VERSION "HNPBNNNYNNNNNNNNNNNNNNNNNNNNNNNNYNYYYYYYYY>4>%%%/4>'%**4YYY///"

NS_ :

BS_:

BU_: TPM TCM SCCM RF_HUB PTS ORC IC HaLF ETM ESM ESC EPS ECM Diagnost DTCM DASM CBC AFLS ADCM

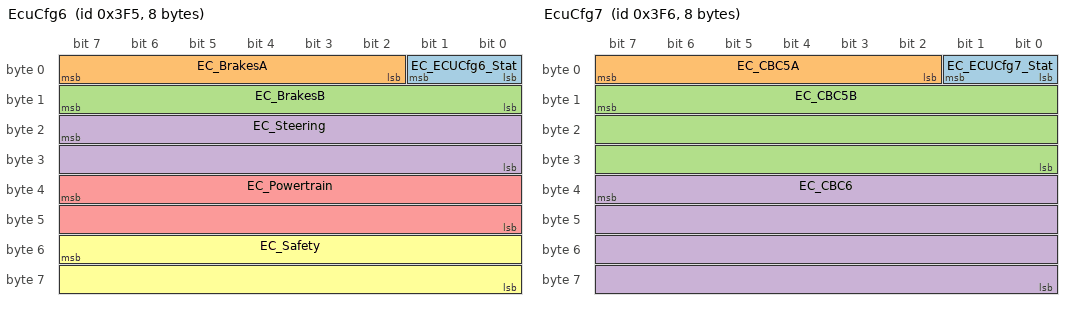
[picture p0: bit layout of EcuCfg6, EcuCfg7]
BO_ 1013 EcuCfg6: 8 CBC
 SG_ EC_ECUCfg6_Stat : 0|2@1+ (1,0) [0|0] ""  ORC,TCM,ECM,ESC,EPS,RF_HUB
 SG_ EC_BrakesA : 2|6@1+ (1,0) [0|0] ""  ESC,RF_HUB
 SG_ EC_BrakesB : 8|8@1+ (1,0) [0|0] ""  ESC,RF_HUB
 SG_ EC_Steering : 23|16@0+ (1,0) [0|0] ""  EPS,RF_HUB
 SG_ EC_Powertrain : 39|16@0+ (1,0) [0|0] ""  TCM,ECM,RF_HUB
 SG_ EC_Safety : 55|16@0+ (1,0) [0|0] ""  ORC,RF_HUB

BO_ 1014 EcuCfg7: 8 CBC
 SG_ EC_ECUCfg7_Stat : 0|2@1+ (1,0) [0|0] ""  RF_HUB
 SG_ EC_CBC5A : 2|6@1+ (1,0) [0|0] ""  RF_HUB
 SG_ EC_CBC5B : 15|24@0+ (1,0) [0|0] ""  RF_HUB
 SG_ EC_CBC6 : 39|32@0+ (1,0) [0|0] ""  RF_HUB

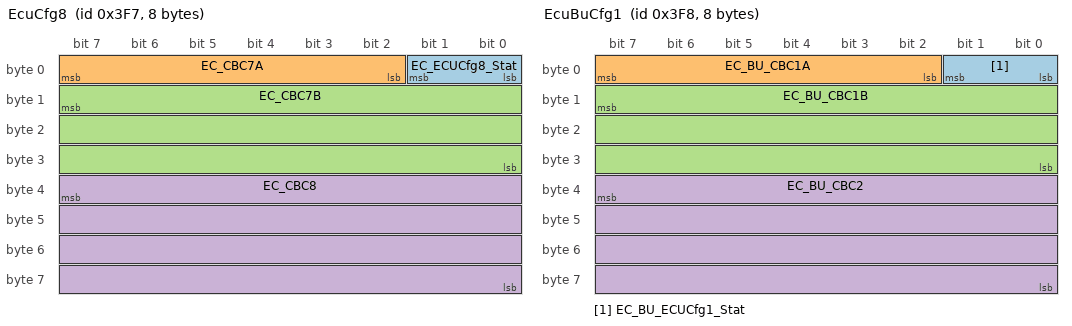
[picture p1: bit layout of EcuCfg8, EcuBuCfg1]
BO_ 1015 EcuCfg8: 8 CBC
 SG_ EC_ECUCfg8_Stat : 0|2@1+ (1,0) [0|0] ""  RF_HUB
 SG_ EC_CBC7A : 2|6@1+ (1,0) [0|0] ""  RF_HUB
 SG_ EC_CBC7B : 15|24@0+ (1,0) [0|0] ""  RF_HUB
 SG_ EC_CBC8 : 39|32@0+ (1,0) [0|0] ""  RF_HUB

BO_ 1016 EcuBuCfg1: 8 RF_HUB
 SG_ EC_BU_ECUCfg1_Stat : 0|2@1+ (1,0) [0|0] ""  CBC
 SG_ EC_BU_CBC1A : 2|6@1+ (1,0) [0|0] ""  CBC
 SG_ EC_BU_CBC1B : 15|24@0+ (1,0) [0|0] ""  CBC
 SG_ EC_BU_CBC2 : 39|32@0+ (1,0) [0|0] ""  CBC

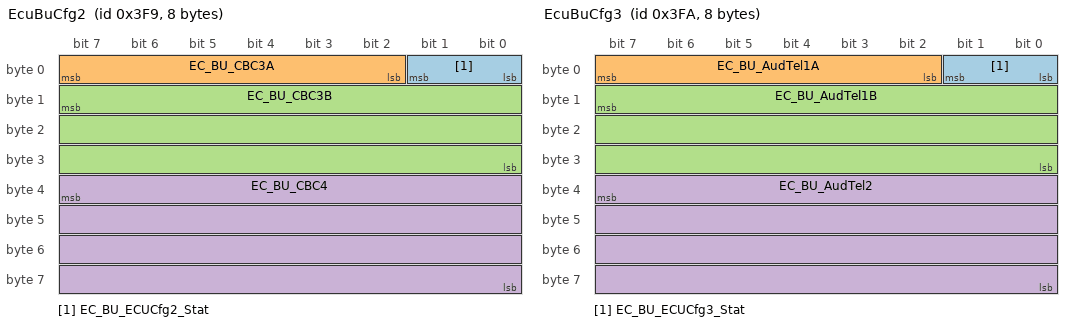
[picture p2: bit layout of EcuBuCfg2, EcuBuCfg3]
BO_ 1017 EcuBuCfg2: 8 RF_HUB
 SG_ EC_BU_ECUCfg2_Stat : 0|2@1+ (1,0) [0|0] ""  CBC
 SG_ EC_BU_CBC3A : 2|6@1+ (1,0) [0|0] ""  CBC
 SG_ EC_BU_CBC3B : 15|24@0+ (1,0) [0|0] ""  CBC
 SG_ EC_BU_CBC4 : 39|32@0+ (1,0) [0|0] ""  CBC

BO_ 1018 EcuBuCfg3: 8 RF_HUB
 SG_ EC_BU_ECUCfg3_Stat : 0|2@1+ (1,0) [0|0] ""  CBC
 SG_ EC_BU_AudTel1A : 2|6@1+ (1,0) [0|0] ""  CBC
 SG_ EC_BU_AudTel1B : 15|24@0+ (1,0) [0|0] ""  CBC
 SG_ EC_BU_AudTel2 : 39|32@0+ (1,0) [0|0] ""  CBC

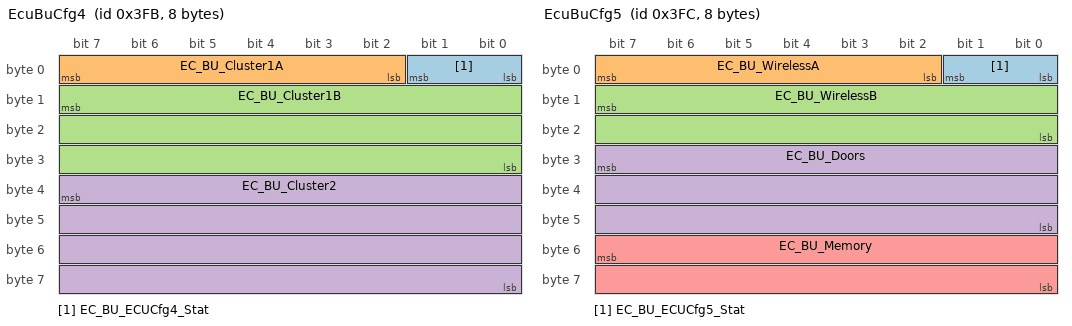
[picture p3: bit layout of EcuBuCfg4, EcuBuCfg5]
BO_ 1019 EcuBuCfg4: 8 RF_HUB
 SG_ EC_BU_ECUCfg4_Stat : 0|2@1+ (1,0) [0|0] ""  CBC
 SG_ EC_BU_Cluster1A : 2|6@1+ (1,0) [0|0] ""  CBC
 SG_ EC_BU_Cluster1B : 15|24@0+ (1,0) [0|0] ""  CBC
 SG_ EC_BU_Cluster2 : 39|32@0+ (1,0) [0|0] ""  CBC

BO_ 1020 EcuBuCfg5: 8 RF_HUB
 SG_ EC_BU_ECUCfg5_Stat : 0|2@1+ (1,0) [0|0] ""  CBC
 SG_ EC_BU_WirelessA : 2|6@1+ (1,0) [0|0] ""  CBC
 SG_ EC_BU_WirelessB : 15|16@0+ (1,0) [0|0] ""  CBC
 SG_ EC_BU_Doors : 31|24@0+ (1,0) [0|0] ""  CBC
 SG_ EC_BU_Memory : 55|16@0+ (1,0) [0|0] ""  CBC

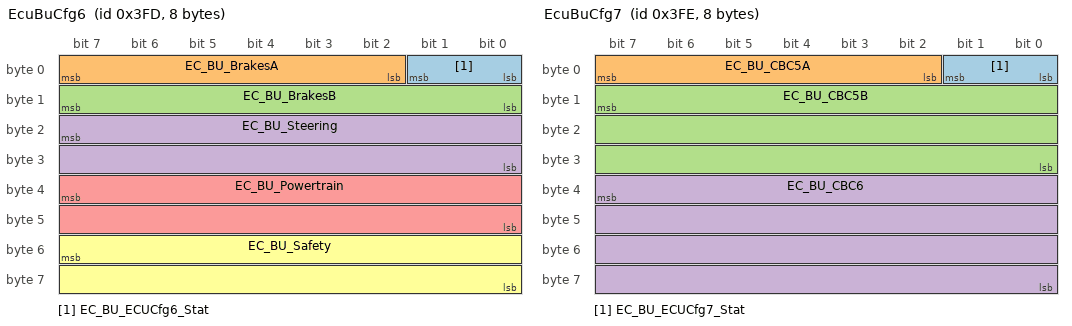
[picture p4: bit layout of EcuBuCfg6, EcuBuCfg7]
BO_ 1021 EcuBuCfg6: 8 RF_HUB
 SG_ EC_BU_ECUCfg6_Stat : 0|2@1+ (1,0) [0|0] ""  CBC
 SG_ EC_BU_BrakesA : 2|6@1+ (1,0) [0|0] ""  CBC
 SG_ EC_BU_BrakesB : 8|8@1+ (1,0) [0|0] ""  CBC
 SG_ EC_BU_Steering : 23|16@0+ (1,0) [0|0] ""  CBC
 SG_ EC_BU_Powertrain : 39|16@0+ (1,0) [0|0] ""  CBC
 SG_ EC_BU_Safety : 55|16@0+ (1,0) [0|0] ""  CBC

BO_ 1022 EcuBuCfg7: 8 RF_HUB
 SG_ EC_BU_ECUCfg7_Stat : 0|2@1+ (1,0) [0|0] ""  CBC
 SG_ EC_BU_CBC5A : 2|6@1+ (1,0) [0|0] ""  CBC
 SG_ EC_BU_CBC5B : 15|24@0+ (1,0) [0|0] ""  CBC
 SG_ EC_BU_CBC6 : 39|32@0+ (1,0) [0|0] ""  CBC

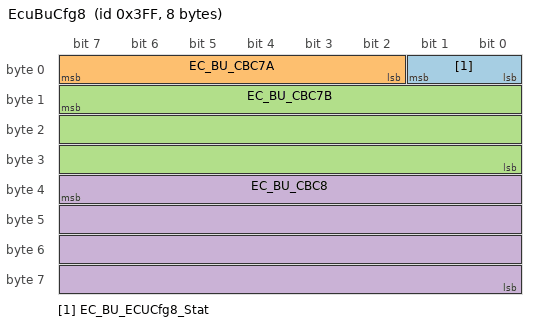
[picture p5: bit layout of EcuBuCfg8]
BO_ 1023 EcuBuCfg8: 8 RF_HUB
 SG_ EC_BU_ECUCfg8_Stat : 0|2@1+ (1,0) [0|0] ""  CBC
 SG_ EC_BU_CBC7A : 2|6@1+ (1,0) [0|0] ""  CBC
 SG_ EC_BU_CBC7B : 15|24@0+ (1,0) [0|0] ""  CBC
 SG_ EC_BU_CBC8 : 39|32@0+ (1,0) [0|0] ""  CBC

BO_ 1024 NM_RF_HUB: 8 RF_HUB
 SG_ NM_Mode : 0|8@1+ (1,0) [0|0] ""  ESM,ESC,SCCM,EPS,TPM,PTS,IC,CBC,RF_HUB
 SG_ NM_Successor : 8|8@1+ (1,0) [0|63] ""  ESM,ESC,SCCM,EPS,TPM,PTS,IC,CBC,RF_HUB
 SG_ NM_Ud_Launch : 16|6@1+ (1,0) [0|0] ""  ESM,ESC,SCCM,EPS,TPM,PTS,IC,CBC,RF_HUB
 SG_ NM_Sleep_Ack : 22|1@1+ (1,0) [0|0] ""  ESM,ESC,SCCM,EPS,TPM,PTS,IC,CBC,RF_HUB
 SG_ NM_Sleep_Ind : 23|1@1+ (1,0) [0|0] ""  ESM,ESC,SCCM,EPS,TPM,PTS,IC,CBC,RF_HUB
 SG_ NM_Ud_Srv M : 24|8@1+ (1,0) [0|0] ""  ESM,ESC,SCCM,EPS,TPM,PTS,IC,CBC,RF_HUB
 SG_ Awake_NwSt m15 : 32|1@1+ (1,0) [0|0] ""  ESM,ESC,SCCM,EPS,TPM,PTS,IC,CBC,RF_HUB
 SG_ WakeupRsn_RF_HUB m2 : 32|8@1+ (1,0) [0|0] ""  ESM,ESC,SCCM,EPS,TPM,PTS,IC,CBC,RF_HUB
 SG_ Awake_Diag_Actv m15 : 33|1@1+ (1,0) [0|0] ""  ESM,ESC,SCCM,EPS,TPM,PTS,IC,CBC,RF_HUB
 SG_ WakeupCnt m2 : 40|8@1+ (1,0) [0|254] ""  ESM,ESC,SCCM,EPS,TPM,PTS,IC,CBC,RF_HUB
 SG_ Nw_Id : 56|8@1+ (1,0) [0|0] ""  ESM,ESC,SCCM,EPS,TPM,PTS,IC,CBC,RF_HUB

BO_ 1025 NM_CBC: 8 CBC
 SG_ NM_Mode : 0|8@1+ (1,0) [0|0] ""  ESM,ESC,SCCM,EPS,TPM,PTS,IC,CBC,RF_HUB
 SG_ NM_Successor : 8|8@1+ (1,0) [0|63] ""  ESM,ESC,SCCM,EPS,TPM,PTS,IC,CBC,RF_HUB
 SG_ NM_Ud_Launch : 16|6@1+ (1,0) [0|0] ""  ESM,ESC,SCCM,EPS,TPM,PTS,IC,CBC,RF_HUB
 SG_ NM_Sleep_Ack : 22|1@1+ (1,0) [0|0] ""  ESM,ESC,SCCM,EPS,TPM,PTS,IC,CBC,RF_HUB
 SG_ NM_Sleep_Ind : 23|1@1+ (1,0) [0|0] ""  ESM,ESC,SCCM,EPS,TPM,PTS,IC,CBC,RF_HUB
 SG_ NM_Ud_Srv M : 24|8@1+ (1,0) [0|0] ""  ESM,ESC,SCCM,EPS,TPM,PTS,IC,CBC,RF_HUB
 SG_ Awake_NwSt m15 : 32|1@1+ (1,0) [0|0] ""  ESM,ESC,SCCM,EPS,TPM,PTS,IC,CBC,RF_HUB
 SG_ WakeupRsn_CBC m2 : 32|8@1+ (1,0) [0|0] ""  ESM,ESC,SCCM,EPS,TPM,PTS,IC,CBC,RF_HUB
 SG_ Awake_Diag_Actv m15 : 33|1@1+ (1,0) [0|0] ""  ESM,ESC,SCCM,EPS,TPM,PTS,IC,CBC,RF_HUB
 SG_ WakeupCnt m2 : 40|8@1+ (1,0) [0|254] ""  ESM,ESC,SCCM,EPS,TPM,PTS,IC,CBC,RF_HUB
 SG_ Nw_Id : 56|8@1+ (1,0) [0|0] ""  ESM,ESC,SCCM,EPS,TPM,PTS,IC,CBC,RF_HUB

BO_ 1026 NM_IC: 8 IC
 SG_ NM_Mode : 0|8@1+ (1,0) [0|0] ""  ESM,ESC,SCCM,EPS,TPM,PTS,IC,CBC,RF_HUB
 SG_ NM_Successor : 8|8@1+ (1,0) [0|63] ""  ESM,ESC,SCCM,EPS,TPM,PTS,IC,CBC,RF_HUB
 SG_ NM_Ud_Launch : 16|6@1+ (1,0) [0|0] ""  ESM,ESC,SCCM,EPS,TPM,PTS,IC,CBC,RF_HUB
 SG_ NM_Sleep_Ack : 22|1@1+ (1,0) [0|0] ""  ESM,ESC,SCCM,EPS,TPM,PTS,IC,CBC,RF_HUB
 SG_ NM_Sleep_Ind : 23|1@1+ (1,0) [0|0] ""  ESM,ESC,SCCM,EPS,TPM,PTS,IC,CBC,RF_HUB
 SG_ NM_Ud_Srv M : 24|8@1+ (1,0) [0|0] ""  ESM,ESC,SCCM,EPS,TPM,PTS,IC,CBC,RF_HUB
 SG_ Awake_NwSt m15 : 32|1@1+ (1,0) [0|0] ""  ESM,ESC,SCCM,EPS,TPM,PTS,IC,CBC,RF_HUB
 SG_ WakeupRsn_IC m2 : 32|8@1+ (1,0) [0|0] ""  ESM,ESC,SCCM,EPS,TPM,PTS,IC,CBC,RF_HUB
 SG_ Awake_Diag_Actv m15 : 33|1@1+ (1,0) [0|0] ""  ESM,ESC,SCCM,EPS,TPM,PTS,IC,CBC,RF_HUB
 SG_ WakeupCnt m2 : 40|8@1+ (1,0) [0|254] ""  ESM,ESC,SCCM,EPS,TPM,PTS,IC,CBC,RF_HUB
 SG_ Nw_Id : 56|8@1+ (1,0) [0|0] ""  ESM,ESC,SCCM,EPS,TPM,PTS,IC,CBC,RF_HUB

BO_ 1027 NM_TPM: 8 TPM
 SG_ NM_Mode : 0|8@1+ (1,0) [0|0] ""  ESM,ESC,SCCM,EPS,TPM,PTS,IC,CBC,RF_HUB
 SG_ NM_Successor : 8|8@1+ (1,0) [0|63] ""  ESM,ESC,SCCM,EPS,TPM,PTS,IC,CBC,RF_HUB
 SG_ NM_Ud_Launch : 16|6@1+ (1,0) [0|0] ""  ESM,ESC,SCCM,EPS,TPM,PTS,IC,CBC,RF_HUB
 SG_ NM_Sleep_Ack : 22|1@1+ (1,0) [0|0] ""  ESM,ESC,SCCM,EPS,TPM,PTS,IC,CBC,RF_HUB
 SG_ NM_Sleep_Ind : 23|1@1+ (1,0) [0|0] ""  ESM,ESC,SCCM,EPS,TPM,PTS,IC,CBC,RF_HUB
 SG_ NM_Ud_Srv M : 24|8@1+ (1,0) [0|0] ""  ESM,ESC,SCCM,EPS,TPM,PTS,IC,CBC,RF_HUB
 SG_ Awake_NwSt m15 : 32|1@1+ (1,0) [0|0] ""  ESM,ESC,SCCM,EPS,TPM,PTS,IC,CBC,RF_HUB
 SG_ WakeupRsn_TPM m2 : 32|8@1+ (1,0) [0|0] ""  ESM,ESC,SCCM,EPS,TPM,PTS,IC,CBC,RF_HUB
 SG_ Awake_Diag_Actv m15 : 33|1@1+ (1,0) [0|0] ""  ESM,ESC,SCCM,EPS,TPM,PTS,IC,CBC,RF_HUB
 SG_ WakeupCnt m2 : 40|8@1+ (1,0) [0|254] ""  ESM,ESC,SCCM,EPS,TPM,PTS,IC,CBC,RF_HUB
 SG_ Nw_Id : 56|8@1+ (1,0) [0|0] ""  ESM,ESC,SCCM,EPS,TPM,PTS,IC,CBC,RF_HUB

BO_ 1029 NM_RBT_D: 8 Vector__XXX
 SG_ NM_Mode : 0|8@1+ (1,0) [0|0] ""  ESM,ESC,SCCM,EPS,TPM,PTS,IC,CBC,RF_HUB
 SG_ NM_Successor : 8|8@1+ (1,0) [0|63] ""  ESM,ESC,SCCM,EPS,TPM,PTS,IC,CBC,RF_HUB
 SG_ NM_Ud_Launch : 16|6@1+ (1,0) [0|0] ""  ESM,ESC,SCCM,EPS,TPM,PTS,IC,CBC,RF_HUB
 SG_ NM_Sleep_Ack : 22|1@1+ (1,0) [0|0] ""  ESM,ESC,SCCM,EPS,TPM,PTS,IC,CBC,RF_HUB
 SG_ NM_Sleep_Ind : 23|1@1+ (1,0) [0|0] ""  ESM,ESC,SCCM,EPS,TPM,PTS,IC,CBC,RF_HUB
 SG_ NM_Ud_Srv M : 24|8@1+ (1,0) [0|0] ""  ESM,ESC,SCCM,EPS,TPM,PTS,IC,CBC,RF_HUB
 SG_ Awake_NwSt m15 : 32|1@1+ (1,0) [0|0] ""  ESM,ESC,SCCM,EPS,TPM,PTS,IC,CBC,RF_HUB
 SG_ WakeupRsn_RBT_DR m2 : 32|8@1+ (1,0) [0|0] ""  ESM,ESC,SCCM,EPS,TPM,PTS,IC,CBC,RF_HUB
 SG_ Awake_Diag_Actv m15 : 33|1@1+ (1,0) [0|0] ""  ESM,ESC,SCCM,EPS,TPM,PTS,IC,CBC,RF_HUB
 SG_ WakeupCnt m2 : 40|8@1+ (1,0) [0|254] ""  ESM,ESC,SCCM,EPS,TPM,PTS,IC,CBC,RF_HUB
 SG_ Nw_Id : 56|8@1+ (1,0) [0|0] ""  ESM,ESC,SCCM,EPS,TPM,PTS,IC,CBC,RF_HUB

BO_ 1030 NM_RBT_P: 8 Vector__XXX
 SG_ NM_Mode : 0|8@1+ (1,0) [0|0] ""  ESM,ESC,SCCM,EPS,TPM,PTS,IC,CBC,RF_HUB
 SG_ NM_Successor : 8|8@1+ (1,0) [0|63] ""  ESM,ESC,SCCM,EPS,TPM,PTS,IC,CBC,RF_HUB
 SG_ NM_Ud_Launch : 16|6@1+ (1,0) [0|0] ""  ESM,ESC,SCCM,EPS,TPM,PTS,IC,CBC,RF_HUB
 SG_ NM_Sleep_Ack : 22|1@1+ (1,0) [0|0] ""  ESM,ESC,SCCM,EPS,TPM,PTS,IC,CBC,RF_HUB
 SG_ NM_Sleep_Ind : 23|1@1+ (1,0) [0|0] ""  ESM,ESC,SCCM,EPS,TPM,PTS,IC,CBC,RF_HUB
 SG_ NM_Ud_Srv M : 24|8@1+ (1,0) [0|0] ""  ESM,ESC,SCCM,EPS,TPM,PTS,IC,CBC,RF_HUB
 SG_ Awake_NwSt m15 : 32|1@1+ (1,0) [0|0] ""  ESM,ESC,SCCM,EPS,TPM,PTS,IC,CBC,RF_HUB
 SG_ WakeupRsn_RBT_PASS m2 : 32|8@1+ (1,0) [0|0] ""  ESM,ESC,SCCM,EPS,TPM,PTS,IC,CBC,RF_HUB
 SG_ Awake_Diag_Actv m15 : 33|1@1+ (1,0) [0|0] ""  ESM,ESC,SCCM,EPS,TPM,PTS,IC,CBC,RF_HUB
 SG_ WakeupCnt m2 : 40|8@1+ (1,0) [0|254] ""  ESM,ESC,SCCM,EPS,TPM,PTS,IC,CBC,RF_HUB
 SG_ Nw_Id : 56|8@1+ (1,0) [0|0] ""  ESM,ESC,SCCM,EPS,TPM,PTS,IC,CBC,RF_HUB

BO_ 1031 NM_ESC: 8 ESC
 SG_ NM_Mode : 0|8@1+ (1,0) [0|0] ""  ESM,ESC,SCCM,EPS,TPM,PTS,IC,CBC,RF_HUB
 SG_ NM_Successor : 8|8@1+ (1,0) [0|63] ""  ESM,ESC,SCCM,EPS,TPM,PTS,IC,CBC,RF_HUB
 SG_ NM_Ud_Launch : 16|6@1+ (1,0) [0|0] ""  ESM,ESC,SCCM,EPS,TPM,PTS,IC,CBC,RF_HUB
 SG_ NM_Sleep_Ack : 22|1@1+ (1,0) [0|0] ""  ESM,ESC,SCCM,EPS,TPM,PTS,IC,CBC,RF_HUB
 SG_ NM_Sleep_Ind : 23|1@1+ (1,0) [0|0] ""  ESM,ESC,SCCM,EPS,TPM,PTS,IC,CBC,RF_HUB
 SG_ NM_Ud_Srv M : 24|8@1+ (1,0) [0|0] ""  ESM,ESC,SCCM,EPS,TPM,PTS,IC,CBC,RF_HUB
 SG_ Awake_NwSt m15 : 32|1@1+ (1,0) [0|0] ""  ESM,ESC,SCCM,EPS,TPM,PTS,IC,CBC,RF_HUB
 SG_ WakeupRsn_ESC m2 : 32|8@1+ (1,0) [0|0] ""  ESM,ESC,SCCM,EPS,TPM,PTS,IC,CBC,RF_HUB
 SG_ Awake_Diag_Actv m15 : 33|1@1+ (1,0) [0|0] ""  ESM,ESC,SCCM,EPS,TPM,PTS,IC,CBC,RF_HUB
 SG_ WakeupCnt m2 : 40|8@1+ (1,0) [0|254] ""  ESM,ESC,SCCM,EPS,TPM,PTS,IC,CBC,RF_HUB
 SG_ Nw_Id : 56|8@1+ (1,0) [0|0] ""  ESM,ESC,SCCM,EPS,TPM,PTS,IC,CBC,RF_HUB

BO_ 1033 NM_SBWM: 8 ESM
 SG_ NM_Mode : 0|8@1+ (1,0) [0|0] ""  ESM,ESC,SCCM,EPS,TPM,PTS,IC,CBC,RF_HUB
 SG_ NM_Successor : 8|8@1+ (1,0) [0|63] ""  ESM,ESC,SCCM,EPS,TPM,PTS,IC,CBC,RF_HUB
 SG_ NM_Ud_Launch : 16|6@1+ (1,0) [0|0] ""  ESM,ESC,SCCM,EPS,TPM,PTS,IC,CBC,RF_HUB
 SG_ NM_Sleep_Ack : 22|1@1+ (1,0) [0|0] ""  ESM,ESC,SCCM,EPS,TPM,PTS,IC,CBC,RF_HUB
 SG_ NM_Sleep_Ind : 23|1@1+ (1,0) [0|0] ""  ESM,ESC,SCCM,EPS,TPM,PTS,IC,CBC,RF_HUB
 SG_ NM_Ud_Srv M : 24|8@1+ (1,0) [0|0] ""  ESM,ESC,SCCM,EPS,TPM,PTS,IC,CBC,RF_HUB
 SG_ Awake_NwSt m15 : 32|1@1+ (1,0) [0|0] ""  ESM,ESC,SCCM,EPS,TPM,PTS,IC,CBC,RF_HUB
 SG_ WakeupRsn_SBWM m2 : 32|8@1+ (1,0) [0|0] ""  ESM,ESC,SCCM,EPS,TPM,PTS,IC,CBC,RF_HUB
 SG_ Awake_Diag_Actv m15 : 33|1@1+ (1,0) [0|0] ""  ESM,ESC,SCCM,EPS,TPM,PTS,IC,CBC,RF_HUB
 SG_ Awake_Ignition_On m15 : 34|1@1+ (1,0) [0|0] ""  ESM,ESC,SCCM,EPS,TPM,PTS,IC,CBC,RF_HUB
 SG_ Awake_EEPROM m15 : 35|1@1+ (1,0) [0|0] ""  ESM,ESC,SCCM,EPS,TPM,PTS,IC,CBC,RF_HUB
 SG_ Awake_URS m15 : 36|1@1+ (1,0) [0|0] ""  ESM,ESC,SCCM,EPS,TPM,PTS,IC,CBC,RF_HUB
 SG_ WakeupCnt m2 : 40|8@1+ (1,0) [0|254] ""  ESM,ESC,SCCM,EPS,TPM,PTS,IC,CBC,RF_HUB
 SG_ Nw_Id : 56|8@1+ (1,0) [0|0] ""  ESM,ESC,SCCM,EPS,TPM,PTS,IC,CBC,RF_HUB

BO_ 1044 NM_ITBM: 8 Vector__XXX
 SG_ NM_Mode : 0|8@1+ (1,0) [0|0] ""  ESM,ESC,SCCM,EPS,TPM,PTS,IC,CBC,RF_HUB
 SG_ NM_Successor : 8|8@1+ (1,0) [0|63] ""  ESM,ESC,SCCM,EPS,TPM,PTS,IC,CBC,RF_HUB
 SG_ NM_Ud_Launch : 16|6@1+ (1,0) [0|0] ""  ESM,ESC,SCCM,EPS,TPM,PTS,IC,CBC,RF_HUB
 SG_ NM_Sleep_Ack : 22|1@1+ (1,0) [0|0] ""  ESM,ESC,SCCM,EPS,TPM,PTS,IC,CBC,RF_HUB
 SG_ NM_Sleep_Ind : 23|1@1+ (1,0) [0|0] ""  ESM,ESC,SCCM,EPS,TPM,PTS,IC,CBC,RF_HUB
 SG_ NM_Ud_Srv M : 24|8@1+ (1,0) [0|0] ""  ESM,ESC,SCCM,EPS,TPM,PTS,IC,CBC,RF_HUB
 SG_ Awake_NwSt m15 : 32|1@1+ (1,0) [0|0] ""  ESM,ESC,SCCM,EPS,TPM,PTS,IC,CBC,RF_HUB
 SG_ WakeupRsn_ITBM m2 : 32|8@1+ (1,0) [0|0] ""  ESM,ESC,SCCM,EPS,TPM,PTS,IC,CBC,RF_HUB
 SG_ Awake_Diag_Actv m15 : 33|1@1+ (1,0) [0|0] ""  ESM,ESC,SCCM,EPS,TPM,PTS,IC,CBC,RF_HUB
 SG_ WakeupCnt m2 : 40|8@1+ (1,0) [0|254] ""  ESM,ESC,SCCM,EPS,TPM,PTS,IC,CBC,RF_HUB
 SG_ Nw_Id : 56|8@1+ (1,0) [0|0] ""  ESM,ESC,SCCM,EPS,TPM,PTS,IC,CBC,RF_HUB

BO_ 1049 NM_EPB: 8 Vector__XXX
 SG_ NM_Mode : 0|8@1+ (1,0) [0|0] ""  ESM,ESC,SCCM,EPS,TPM,PTS,IC,CBC,RF_HUB
 SG_ NM_Successor : 8|8@1+ (1,0) [0|63] ""  ESM,ESC,SCCM,EPS,TPM,PTS,IC,CBC,RF_HUB
 SG_ NM_Ud_Launch : 16|6@1+ (1,0) [0|0] ""  ESM,ESC,SCCM,EPS,TPM,PTS,IC,CBC,RF_HUB
 SG_ NM_Sleep_Ack : 22|1@1+ (1,0) [0|0] ""  ESM,ESC,SCCM,EPS,TPM,PTS,IC,CBC,RF_HUB
 SG_ NM_Sleep_Ind : 23|1@1+ (1,0) [0|0] ""  ESM,ESC,SCCM,EPS,TPM,PTS,IC,CBC,RF_HUB
 SG_ NM_Ud_Srv M : 24|8@1+ (1,0) [0|0] ""  ESM,ESC,SCCM,EPS,TPM,PTS,IC,CBC,RF_HUB
 SG_ Awake_NwSt m15 : 32|1@1+ (1,0) [0|0] ""  ESM,ESC,SCCM,EPS,TPM,PTS,IC,CBC,RF_HUB
 SG_ WakeupRsn_EPB m2 : 32|8@1+ (1,0) [0|0] ""  ESM,ESC,SCCM,EPS,TPM,PTS,IC,CBC,RF_HUB
 SG_ Awake_Diag_Actv m15 : 33|1@1+ (1,0) [0|0] ""  ESM,ESC,SCCM,EPS,TPM,PTS,IC,CBC,RF_HUB
 SG_ WakeupCnt m2 : 40|8@1+ (1,0) [0|254] ""  ESM,ESC,SCCM,EPS,TPM,PTS,IC,CBC,RF_HUB
 SG_ Nw_Id : 56|8@1+ (1,0) [0|0] ""  ESM,ESC,SCCM,EPS,TPM,PTS,IC,CBC,RF_HUB

BO_ 1050 NM_EPS: 8 EPS
 SG_ NM_Mode : 0|8@1+ (1,0) [0|0] ""  ESM,ESC,SCCM,EPS,TPM,PTS,IC,CBC,RF_HUB
 SG_ NM_Successor : 8|8@1+ (1,0) [0|63] ""  ESM,ESC,SCCM,EPS,TPM,PTS,IC,CBC,RF_HUB
 SG_ NM_Ud_Launch : 16|6@1+ (1,0) [0|0] ""  ESM,ESC,SCCM,EPS,TPM,PTS,IC,CBC,RF_HUB
 SG_ NM_Sleep_Ack : 22|1@1+ (1,0) [0|0] ""  ESM,ESC,SCCM,EPS,TPM,PTS,IC,CBC,RF_HUB
 SG_ NM_Sleep_Ind : 23|1@1+ (1,0) [0|0] ""  ESM,ESC,SCCM,EPS,TPM,PTS,IC,CBC,RF_HUB
 SG_ NM_Ud_Srv M : 24|8@1+ (1,0) [0|0] ""  ESM,ESC,SCCM,EPS,TPM,PTS,IC,CBC,RF_HUB
 SG_ Awake_NwSt m15 : 32|1@1+ (1,0) [0|0] ""  ESM,ESC,SCCM,EPS,TPM,PTS,IC,CBC,RF_HUB
 SG_ WakeupRsn_EPS m2 : 32|8@1+ (1,0) [0|0] ""  ESM,ESC,SCCM,EPS,TPM,PTS,IC,CBC,RF_HUB
 SG_ Awake_Diag_Actv m15 : 33|1@1+ (1,0) [0|0] ""  ESM,ESC,SCCM,EPS,TPM,PTS,IC,CBC,RF_HUB
 SG_ Awake_Rampout m15 : 34|1@1+ (1,0) [0|0] ""  ESM,ESC,SCCM,EPS,TPM,PTS,IC,CBC,RF_HUB
 SG_ Awake_VSS_high m15 : 35|1@1+ (1,0) [0|0] ""  ESM,ESC,SCCM,EPS,TPM,PTS,IC,CBC,RF_HUB
 SG_ Awake_EngRPM_high m15 : 36|1@1+ (1,0) [0|0] ""  ESM,ESC,SCCM,EPS,TPM,PTS,IC,CBC,RF_HUB
 SG_ Awake_IgnHigh m15 : 37|1@1+ (1,0) [0|0] ""  ESM,ESC,SCCM,EPS,TPM,PTS,IC,CBC,RF_HUB
 SG_ WakeupCnt m2 : 40|8@1+ (1,0) [0|254] ""  ESM,ESC,SCCM,EPS,TPM,PTS,IC,CBC,RF_HUB
 SG_ Nw_Id : 56|8@1+ (1,0) [0|0] ""  ESM,ESC,SCCM,EPS,TPM,PTS,IC,CBC,RF_HUB

BO_ 1058 NM_PTS: 8 PTS
 SG_ NM_Mode : 0|8@1+ (1,0) [0|0] ""  ESM,ESC,SCCM,EPS,TPM,PTS,IC,CBC,RF_HUB
 SG_ NM_Successor : 8|8@1+ (1,0) [0|63] ""  ESM,ESC,SCCM,EPS,TPM,PTS,IC,CBC,RF_HUB
 SG_ NM_Ud_Launch : 16|6@1+ (1,0) [0|0] ""  ESM,ESC,SCCM,EPS,TPM,PTS,IC,CBC,RF_HUB
 SG_ NM_Sleep_Ack : 22|1@1+ (1,0) [0|0] ""  ESM,ESC,SCCM,EPS,TPM,PTS,IC,CBC,RF_HUB
 SG_ NM_Sleep_Ind : 23|1@1+ (1,0) [0|0] ""  ESM,ESC,SCCM,EPS,TPM,PTS,IC,CBC,RF_HUB
 SG_ NM_Ud_Srv M : 24|8@1+ (1,0) [0|0] ""  ESM,ESC,SCCM,EPS,TPM,PTS,IC,CBC,RF_HUB
 SG_ Awake_NwSt m15 : 32|1@1+ (1,0) [0|0] ""  ESM,ESC,SCCM,EPS,TPM,PTS,IC,CBC,RF_HUB
 SG_ WakeupRsn_PTS m2 : 32|8@1+ (1,0) [0|0] ""  ESM,ESC,SCCM,EPS,TPM,PTS,IC,CBC,RF_HUB
 SG_ Awake_Diag_Actv m15 : 33|1@1+ (1,0) [0|0] ""  ESM,ESC,SCCM,EPS,TPM,PTS,IC,CBC,RF_HUB
 SG_ WakeupCnt m2 : 40|8@1+ (1,0) [0|254] ""  ESM,ESC,SCCM,EPS,TPM,PTS,IC,CBC,RF_HUB
 SG_ Nw_Id : 56|8@1+ (1,0) [0|0] ""  ESM,ESC,SCCM,EPS,TPM,PTS,IC,CBC,RF_HUB

BO_ 1059 NM_SCCM: 8 SCCM
 SG_ NM_Mode : 0|8@1+ (1,0) [0|0] ""  ESM,ESC,SCCM,EPS,TPM,PTS,IC,CBC,RF_HUB
 SG_ NM_Successor : 8|8@1+ (1,0) [0|63] ""  ESM,ESC,SCCM,EPS,TPM,PTS,IC,CBC,RF_HUB
 SG_ NM_Ud_Launch : 16|6@1+ (1,0) [0|0] ""  ESM,ESC,SCCM,EPS,TPM,PTS,IC,CBC,RF_HUB
 SG_ NM_Sleep_Ack : 22|1@1+ (1,0) [0|0] ""  ESM,ESC,SCCM,EPS,TPM,PTS,IC,CBC,RF_HUB
 SG_ NM_Sleep_Ind : 23|1@1+ (1,0) [0|0] ""  ESM,ESC,SCCM,EPS,TPM,PTS,IC,CBC,RF_HUB
 SG_ NM_Ud_Srv M : 24|8@1+ (1,0) [0|0] ""  ESM,ESC,SCCM,EPS,TPM,PTS,IC,CBC,RF_HUB
 SG_ Awake_NwSt m15 : 32|1@1+ (1,0) [0|0] ""  ESM,ESC,SCCM,EPS,TPM,PTS,IC,CBC,RF_HUB
 SG_ WakeupRsn_SCCM m2 : 32|8@1+ (1,0) [0|0] ""  ESM,ESC,SCCM,EPS,TPM,PTS,IC,CBC,RF_HUB
 SG_ Awake_Diag_Actv m15 : 33|1@1+ (1,0) [0|0] ""  ESM,ESC,SCCM,EPS,TPM,PTS,IC,CBC,RF_HUB
 SG_ Awake_StwSw_Actv m15 : 34|1@1+ (1,0) [0|0] ""  ESM,ESC,SCCM,EPS,TPM,PTS,IC,CBC,RF_HUB
 SG_ Awake_Ignition_On m15 : 35|1@1+ (1,0) [0|0] ""  ESM,ESC,SCCM,EPS,TPM,PTS,IC,CBC,RF_HUB
 SG_ Awake_EEPROM m15 : 36|1@1+ (1,0) [0|0] ""  ESM,ESC,SCCM,EPS,TPM,PTS,IC,CBC,RF_HUB
 SG_ Awake_tilt_tel_Psd m15 : 37|1@1+ (1,0) [0|0] ""  ESM,ESC,SCCM,EPS,TPM,PTS,IC,CBC,RF_HUB
 SG_ Awake_FTP_Psd m15 : 38|1@1+ (1,0) [0|0] ""  ESM,ESC,SCCM,EPS,TPM,PTS,IC,CBC,RF_HUB
 SG_ Awake_HrnSwt_Actv m15 : 39|1@1+ (1,0) [0|0] ""  ESM,ESC,SCCM,EPS,TPM,PTS,IC,CBC,RF_HUB
 SG_ WakeupCnt m2 : 40|8@1+ (1,0) [0|254] ""  ESM,ESC,SCCM,EPS,TPM,PTS,IC,CBC,RF_HUB
 SG_ Nw_Id : 56|8@1+ (1,0) [0|0] ""  ESM,ESC,SCCM,EPS,TPM,PTS,IC,CBC,RF_HUB

BO_ 1061 NM_ANC: 8 Vector__XXX
 SG_ NM_Mode : 0|8@1+ (1,0) [0|0] ""  ESM,ESC,SCCM,EPS,TPM,PTS,IC,CBC,RF_HUB
 SG_ NM_Successor : 8|8@1+ (1,0) [0|63] ""  ESM,ESC,SCCM,EPS,TPM,PTS,IC,CBC,RF_HUB
 SG_ NM_Ud_Launch : 16|6@1+ (1,0) [0|0] ""  ESM,ESC,SCCM,EPS,TPM,PTS,IC,CBC,RF_HUB
 SG_ NM_Sleep_Ack : 22|1@1+ (1,0) [0|0] ""  ESM,ESC,SCCM,EPS,TPM,PTS,IC,CBC,RF_HUB
 SG_ NM_Sleep_Ind : 23|1@1+ (1,0) [0|0] ""  ESM,ESC,SCCM,EPS,TPM,PTS,IC,CBC,RF_HUB
 SG_ NM_Ud_Srv M : 24|8@1+ (1,0) [0|0] ""  ESM,ESC,SCCM,EPS,TPM,PTS,IC,CBC,RF_HUB
 SG_ Awake_NwSt m15 : 32|1@1+ (1,0) [0|0] ""  ESM,ESC,SCCM,EPS,TPM,PTS,IC,CBC,RF_HUB
 SG_ WakeupRsn_ANC m2 : 32|8@1+ (1,0) [0|0] ""  ESM,ESC,SCCM,EPS,TPM,PTS,IC,CBC,RF_HUB
 SG_ Awake_Diag_Actv m15 : 33|1@1+ (1,0) [0|0] ""  ESM,ESC,SCCM,EPS,TPM,PTS,IC,CBC,RF_HUB
 SG_ WakeupCnt m2 : 40|8@1+ (1,0) [0|254] ""  ESM,ESC,SCCM,EPS,TPM,PTS,IC,CBC,RF_HUB
 SG_ Nw_Id : 56|8@1+ (1,0) [0|0] ""  ESM,ESC,SCCM,EPS,TPM,PTS,IC,CBC,RF_HUB

BO_ 1062 NM_ASCM: 8 Vector__XXX
 SG_ NM_Mode : 0|8@1+ (1,0) [0|0] ""  ESM,ESC,SCCM,EPS,TPM,PTS,IC,CBC,RF_HUB
 SG_ NM_Successor : 8|8@1+ (1,0) [0|63] ""  ESM,ESC,SCCM,EPS,TPM,PTS,IC,CBC,RF_HUB
 SG_ NM_Ud_Launch : 16|6@1+ (1,0) [0|0] ""  ESM,ESC,SCCM,EPS,TPM,PTS,IC,CBC,RF_HUB
 SG_ NM_Sleep_Ack : 22|1@1+ (1,0) [0|0] ""  ESM,ESC,SCCM,EPS,TPM,PTS,IC,CBC,RF_HUB
 SG_ NM_Sleep_Ind : 23|1@1+ (1,0) [0|0] ""  ESM,ESC,SCCM,EPS,TPM,PTS,IC,CBC,RF_HUB
 SG_ NM_Ud_Srv M : 24|8@1+ (1,0) [0|0] ""  ESM,ESC,SCCM,EPS,TPM,PTS,IC,CBC,RF_HUB
 SG_ Awake_NwSt m15 : 32|1@1+ (1,0) [0|0] ""  ESM,ESC,SCCM,EPS,TPM,PTS,IC,CBC,RF_HUB
 SG_ WakeupRsn_ASCM m2 : 32|8@1+ (1,0) [0|0] ""  ESM,ESC,SCCM,EPS,TPM,PTS,IC,CBC,RF_HUB
 SG_ Awake_Diag_Actv m15 : 33|1@1+ (1,0) [0|0] ""  ESM,ESC,SCCM,EPS,TPM,PTS,IC,CBC,RF_HUB
 SG_ WakeupCnt m2 : 40|8@1+ (1,0) [0|254] ""  ESM,ESC,SCCM,EPS,TPM,PTS,IC,CBC,RF_HUB
 SG_ Nw_Id : 56|8@1+ (1,0) [0|0] ""  ESM,ESC,SCCM,EPS,TPM,PTS,IC,CBC,RF_HUB

BO_ 1073 NM_VSIM_C: 8 Vector__XXX
 SG_ NM_Mode : 0|8@1+ (1,0) [0|0] ""  ESM,ESC,SCCM,EPS,TPM,PTS,IC,CBC,RF_HUB
 SG_ NM_Successor : 8|8@1+ (1,0) [0|63] ""  ESM,ESC,SCCM,EPS,TPM,PTS,IC,CBC,RF_HUB
 SG_ NM_Ud_Launch : 16|6@1+ (1,0) [0|0] ""  ESM,ESC,SCCM,EPS,TPM,PTS,IC,CBC,RF_HUB
 SG_ NM_Sleep_Ack : 22|1@1+ (1,0) [0|0] ""  ESM,ESC,SCCM,EPS,TPM,PTS,IC,CBC,RF_HUB
 SG_ NM_Sleep_Ind : 23|1@1+ (1,0) [0|0] ""  ESM,ESC,SCCM,EPS,TPM,PTS,IC,CBC,RF_HUB
 SG_ NM_Ud_Srv M : 24|8@1+ (1,0) [0|0] ""  ESM,ESC,SCCM,EPS,TPM,PTS,IC,CBC,RF_HUB
 SG_ Awake_NwSt m15 : 32|1@1+ (1,0) [0|0] ""  ESM,ESC,SCCM,EPS,TPM,PTS,IC,CBC,RF_HUB
 SG_ WakeupRsn_VSIM_C m2 : 32|8@1+ (1,0) [0|0] ""  ESM,ESC,SCCM,EPS,TPM,PTS,IC,CBC,RF_HUB
 SG_ Awake_Diag_Actv m15 : 33|1@1+ (1,0) [0|0] ""  ESM,ESC,SCCM,EPS,TPM,PTS,IC,CBC,RF_HUB
 SG_ WakeupCnt m2 : 40|8@1+ (1,0) [0|254] ""  ESM,ESC,SCCM,EPS,TPM,PTS,IC,CBC,RF_HUB
 SG_ Nw_Id : 56|8@1+ (1,0) [0|0] ""  ESM,ESC,SCCM,EPS,TPM,PTS,IC,CBC,RF_HUB

BO_ 1089 DG_RQ_GLOBAL_UDS: 8 Diagnost
 SG_ DG_RQ_GLOBAL_UDS : 7|64@0+ (1,0) [0|0] ""  ETM,HaLF,ORC,ADCM,ESM,TCM,ECM,DASM,ESC,SCCM,EPS,AFLS,TPM,PTS,IC,CBC,RF_HUB

BO_ 1098 VehCfg5: 8 CBC
 SG_ VC_VehCfg5_Stat : 0|2@1+ (1,0) [0|0] ""  ORC,ECM,DASM,ESC,SCCM,EPS,PTS,IC,RF_HUB
 SG_ VC_LUCI_PRSNT : 2|1@1+ (1,0) [0|0] ""  RF_HUB
 SG_ VC_RR_DuallyPrsnt : 3|1@1+ (1,0) [0|0] ""  IC,RF_HUB
 SG_ VC_NonReg_TPIS : 4|1@1+ (1,0) [0|0] ""  IC,RF_HUB
 SG_ VC_WTS_Prsnt : 5|1@1+ (1,0) [0|0] ""  RF_HUB
 SG_ VC_AmbTempLct : 6|2@1+ (1,0) [0|0] ""  RF_HUB
 SG_ VC_Strng_Rt_0 : 8|8@1+ (0.1,0) [0|25.4] ""  ESC,RF_HUB
 SG_ VC_Strng_Rt_pls1 : 16|8@1+ (0.1,0) [0|25.4] ""  ESC,RF_HUB
 SG_ VC_Strng_Rt_pls2 : 24|8@1+ (0.1,0) [0|25.4] ""  ESC,RF_HUB
 SG_ VC_Strng_Rt_pls3 : 32|8@1+ (0.1,0) [0|25.4] ""  ESC,RF_HUB
 SG_ VC_Strng_Rt_pls4 : 40|8@1+ (0.1,0) [0|25.4] ""  ESC,RF_HUB
 SG_ VC_Strng_Rt_pls5 : 48|8@1+ (0.1,0) [0|25.4] ""  ESC,RF_HUB
 SG_ VC_RearDoorLocks2DCM : 56|1@1+ (1,0) [0|0] ""  RF_HUB
 SG_ VC_SpdLmt_PRSNT : 57|1@1+ (1,0) [0|0] ""  ECM,DASM,SCCM,IC,RF_HUB
 SG_ VC_SBR_Prsnt : 58|1@1+ (1,0) [0|0] ""  ORC,RF_HUB
 SG_ VC_ChildDisp_Prsnt : 59|1@1+ (1,0) [0|0] ""  ORC,RF_HUB
 SG_ VC_OffRoadPg : 60|1@1+ (1,0) [0|0] ""  IC,RF_HUB
 SG_ VC_AmbLtgPrsnt : 61|1@1+ (1,0) [0|0] ""  IC,RF_HUB
 SG_ VC_PPPA_Prsnt : 62|1@1+ (1,0) [0|0] ""  EPS,PTS,IC,RF_HUB
 SG_ VC_ParkStopPrsnt : 63|1@1+ (1,0) [0|0] ""  ESC,PTS,RF_HUB

CM_ SG_ 1013 EC_ECUCfg6_Stat "ECU Configuration messages status 6";
CM_ SG_ 1013 EC_BrakesA "Brake system ecu configurationA";
CM_ SG_ 1013 EC_BrakesB "Brake system ecu configurationB";
CM_ SG_ 1013 EC_Steering "Steering ecu configuration";
CM_ SG_ 1013 EC_Powertrain "Powertrain ecu configuration";
CM_ SG_ 1013 EC_Safety "Safety ecu configuration";
CM_ SG_ 1014 EC_ECUCfg7_Stat "ECU Configuration messages status 7";
CM_ SG_ 1014 EC_CBC5A "CBC ecu configuration 5A";
CM_ SG_ 1014 EC_CBC5B "CBC ecu configuration 5B";
CM_ SG_ 1014 EC_CBC6 "CBC ecu configuration 6";
CM_ SG_ 1015 EC_ECUCfg8_Stat "ECU Configuration messages status 8";
CM_ SG_ 1015 EC_CBC7A "CBC ecu configuration 7A";
CM_ SG_ 1015 EC_CBC7B "CBC ecu configuration 7B";
CM_ SG_ 1015 EC_CBC8 "CBC ecu configuration 8";
CM_ SG_ 1016 EC_BU_ECUCfg1_Stat "Backup for ECU Configuration messages status 1";
CM_ SG_ 1016 EC_BU_CBC1A "Backup for CBC ecu configuration 1A";
CM_ SG_ 1016 EC_BU_CBC1B "Backup for CBC ecu configuration 1B";
CM_ SG_ 1016 EC_BU_CBC2 "Backup for CBC ecu configuration 2";
CM_ SG_ 1017 EC_BU_ECUCfg2_Stat "Backup for ECU Configuration messages status 2";
CM_ SG_ 1017 EC_BU_CBC3A "Backup for CBC ecu configuration 3A";
CM_ SG_ 1017 EC_BU_CBC3B "Backup for CBC ecu configuration 3B";
CM_ SG_ 1017 EC_BU_CBC4 "Backup for CBC ecu configuration 4";
CM_ SG_ 1018 EC_BU_ECUCfg3_Stat "Backup for ECU Configuration messages status 3";
CM_ SG_ 1018 EC_BU_AudTel1A "Backup for Audio and telematics ecu configuration 1A";
CM_ SG_ 1018 EC_BU_AudTel1B "Backup for Audio and telematics ecu configuration 1B";
CM_ SG_ 1018 EC_BU_AudTel2 "Backup for Audio and telematics ecu configuration 2";
CM_ SG_ 1019 EC_BU_ECUCfg4_Stat "Backup for ECU Configuration messages status 4";
CM_ SG_ 1019 EC_BU_Cluster1A "Backup for Instrument cluster ecu configuration 1A";
CM_ SG_ 1019 EC_BU_Cluster1B "Backup for Instrument cluster ecu configuration 1B";
CM_ SG_ 1019 EC_BU_Cluster2 "Backup for Instrument cluster ecu configuration 2";
CM_ SG_ 1020 EC_BU_ECUCfg5_Stat "Backup for ECU Configuration messages status 5";
CM_ SG_ 1020 EC_BU_WirelessA "Backup for Wireless ecu configurationA";
CM_ SG_ 1020 EC_BU_WirelessB "Backup for Wireless ecu configurationB";
CM_ SG_ 1020 EC_BU_Doors "Backup for Doors ecu configuration";
CM_ SG_ 1020 EC_BU_Memory "Backup for Memory ecu configuration";
CM_ SG_ 1021 EC_BU_ECUCfg6_Stat "Backup for ECU Configuration messages status 6";
CM_ SG_ 1021 EC_BU_BrakesA "Backup for Brake system ecu configurationA";
CM_ SG_ 1021 EC_BU_BrakesB "Backup for Brake system ecu configurationB";
CM_ SG_ 1021 EC_BU_Steering "Backup for steering ecu configuration";
CM_ SG_ 1021 EC_BU_Powertrain "Backup for Powertrain ecu configuration";
CM_ SG_ 1021 EC_BU_Safety "Backup for Safety ecu configuration";
CM_ SG_ 1022 EC_BU_ECUCfg7_Stat "Backup for ECU Configuration messages status 7";
CM_ SG_ 1022 EC_BU_CBC5A "Backup for CBC ecu configuration 5A";
CM_ SG_ 1022 EC_BU_CBC5B "Backup for CBC ecu configuration 5B";
CM_ SG_ 1022 EC_BU_CBC6 "Backup for CBC ecu configuration 6";
CM_ SG_ 1023 EC_BU_ECUCfg8_Stat "Backup for ECU Configuration messages status 8";
CM_ SG_ 1023 EC_BU_CBC7A "Backup for CBC ecu configuration 7A";
CM_ SG_ 1023 EC_BU_CBC7B "Backup for CBC ecu configuration 7B";
CM_ SG_ 1023 EC_BU_CBC8 "Backup for CBC ecu configuration 8";
CM_ SG_ 1024 NM_Mode "Network management mode";
CM_ SG_ 1024 NM_Successor "Network management logical successor";
CM_ SG_ 1024 NM_Ud_Launch "Network management userdata launch type";
CM_ SG_ 1024 NM_Sleep_Ack "Network management sleep acknowledge; True = [1]";
CM_ SG_ 1024 NM_Sleep_Ind "Network management sleep indication; True = [1]";
CM_ SG_ 1024 NM_Ud_Srv "Network management userdata service no.";
CM_ SG_ 1024 Awake_NwSt "Stay awake for network startup; True = [1]";
CM_ SG_ 1024 WakeupRsn_RF_HUB "Wakeup reason RF_HUB";
CM_ SG_ 1024 Awake_Diag_Actv "Stay awake for diagnostics active; True = [1]";
CM_ SG_ 1024 WakeupCnt "Counter for module wakeup states during network sleep";
CM_ SG_ 1024 Nw_Id "Network identification no.";
CM_ SG_ 1025 NM_Mode "Network management mode";
CM_ SG_ 1025 NM_Successor "Network management logical successor";
CM_ SG_ 1025 NM_Ud_Launch "Network management userdata launch type";
CM_ SG_ 1025 NM_Sleep_Ack "Network management sleep acknowledge; True = [1]";
CM_ SG_ 1025 NM_Sleep_Ind "Network management sleep indication; True = [1]";
CM_ SG_ 1025 NM_Ud_Srv "Network management userdata service no.";
CM_ SG_ 1025 Awake_NwSt "Stay awake for network startup; True = [1]";
CM_ SG_ 1025 WakeupRsn_CBC "Wakeup reason CBC";
CM_ SG_ 1025 Awake_Diag_Actv "Stay awake for diagnostics active; True = [1]";
CM_ SG_ 1025 WakeupCnt "Counter for module wakeup states during network sleep";
CM_ SG_ 1025 Nw_Id "Network identification no.";
CM_ SG_ 1026 NM_Mode "Network management mode";
CM_ SG_ 1026 NM_Successor "Network management logical successor";
CM_ SG_ 1026 NM_Ud_Launch "Network management userdata launch type";
CM_ SG_ 1026 NM_Sleep_Ack "Network management sleep acknowledge; True = [1]";
CM_ SG_ 1026 NM_Sleep_Ind "Network management sleep indication; True = [1]";
CM_ SG_ 1026 NM_Ud_Srv "Network management userdata service no.";
CM_ SG_ 1026 Awake_NwSt "Stay awake for network startup; True = [1]";
CM_ SG_ 1026 WakeupRsn_IC "Wakeup reason IC";
CM_ SG_ 1026 Awake_Diag_Actv "Stay awake for diagnostics active; True = [1]";
CM_ SG_ 1026 WakeupCnt "Counter for module wakeup states during network sleep";
CM_ SG_ 1026 Nw_Id "Network identification no.";
CM_ SG_ 1027 NM_Mode "Network management mode";
CM_ SG_ 1027 NM_Successor "Network management logical successor";
CM_ SG_ 1027 NM_Ud_Launch "Network management userdata launch type";
CM_ SG_ 1027 NM_Sleep_Ack "Network management sleep acknowledge; True = [1]";
CM_ SG_ 1027 NM_Sleep_Ind "Network management sleep indication; True = [1]";
CM_ SG_ 1027 NM_Ud_Srv "Network management userdata service no.";
CM_ SG_ 1027 Awake_NwSt "Stay awake for network startup; True = [1]";
CM_ SG_ 1027 WakeupRsn_TPM "Wakeup reason TPM";
CM_ SG_ 1027 Awake_Diag_Actv "Stay awake for diagnostics active; True = [1]";
CM_ SG_ 1027 WakeupCnt "Counter for module wakeup states during network sleep";
CM_ SG_ 1027 Nw_Id "Network identification no.";
CM_ SG_ 1029 NM_Mode "Network management mode";
CM_ SG_ 1029 NM_Successor "Network management logical successor";
CM_ SG_ 1029 NM_Ud_Launch "Network management userdata launch type";
CM_ SG_ 1029 NM_Sleep_Ack "Network management sleep acknowledge; True = [1]";
CM_ SG_ 1029 NM_Sleep_Ind "Network management sleep indication; True = [1]";
CM_ SG_ 1029 NM_Ud_Srv "Network management userdata service no.";
CM_ SG_ 1029 Awake_NwSt "Stay awake for network startup; True = [1]";
CM_ SG_ 1029 WakeupRsn_RBT_DR "Wakeup reason RBT_DR";
CM_ SG_ 1029 Awake_Diag_Actv "Stay awake for diagnostics active; True = [1]";
CM_ SG_ 1029 WakeupCnt "Counter for module wakeup states during network sleep";
CM_ SG_ 1029 Nw_Id "Network identification no.";
CM_ SG_ 1030 NM_Mode "Network management mode";
CM_ SG_ 1030 NM_Successor "Network management logical successor";
CM_ SG_ 1030 NM_Ud_Launch "Network management userdata launch type";
CM_ SG_ 1030 NM_Sleep_Ack "Network management sleep acknowledge; True = [1]";
CM_ SG_ 1030 NM_Sleep_Ind "Network management sleep indication; True = [1]";
CM_ SG_ 1030 NM_Ud_Srv "Network management userdata service no.";
CM_ SG_ 1030 Awake_NwSt "Stay awake for network startup; True = [1]";
CM_ SG_ 1030 WakeupRsn_RBT_PASS "Wakeup reason RBT_PASS";
CM_ SG_ 1030 Awake_Diag_Actv "Stay awake for diagnostics active; True = [1]";
CM_ SG_ 1030 WakeupCnt "Counter for module wakeup states during network sleep";
CM_ SG_ 1030 Nw_Id "Network identification no.";
CM_ SG_ 1031 NM_Mode "Network management mode";
CM_ SG_ 1031 NM_Successor "Network management logical successor";
CM_ SG_ 1031 NM_Ud_Launch "Network management userdata launch type";
CM_ SG_ 1031 NM_Sleep_Ack "Network management sleep acknowledge; True = [1]";
CM_ SG_ 1031 NM_Sleep_Ind "Network management sleep indication; True = [1]";
CM_ SG_ 1031 NM_Ud_Srv "Network management userdata service no.";
CM_ SG_ 1031 Awake_NwSt "Stay awake for network startup; True = [1]";
CM_ SG_ 1031 WakeupRsn_ESC "Wakeup reason ESC";
CM_ SG_ 1031 Awake_Diag_Actv "Stay awake for diagnostics active; True = [1]";
CM_ SG_ 1031 WakeupCnt "Counter for module wakeup states during network sleep";
CM_ SG_ 1031 Nw_Id "Network identification no.";
CM_ SG_ 1033 NM_Mode "Network management mode";
CM_ SG_ 1033 NM_Successor "Network management logical successor";
CM_ SG_ 1033 NM_Ud_Launch "Network management userdata launch type";
CM_ SG_ 1033 NM_Sleep_Ack "Network management sleep acknowledge; True = [1]";
CM_ SG_ 1033 NM_Sleep_Ind "Network management sleep indication; True = [1]";
CM_ SG_ 1033 NM_Ud_Srv "Network management userdata service no.";
CM_ SG_ 1033 Awake_NwSt "Stay awake for network startup; True = [1]";
CM_ SG_ 1033 WakeupRsn_SBWM "Wakeup reason SBWM";
CM_ SG_ 1033 Awake_Diag_Actv "Stay awake for diagnostics active; True = [1]";
CM_ SG_ 1033 Awake_Ignition_On "Stay awake for ignition on; True = [1]";
CM_ SG_ 1033 Awake_EEPROM "Stay awake for EEPROM write access; True = [1]";
CM_ SG_ 1033 Awake_URS "Stay awake for 'Unlock Run Start' hardwired input; True = [1]";
CM_ SG_ 1033 WakeupCnt "Counter for module wakeup states during network sleep";
CM_ SG_ 1033 Nw_Id "Network identification no.";
CM_ SG_ 1044 NM_Mode "Network management mode";
CM_ SG_ 1044 NM_Successor "Network management logical successor";
CM_ SG_ 1044 NM_Ud_Launch "Network management userdata launch type";
CM_ SG_ 1044 NM_Sleep_Ack "Network management sleep acknowledge; True = [1]";
CM_ SG_ 1044 NM_Sleep_Ind "Network management sleep indication; True = [1]";
CM_ SG_ 1044 NM_Ud_Srv "Network management userdata service no.";
CM_ SG_ 1044 Awake_NwSt "Stay awake for network startup; True = [1]";
CM_ SG_ 1044 WakeupRsn_ITBM "Wakeup reason IC";
CM_ SG_ 1044 Awake_Diag_Actv "Stay awake for diagnostics active; True = [1]";
CM_ SG_ 1044 WakeupCnt "Counter for module wakeup states during network sleep";
CM_ SG_ 1044 Nw_Id "Network identification no.";
CM_ SG_ 1049 NM_Mode "Network management mode";
CM_ SG_ 1049 NM_Successor "Network management logical successor";
CM_ SG_ 1049 NM_Ud_Launch "Network management userdata launch type";
CM_ SG_ 1049 NM_Sleep_Ack "Network management sleep acknowledge; True = [1]";
CM_ SG_ 1049 NM_Sleep_Ind "Network management sleep indication; True = [1]";
CM_ SG_ 1049 NM_Ud_Srv "Network management userdata service no.";
CM_ SG_ 1049 Awake_NwSt "Stay awake for network startup; True = [1]";
CM_ SG_ 1049 WakeupRsn_EPB "Wakeup reason EPS";
CM_ SG_ 1049 Awake_Diag_Actv "Stay awake for diagnostics active; True = [1]";
CM_ SG_ 1049 WakeupCnt "Counter for module wakeup states during network sleep";
CM_ SG_ 1049 Nw_Id "Network identification no.";
CM_ SG_ 1050 NM_Mode "Network management mode";
CM_ SG_ 1050 NM_Successor "Network management logical successor";
CM_ SG_ 1050 NM_Ud_Launch "Network management userdata launch type";
CM_ SG_ 1050 NM_Sleep_Ack "Network management sleep acknowledge; True = [1]";
CM_ SG_ 1050 NM_Sleep_Ind "Network management sleep indication; True = [1]";
CM_ SG_ 1050 NM_Ud_Srv "Network management userdata service no.";
CM_ SG_ 1050 Awake_NwSt "Stay awake for network startup; True = [1]";
CM_ SG_ 1050 WakeupRsn_EPS "Wakeup reason EPS";
CM_ SG_ 1050 Awake_Diag_Actv "Stay awake for diagnostics active; True = [1]";
CM_ SG_ 1050 Awake_Rampout "Stay awake - ramping assist off; True = 1";
CM_ SG_ 1050 Awake_VSS_high "Stay awake - assist active due to vehicle speed high; True = 1";
CM_ SG_ 1050 Awake_EngRPM_high "Stay awake - assist active due to engine RPM high; True = 1";
CM_ SG_ 1050 Awake_IgnHigh "Stay awake - ignition high; True = 1";
CM_ SG_ 1050 WakeupCnt "Counter for module wakeup states during network sleep";
CM_ SG_ 1050 Nw_Id "Network identification no.";
CM_ SG_ 1058 NM_Mode "Network management mode";
CM_ SG_ 1058 NM_Successor "Network management logical successor";
CM_ SG_ 1058 NM_Ud_Launch "Network management userdata launch type";
CM_ SG_ 1058 NM_Sleep_Ack "Network management sleep acknowledge; True = [1]";
CM_ SG_ 1058 NM_Sleep_Ind "Network management sleep indication; True = [1]";
CM_ SG_ 1058 NM_Ud_Srv "Network management userdata service no.";
CM_ SG_ 1058 Awake_NwSt "Stay awake for network startup; True = [1]";
CM_ SG_ 1058 WakeupRsn_PTS "Wakeup reason PTS";
CM_ SG_ 1058 Awake_Diag_Actv "Stay awake for diagnostics active; True = [1]";
CM_ SG_ 1058 WakeupCnt "Counter for module wakeup states during network sleep";
CM_ SG_ 1058 Nw_Id "Network identification no.";
CM_ SG_ 1059 NM_Mode "Network management mode";
CM_ SG_ 1059 NM_Successor "Network management logical successor";
CM_ SG_ 1059 NM_Ud_Launch "Network management userdata launch type";
CM_ SG_ 1059 NM_Sleep_Ack "Network management sleep acknowledge; True = [1]";
CM_ SG_ 1059 NM_Sleep_Ind "Network management sleep indication; True = [1]";
CM_ SG_ 1059 NM_Ud_Srv "Network management userdata service no.";
CM_ SG_ 1059 Awake_NwSt "Stay awake for network startup; True = [1]";
CM_ SG_ 1059 WakeupRsn_SCCM "Wakeup reason SCCM";
CM_ SG_ 1059 Awake_Diag_Actv "Stay awake for diagnostics active; True = [1]";
CM_ SG_ 1059 Awake_StwSw_Actv "Stay awake for steering wheel switches active; True = [1]";
CM_ SG_ 1059 Awake_Ignition_On "Stay awake for ignition on; True = [1]";
CM_ SG_ 1059 Awake_EEPROM "Stay awake for EEPROM write access; True = [1]";
CM_ SG_ 1059 Awake_tilt_tel_Psd "Stay awake for tilt/telescope switch actuated; True = [1]";
CM_ SG_ 1059 Awake_FTP_Psd "Stay awake for flash to pass lever actuated; True = [1]";
CM_ SG_ 1059 Awake_HrnSwt_Actv "Stay awake for  horn switch active; True = [1]";
CM_ SG_ 1059 WakeupCnt "Counter for module wakeup states during network sleep";
CM_ SG_ 1059 Nw_Id "Network identification no.";
CM_ SG_ 1061 NM_Mode "Network management mode";
CM_ SG_ 1061 NM_Successor "Network management logical successor";
CM_ SG_ 1061 NM_Ud_Launch "Network management userdata launch type";
CM_ SG_ 1061 NM_Sleep_Ack "Network management sleep acknowledge; True = [1]";
CM_ SG_ 1061 NM_Sleep_Ind "Network management sleep indication; True = [1]";
CM_ SG_ 1061 NM_Ud_Srv "Network management userdata service no.";
CM_ SG_ 1061 Awake_NwSt "Stay awake for network startup; True = [1]";
CM_ SG_ 1061 WakeupRsn_ANC "Wakeup reason ASCM";
CM_ SG_ 1061 Awake_Diag_Actv "Stay awake for diagnostics active; True = [1]";
CM_ SG_ 1061 WakeupCnt "Counter for module wakeup states during network sleep";
CM_ SG_ 1061 Nw_Id "Network identification no.";
CM_ SG_ 1062 NM_Mode "Network management mode";
CM_ SG_ 1062 NM_Successor "Network management logical successor";
CM_ SG_ 1062 NM_Ud_Launch "Network management userdata launch type";
CM_ SG_ 1062 NM_Sleep_Ack "Network management sleep acknowledge; True = [1]";
CM_ SG_ 1062 NM_Sleep_Ind "Network management sleep indication; True = [1]";
CM_ SG_ 1062 NM_Ud_Srv "Network management userdata service no.";
CM_ SG_ 1062 Awake_NwSt "Stay awake for network startup; True = [1]";
CM_ SG_ 1062 WakeupRsn_ASCM "Wakeup reason ASCM";
CM_ SG_ 1062 Awake_Diag_Actv "Stay awake for diagnostics active; True = [1]";
CM_ SG_ 1062 WakeupCnt "Counter for module wakeup states during network sleep";
CM_ SG_ 1062 Nw_Id "Network identification no.";
CM_ SG_ 1073 NM_Mode "Network management mode";
CM_ SG_ 1073 NM_Successor "Network management logical successor";
CM_ SG_ 1073 NM_Ud_Launch "Network management userdata launch type";
CM_ SG_ 1073 NM_Sleep_Ack "Network management sleep acknowledge; True = [1]";
CM_ SG_ 1073 NM_Sleep_Ind "Network management sleep indication; True = [1]";
CM_ SG_ 1073 NM_Ud_Srv "Network management userdata service no.";
CM_ SG_ 1073 Awake_NwSt "Stay awake for network startup; True = [1]";
CM_ SG_ 1073 WakeupRsn_VSIM_C "Wakeup reason VSIM_C";
CM_ SG_ 1073 Awake_Diag_Actv "Stay awake for diagnostics active; True = [1]";
CM_ SG_ 1073 WakeupCnt "Counter for module wakeup states during network sleep";
CM_ SG_ 1073 Nw_Id "Network identification no.";
CM_ SG_ 1089 DG_RQ_GLOBAL_UDS "Diagnostic-Request";
CM_ SG_ 1098 VC_VehCfg5_Stat "Configuration messages status 5";
CM_ SG_ 1098 VC_LUCI_PRSNT "Luci feature present; present = [1]";
CM_ SG_ 1098 VC_RR_DuallyPrsnt "Vehicle is equipped with rear duals; present = [1]";
CM_ SG_ 1098 VC_NonReg_TPIS "Non-regulated tire pressure indicator system; True = 1";
CM_ SG_ 1098 VC_WTS_Prsnt "Wait to start feature is present; present = [1]";
CM_ SG_ 1098 VC_AmbTempLct "Ambient temperature sensor location";
CM_ SG_ 1098 VC_Strng_Rt_0 "Steering Ratio at zero";
CM_ SG_ 1098 VC_Strng_Rt_pls1 "Steering Ratio at positve angle 1";
CM_ SG_ 1098 VC_Strng_Rt_pls2 "Steering Ratio at positve angle 2";
CM_ SG_ 1098 VC_Strng_Rt_pls3 "Steering Ratio at positve angle 3";
CM_ SG_ 1098 VC_Strng_Rt_pls4 "Steering Ratio at positve angle 4";
CM_ SG_ 1098 VC_Strng_Rt_pls5 "Steering Ratio at positve angle 5";
CM_ SG_ 1098 VC_RearDoorLocks2DCM "Rear door lock switch present; present = [1]";
CM_ SG_ 1098 VC_SpdLmt_PRSNT "Speed limiter is present; present = [1]";
CM_ SG_ 1098 VC_SBR_Prsnt "Seat belt reminder module is present; True = 1";
CM_ SG_ 1098 VC_ChildDisp_Prsnt "Child display feature is present; True = 1";
CM_ SG_ 1098 VC_OffRoadPg "Off road pages present; True = [1]";
CM_ SG_ 1098 VC_AmbLtgPrsnt "Ambient lighting feature is present; True = [1]";
CM_ SG_ 1098 VC_PPPA_Prsnt "Semi automatic parking system present; present = [1]";
CM_ SG_ 1098 VC_ParkStopPrsnt "Park with stop is present; True = 1";
BA_DEF_ SG_  "GenSigTimeout_ADCM" INT 0 65535;
BA_DEF_ SG_  "GenSigTimeout_AFLS" INT 0 65535;
BA_DEF_ SG_  "GenSigTimeout_CBC" INT 0 65535;
BA_DEF_ SG_  "GenSigTimeout_DTCM" INT 0 65535;
BA_DEF_ SG_  "GenSigTimeout_ECM" INT 0 65535;
BA_DEF_ SG_  "GenSigTimeout_EPS" INT 0 65535;
BA_DEF_ SG_  "GenSigTimeout_ESC" INT 0 65535;
BA_DEF_ SG_  "GenSigTimeout_ESM" INT 0 65535;
BA_DEF_ SG_  "GenSigTimeout_ETM" INT 0 65535;
BA_DEF_ SG_  "GenSigTimeout_HaLF" INT 0 65535;
BA_DEF_ SG_  "GenSigTimeout_IC" INT 0 65535;
BA_DEF_ SG_  "GenSigTimeout_ORC" INT 0 65535;
BA_DEF_ SG_  "GenSigTimeout_PTS" INT 0 65535;
BA_DEF_ SG_  "GenSigTimeout_RF_HUB" INT 0 65535;
BA_DEF_ SG_  "GenSigTimeout_SCCM" INT 0 65535;
BA_DEF_ SG_  "GenSigTimeout_TPM" INT 0 65535;
BA_DEF_ BO_  "GenMsgStartValue" STRING ;
BA_DEF_ SG_  "GenSigSNA" STRING ;
BA_DEF_ SG_  "FlexKomIsMotorola" ENUM  "nein","ja";
BA_DEF_ SG_  "FlexKomSigLaenge" INT 0 64;
BA_DEF_ SG_  "FlexKomSigStartPos" INT 0 63;
BA_DEF_ SG_  "FlexKomComment" STRING ;
BA_DEF_ SG_  "FlexKomSigName" STRING ;
BA_DEF_ SG_  "FlexKomSID" INT 0 2147483647;
BA_DEF_ SG_  "GenSigStartValue" HEX 0 4294967295;
BA_DEF_ SG_  "FlexKomSigStartValue" STRING ;
BA_DEF_ SG_  "GenSigCycleTimeActive" INT 0 65535;
BA_DEF_ SG_  "GenSigCycleTime" INT 0 65535;
BA_DEF_ SG_  "GenSigSendType" ENUM  "cyclicX","spontanX","cyclicIfActiveX","spontanWithDelay","cyclicAndSpontanX","cyclicAndSpontanWithDelay","spontanWithRepitition","cyclicIfActiveAndSpontanWD","cyclicIfActiveFast","cyclicWithRepeatOnDemand","none";
BA_DEF_ BO_  "GenMsgNrOfRepetitions" INT 0 65535;
BA_DEF_ BO_  "GenMsgDelayTime" INT 0 65535;
BA_DEF_ BO_  "GenMsgStartDelayTime" INT 0 65535;
BA_DEF_ BO_  "GenMsgCycleTimeActive" INT 0 65535;
BA_DEF_ BO_  "GenMsgCycleTime" INT 0 65535;
BA_DEF_ BO_  "GenMsgSendType" ENUM  "cyclicX","spontanX","cyclicIfActiveX","spontanWithDelay","cyclicAndSpontanX","cyclicAndSpontanWithDelay","spontanWithRepitition","cyclicIfActiveAndSpontanWD","cyclicIfActiveFast","cyclicWithRepeatOnDemand","none";
BA_DEF_ BO_  "DiagResponse" ENUM  "nein","ja";
BA_DEF_ BO_  "DiagRequest" ENUM  "nein","ja";
BA_DEF_ BO_  "DiagState" ENUM  "nein","ja";
BA_DEF_ BO_  "App-Botschaft" ENUM  "nein","ja";
BA_DEF_ BO_  "NWM-Botschaft" ENUM  "nein","ja";
BA_DEF_DEF_  "GenSigTimeout_ADCM" 0;
BA_DEF_DEF_  "GenSigTimeout_AFLS" 0;
BA_DEF_DEF_  "GenSigTimeout_CBC" 0;
BA_DEF_DEF_  "GenSigTimeout_DTCM" 0;
BA_DEF_DEF_  "GenSigTimeout_ECM" 0;
BA_DEF_DEF_  "GenSigTimeout_EPS" 0;
BA_DEF_DEF_  "GenSigTimeout_ESC" 0;
BA_DEF_DEF_  "GenSigTimeout_ESM" 0;
BA_DEF_DEF_  "GenSigTimeout_ETM" 0;
BA_DEF_DEF_  "GenSigTimeout_HaLF" 0;
BA_DEF_DEF_  "GenSigTimeout_IC" 0;
BA_DEF_DEF_  "GenSigTimeout_ORC" 0;
BA_DEF_DEF_  "GenSigTimeout_PTS" 0;
BA_DEF_DEF_  "GenSigTimeout_RF_HUB" 0;
BA_DEF_DEF_  "GenSigTimeout_SCCM" 0;
BA_DEF_DEF_  "GenSigTimeout_TPM" 0;
BA_DEF_DEF_  "GenMsgStartValue" "";
BA_DEF_DEF_  "GenSigSNA" "";
BA_DEF_DEF_  "FlexKomIsMotorola" "nein";
BA_DEF_DEF_  "FlexKomSigLaenge" 0;
BA_DEF_DEF_  "FlexKomSigStartPos" 0;
BA_DEF_DEF_  "FlexKomComment" "";
BA_DEF_DEF_  "FlexKomSigName" "";
BA_DEF_DEF_  "FlexKomSID" 0;
BA_DEF_DEF_  "GenSigStartValue" 0;
BA_DEF_DEF_  "FlexKomSigStartValue" "";
BA_DEF_DEF_  "GenSigCycleTimeActive" 0;
BA_DEF_DEF_  "GenSigCycleTime" 0;
BA_DEF_DEF_  "GenSigSendType" "cyclicX";
BA_DEF_DEF_  "GenMsgNrOfRepetitions" 0;
BA_DEF_DEF_  "GenMsgDelayTime" 0;
BA_DEF_DEF_  "GenMsgStartDelayTime" 0;
BA_DEF_DEF_  "GenMsgCycleTimeActive" 0;
BA_DEF_DEF_  "GenMsgCycleTime" 0;
BA_DEF_DEF_  "GenMsgSendType" "cyclicX";
BA_DEF_DEF_  "DiagResponse" "nein";
BA_DEF_DEF_  "DiagRequest" "nein";
BA_DEF_DEF_  "DiagState" "nein";
BA_DEF_DEF_  "App-Botschaft" "nein";
BA_DEF_DEF_  "NWM-Botschaft" "nein";
BA_ "GenMsgSendType" BO_ 1013 5;
BA_ "GenMsgCycleTime" BO_ 1013 2000;
BA_ "GenMsgDelayTime" BO_ 1013 20;
BA_ "GenMsgNrOfRepetitions" BO_ 1013 2;
BA_ "GenMsgStartValue" BO_ 1013 "0300000000000000h";
BA_ "GenMsgStartDelayTime" BO_ 1013 60;
BA_ "GenMsgCycleTime" BO_ 1014 2000;
BA_ "GenMsgDelayTime" BO_ 1014 20;
BA_ "GenMsgNrOfRepetitions" BO_ 1014 2;
BA_ "GenMsgStartValue" BO_ 1014 "0300000000000000h";
BA_ "GenMsgStartDelayTime" BO_ 1014 150;
BA_ "GenMsgCycleTime" BO_ 1015 2000;
BA_ "GenMsgDelayTime" BO_ 1015 20;
BA_ "GenMsgNrOfRepetitions" BO_ 1015 2;
BA_ "GenMsgStartValue" BO_ 1015 "0300000000000000h";
BA_ "GenMsgStartDelayTime" BO_ 1015 80;
BA_ "GenMsgSendType" BO_ 1016 1;
BA_ "GenMsgDelayTime" BO_ 1016 20;
BA_ "GenMsgNrOfRepetitions" BO_ 1016 2;
BA_ "GenMsgStartValue" BO_ 1016 "0300000000000000h";
BA_ "GenMsgSendType" BO_ 1017 1;
BA_ "GenMsgDelayTime" BO_ 1017 20;
BA_ "GenMsgNrOfRepetitions" BO_ 1017 2;
BA_ "GenMsgStartValue" BO_ 1017 "0300000000000000h";
BA_ "GenMsgSendType" BO_ 1018 1;
BA_ "GenMsgDelayTime" BO_ 1018 20;
BA_ "GenMsgNrOfRepetitions" BO_ 1018 2;
BA_ "GenMsgStartValue" BO_ 1018 "0300000000000000h";
BA_ "GenMsgSendType" BO_ 1019 1;
BA_ "GenMsgDelayTime" BO_ 1019 20;
BA_ "GenMsgNrOfRepetitions" BO_ 1019 2;
BA_ "GenMsgStartValue" BO_ 1019 "0300000000000000h";
BA_ "GenMsgSendType" BO_ 1020 1;
BA_ "GenMsgDelayTime" BO_ 1020 20;
BA_ "GenMsgNrOfRepetitions" BO_ 1020 2;
BA_ "GenMsgStartValue" BO_ 1020 "0300000000000000h";
BA_ "GenMsgSendType" BO_ 1021 1;
BA_ "GenMsgDelayTime" BO_ 1021 20;
BA_ "GenMsgNrOfRepetitions" BO_ 1021 2;
BA_ "GenMsgStartValue" BO_ 1021 "0300000000000000h";
BA_ "GenMsgSendType" BO_ 1022 1;
BA_ "GenMsgDelayTime" BO_ 1022 20;
BA_ "GenMsgNrOfRepetitions" BO_ 1022 2;
BA_ "GenMsgStartValue" BO_ 1022 "0300000000000000h";
BA_ "GenMsgSendType" BO_ 1023 1;
BA_ "GenMsgDelayTime" BO_ 1023 20;
BA_ "GenMsgNrOfRepetitions" BO_ 1023 2;
BA_ "GenMsgStartValue" BO_ 1023 "0300000000000000h";
BA_ "NWM-Botschaft" BO_ 1024 1;
BA_ "GenMsgDelayTime" BO_ 1024 20;
BA_ "GenMsgNrOfRepetitions" BO_ 1024 2;
BA_ "GenMsgStartValue" BO_ 1024 "FFFFFFFF000000FFh";
BA_ "NWM-Botschaft" BO_ 1025 1;
BA_ "GenMsgDelayTime" BO_ 1025 20;
BA_ "GenMsgNrOfRepetitions" BO_ 1025 2;
BA_ "GenMsgStartValue" BO_ 1025 "FFFFFFFF000000FFh";
BA_ "NWM-Botschaft" BO_ 1026 1;
BA_ "GenMsgDelayTime" BO_ 1026 20;
BA_ "GenMsgNrOfRepetitions" BO_ 1026 2;
BA_ "GenMsgStartValue" BO_ 1026 "FFFFFFFF000000FFh";
BA_ "NWM-Botschaft" BO_ 1027 1;
BA_ "GenMsgDelayTime" BO_ 1027 20;
BA_ "GenMsgNrOfRepetitions" BO_ 1027 2;
BA_ "GenMsgStartValue" BO_ 1027 "FFFFFFFF000000FFh";
BA_ "NWM-Botschaft" BO_ 1029 1;
BA_ "GenMsgDelayTime" BO_ 1029 20;
BA_ "GenMsgNrOfRepetitions" BO_ 1029 2;
BA_ "GenMsgStartValue" BO_ 1029 "FFFFFFFF000000FFh";
BA_ "NWM-Botschaft" BO_ 1030 1;
BA_ "GenMsgDelayTime" BO_ 1030 20;
BA_ "GenMsgNrOfRepetitions" BO_ 1030 2;
BA_ "GenMsgStartValue" BO_ 1030 "FFFFFFFF000000FFh";
BA_ "NWM-Botschaft" BO_ 1031 1;
BA_ "GenMsgDelayTime" BO_ 1031 20;
BA_ "GenMsgNrOfRepetitions" BO_ 1031 2;
BA_ "GenMsgStartValue" BO_ 1031 "FFFFFFFF000000FFh";
BA_ "NWM-Botschaft" BO_ 1033 1;
BA_ "GenMsgDelayTime" BO_ 1033 20;
BA_ "GenMsgNrOfRepetitions" BO_ 1033 2;
BA_ "GenMsgStartValue" BO_ 1033 "FFFFFFFF000000FFh";
BA_ "NWM-Botschaft" BO_ 1044 1;
BA_ "GenMsgDelayTime" BO_ 1044 20;
BA_ "GenMsgNrOfRepetitions" BO_ 1044 2;
BA_ "GenMsgStartValue" BO_ 1044 "FFFFFFFF000000FFh";
BA_ "NWM-Botschaft" BO_ 1049 1;
BA_ "GenMsgDelayTime" BO_ 1049 20;
BA_ "GenMsgNrOfRepetitions" BO_ 1049 2;
BA_ "GenMsgStartValue" BO_ 1049 "FFFFFFFF000000FFh";
BA_ "NWM-Botschaft" BO_ 1050 1;
BA_ "GenMsgDelayTime" BO_ 1050 20;
BA_ "GenMsgNrOfRepetitions" BO_ 1050 2;
BA_ "GenMsgStartValue" BO_ 1050 "FFFFFFFF000000FFh";
BA_ "NWM-Botschaft" BO_ 1058 1;
BA_ "GenMsgDelayTime" BO_ 1058 20;
BA_ "GenMsgNrOfRepetitions" BO_ 1058 2;
BA_ "GenMsgStartValue" BO_ 1058 "FFFFFFFF000000FFh";
BA_ "NWM-Botschaft" BO_ 1059 1;
BA_ "GenMsgDelayTime" BO_ 1059 20;
BA_ "GenMsgNrOfRepetitions" BO_ 1059 2;
BA_ "GenMsgStartValue" BO_ 1059 "FFFFFFFF000000FFh";
BA_ "NWM-Botschaft" BO_ 1061 1;
BA_ "GenMsgDelayTime" BO_ 1061 20;
BA_ "GenMsgNrOfRepetitions" BO_ 1061 2;
BA_ "GenMsgStartValue" BO_ 1061 "FFFFFFFF000000FFh";
BA_ "NWM-Botschaft" BO_ 1062 1;
BA_ "GenMsgDelayTime" BO_ 1062 20;
BA_ "GenMsgNrOfRepetitions" BO_ 1062 2;
BA_ "GenMsgStartValue" BO_ 1062 "FFFFFFFF000000FFh";
BA_ "NWM-Botschaft" BO_ 1073 1;
BA_ "GenMsgDelayTime" BO_ 1073 20;
BA_ "GenMsgNrOfRepetitions" BO_ 1073 2;
BA_ "GenMsgStartValue" BO_ 1073 "FFFFFFFF000000FFh";
BA_ "DiagState" BO_ 1089 1;
BA_ "GenMsgDelayTime" BO_ 1089 20;
BA_ "GenMsgNrOfRepetitions" BO_ 1089 2;
BA_ "GenMsgStartValue" BO_ 1089 "0000000000000000h";
BA_ "GenMsgSendType" BO_ 1098 5;
BA_ "GenMsgCycleTime" BO_ 1098 2000;
BA_ "GenMsgDelayTime" BO_ 1098 20;
BA_ "GenMsgNrOfRepetitions" BO_ 1098 2;
BA_ "GenMsgStartValue" BO_ 1098 "C3FFFFFFFFFFFF00h";
BA_ "GenMsgStartDelayTime" BO_ 1098 60;
BA_ "GenSigSendType" SG_ 1013 EC_ECUCfg6_Stat 5;
BA_ "GenSigCycleTime" SG_ 1013 EC_ECUCfg6_Stat 2000;
BA_ "FlexKomSigStartValue" SG_ 1013 EC_ECUCfg6_Stat "03h";
BA_ "GenSigStartValue" SG_ 1013 EC_ECUCfg6_Stat 3;
BA_ "GenSigTimeout_EPS" SG_ 1013 EC_ECUCfg6_Stat 21000;
BA_ "GenSigTimeout_ORC" SG_ 1013 EC_ECUCfg6_Stat 7000;
BA_ "FlexKomSID" SG_ 1013 EC_ECUCfg6_Stat 1063;
BA_ "FlexKomSigStartPos" SG_ 1013 EC_ECUCfg6_Stat 1;
BA_ "FlexKomSigLaenge" SG_ 1013 EC_ECUCfg6_Stat 2;
BA_ "FlexKomSigName" SG_ 1013 EC_ECUCfg6_Stat "EC_ECUCfg6_Stat";
BA_ "FlexKomComment" SG_ 1013 EC_ECUCfg6_Stat "ECU Configuration messages status 6";
BA_ "FlexKomIsMotorola" SG_ 1013 EC_ECUCfg6_Stat 1;
BA_ "GenSigSNA" SG_ 1013 EC_ECUCfg6_Stat "3h";
BA_ "GenSigSendType" SG_ 1013 EC_BrakesA 5;
BA_ "GenSigCycleTime" SG_ 1013 EC_BrakesA 2000;
BA_ "FlexKomSigStartValue" SG_ 1013 EC_BrakesA "0000h";
BA_ "FlexKomSID" SG_ 1013 EC_BrakesA 889;
BA_ "FlexKomSigStartPos" SG_ 1013 EC_BrakesA 7;
BA_ "FlexKomSigLaenge" SG_ 1013 EC_BrakesA 16;
BA_ "FlexKomSigName" SG_ 1013 EC_BrakesA "EC_Brakes";
BA_ "FlexKomComment" SG_ 1013 EC_BrakesA "Brake system ecu configuration";
BA_ "FlexKomIsMotorola" SG_ 1013 EC_BrakesA 1;
BA_ "GenSigSNA" SG_ 1013 EC_BrakesA "0h";
BA_ "GenSigSendType" SG_ 1013 EC_BrakesB 5;
BA_ "GenSigCycleTime" SG_ 1013 EC_BrakesB 2000;
BA_ "FlexKomSigStartValue" SG_ 1013 EC_BrakesB "0000h";
BA_ "FlexKomSID" SG_ 1013 EC_BrakesB 889;
BA_ "FlexKomSigStartPos" SG_ 1013 EC_BrakesB 7;
BA_ "FlexKomSigLaenge" SG_ 1013 EC_BrakesB 16;
BA_ "FlexKomSigName" SG_ 1013 EC_BrakesB "EC_Brakes";
BA_ "FlexKomComment" SG_ 1013 EC_BrakesB "Brake system ecu configuration";
BA_ "FlexKomIsMotorola" SG_ 1013 EC_BrakesB 1;
BA_ "GenSigSNA" SG_ 1013 EC_BrakesB "0h";
BA_ "GenSigSendType" SG_ 1013 EC_Steering 5;
BA_ "GenSigCycleTime" SG_ 1013 EC_Steering 2000;
BA_ "FlexKomSigStartValue" SG_ 1013 EC_Steering "0000h";
BA_ "GenSigTimeout_EPS" SG_ 1013 EC_Steering 21000;
BA_ "FlexKomSID" SG_ 1013 EC_Steering 1982;
BA_ "FlexKomSigStartPos" SG_ 1013 EC_Steering 23;
BA_ "FlexKomSigLaenge" SG_ 1013 EC_Steering 16;
BA_ "FlexKomSigName" SG_ 1013 EC_Steering "EC_Steering";
BA_ "FlexKomComment" SG_ 1013 EC_Steering "Steering ecu configuration";
BA_ "FlexKomIsMotorola" SG_ 1013 EC_Steering 1;
BA_ "GenSigSNA" SG_ 1013 EC_Steering "0h";
BA_ "GenSigSendType" SG_ 1013 EC_Powertrain 5;
BA_ "GenSigCycleTime" SG_ 1013 EC_Powertrain 2000;
BA_ "FlexKomSigStartValue" SG_ 1013 EC_Powertrain "0000h";
BA_ "FlexKomSID" SG_ 1013 EC_Powertrain 890;
BA_ "FlexKomSigStartPos" SG_ 1013 EC_Powertrain 39;
BA_ "FlexKomSigLaenge" SG_ 1013 EC_Powertrain 16;
BA_ "FlexKomSigName" SG_ 1013 EC_Powertrain "EC_Powertrain";
BA_ "FlexKomComment" SG_ 1013 EC_Powertrain "Powertrain ecu configuration";
BA_ "FlexKomIsMotorola" SG_ 1013 EC_Powertrain 1;
BA_ "GenSigSNA" SG_ 1013 EC_Powertrain "0h";
BA_ "GenSigSendType" SG_ 1013 EC_Safety 5;
BA_ "GenSigCycleTime" SG_ 1013 EC_Safety 2000;
BA_ "FlexKomSigStartValue" SG_ 1013 EC_Safety "0000h";
BA_ "GenSigTimeout_ORC" SG_ 1013 EC_Safety 7000;
BA_ "FlexKomSID" SG_ 1013 EC_Safety 892;
BA_ "FlexKomSigStartPos" SG_ 1013 EC_Safety 55;
BA_ "FlexKomSigLaenge" SG_ 1013 EC_Safety 16;
BA_ "FlexKomSigName" SG_ 1013 EC_Safety "EC_Safety";
BA_ "FlexKomComment" SG_ 1013 EC_Safety "Safety ecu configuration";
BA_ "FlexKomIsMotorola" SG_ 1013 EC_Safety 1;
BA_ "GenSigSNA" SG_ 1013 EC_Safety "0h";
BA_ "GenSigCycleTime" SG_ 1014 EC_ECUCfg7_Stat 2000;
BA_ "FlexKomSigStartValue" SG_ 1014 EC_ECUCfg7_Stat "03h";
BA_ "GenSigStartValue" SG_ 1014 EC_ECUCfg7_Stat 3;
BA_ "FlexKomSID" SG_ 1014 EC_ECUCfg7_Stat 1102;
BA_ "FlexKomSigStartPos" SG_ 1014 EC_ECUCfg7_Stat 1;
BA_ "FlexKomSigLaenge" SG_ 1014 EC_ECUCfg7_Stat 2;
BA_ "FlexKomSigName" SG_ 1014 EC_ECUCfg7_Stat "EC_ECUCfg7_Stat";
BA_ "FlexKomComment" SG_ 1014 EC_ECUCfg7_Stat "ECU Configuration messages status 7";
BA_ "FlexKomIsMotorola" SG_ 1014 EC_ECUCfg7_Stat 1;
BA_ "GenSigSNA" SG_ 1014 EC_ECUCfg7_Stat "3h";
BA_ "GenSigCycleTime" SG_ 1014 EC_CBC5A 2000;
BA_ "FlexKomSigStartValue" SG_ 1014 EC_CBC5A "00000000h";
BA_ "FlexKomSID" SG_ 1014 EC_CBC5A 1105;
BA_ "FlexKomSigStartPos" SG_ 1014 EC_CBC5A 7;
BA_ "FlexKomSigLaenge" SG_ 1014 EC_CBC5A 32;
BA_ "FlexKomSigName" SG_ 1014 EC_CBC5A "EC_CBC5";
BA_ "FlexKomComment" SG_ 1014 EC_CBC5A "CBC ecu configuration 5";
BA_ "FlexKomIsMotorola" SG_ 1014 EC_CBC5A 1;
BA_ "GenSigSNA" SG_ 1014 EC_CBC5A "0h";
BA_ "GenSigCycleTime" SG_ 1014 EC_CBC5B 2000;
BA_ "FlexKomSigStartValue" SG_ 1014 EC_CBC5B "00000000h";
BA_ "FlexKomSID" SG_ 1014 EC_CBC5B 1105;
BA_ "FlexKomSigStartPos" SG_ 1014 EC_CBC5B 7;
BA_ "FlexKomSigLaenge" SG_ 1014 EC_CBC5B 32;
BA_ "FlexKomSigName" SG_ 1014 EC_CBC5B "EC_CBC5";
BA_ "FlexKomComment" SG_ 1014 EC_CBC5B "CBC ecu configuration 5";
BA_ "FlexKomIsMotorola" SG_ 1014 EC_CBC5B 1;
BA_ "GenSigSNA" SG_ 1014 EC_CBC5B "0h";
BA_ "GenSigCycleTime" SG_ 1014 EC_CBC6 2000;
BA_ "FlexKomSigStartValue" SG_ 1014 EC_CBC6 "00000000h";
BA_ "FlexKomSID" SG_ 1014 EC_CBC6 1103;
BA_ "FlexKomSigStartPos" SG_ 1014 EC_CBC6 39;
BA_ "FlexKomSigLaenge" SG_ 1014 EC_CBC6 32;
BA_ "FlexKomSigName" SG_ 1014 EC_CBC6 "EC_CBC6";
BA_ "FlexKomComment" SG_ 1014 EC_CBC6 "CBC ecu configuration 6";
BA_ "FlexKomIsMotorola" SG_ 1014 EC_CBC6 1;
BA_ "GenSigSNA" SG_ 1014 EC_CBC6 "0h";
BA_ "GenSigCycleTime" SG_ 1015 EC_ECUCfg8_Stat 2000;
BA_ "FlexKomSigStartValue" SG_ 1015 EC_ECUCfg8_Stat "03h";
BA_ "GenSigStartValue" SG_ 1015 EC_ECUCfg8_Stat 3;
BA_ "FlexKomSID" SG_ 1015 EC_ECUCfg8_Stat 1101;
BA_ "FlexKomSigStartPos" SG_ 1015 EC_ECUCfg8_Stat 1;
BA_ "FlexKomSigLaenge" SG_ 1015 EC_ECUCfg8_Stat 2;
BA_ "FlexKomSigName" SG_ 1015 EC_ECUCfg8_Stat "EC_ECUCfg8_Stat";
BA_ "FlexKomComment" SG_ 1015 EC_ECUCfg8_Stat "ECU Configuration messages status 8";
BA_ "FlexKomIsMotorola" SG_ 1015 EC_ECUCfg8_Stat 1;
BA_ "GenSigSNA" SG_ 1015 EC_ECUCfg8_Stat "3h";
BA_ "GenSigCycleTime" SG_ 1015 EC_CBC7A 2000;
BA_ "FlexKomSigStartValue" SG_ 1015 EC_CBC7A "00000000h";
BA_ "FlexKomSID" SG_ 1015 EC_CBC7A 1106;
BA_ "FlexKomSigStartPos" SG_ 1015 EC_CBC7A 7;
BA_ "FlexKomSigLaenge" SG_ 1015 EC_CBC7A 32;
BA_ "FlexKomSigName" SG_ 1015 EC_CBC7A "EC_CBC7";
BA_ "FlexKomComment" SG_ 1015 EC_CBC7A "CBC ecu configuration 7";
BA_ "FlexKomIsMotorola" SG_ 1015 EC_CBC7A 1;
BA_ "GenSigSNA" SG_ 1015 EC_CBC7A "0h";
BA_ "GenSigCycleTime" SG_ 1015 EC_CBC7B 2000;
BA_ "FlexKomSigStartValue" SG_ 1015 EC_CBC7B "00000000h";
BA_ "FlexKomSID" SG_ 1015 EC_CBC7B 1106;
BA_ "FlexKomSigStartPos" SG_ 1015 EC_CBC7B 7;
BA_ "FlexKomSigLaenge" SG_ 1015 EC_CBC7B 32;
BA_ "FlexKomSigName" SG_ 1015 EC_CBC7B "EC_CBC7";
BA_ "FlexKomComment" SG_ 1015 EC_CBC7B "CBC ecu configuration 7";
BA_ "FlexKomIsMotorola" SG_ 1015 EC_CBC7B 1;
BA_ "GenSigSNA" SG_ 1015 EC_CBC7B "0h";
BA_ "GenSigCycleTime" SG_ 1015 EC_CBC8 2000;
BA_ "FlexKomSigStartValue" SG_ 1015 EC_CBC8 "00000000h";
BA_ "FlexKomSID" SG_ 1015 EC_CBC8 1104;
BA_ "FlexKomSigStartPos" SG_ 1015 EC_CBC8 39;
BA_ "FlexKomSigLaenge" SG_ 1015 EC_CBC8 32;
BA_ "FlexKomSigName" SG_ 1015 EC_CBC8 "EC_CBC8";
BA_ "FlexKomComment" SG_ 1015 EC_CBC8 "CBC ecu configuration 8";
BA_ "FlexKomIsMotorola" SG_ 1015 EC_CBC8 1;
BA_ "GenSigSNA" SG_ 1015 EC_CBC8 "0h";
BA_ "GenSigSendType" SG_ 1016 EC_BU_ECUCfg1_Stat 1;
BA_ "FlexKomSigStartValue" SG_ 1016 EC_BU_ECUCfg1_Stat "03h";
BA_ "GenSigStartValue" SG_ 1016 EC_BU_ECUCfg1_Stat 3;
BA_ "FlexKomSID" SG_ 1016 EC_BU_ECUCfg1_Stat 1064;
BA_ "FlexKomSigStartPos" SG_ 1016 EC_BU_ECUCfg1_Stat 1;
BA_ "FlexKomSigLaenge" SG_ 1016 EC_BU_ECUCfg1_Stat 2;
BA_ "FlexKomSigName" SG_ 1016 EC_BU_ECUCfg1_Stat "EC_BU_ECUCfg1_Stat";
BA_ "FlexKomComment" SG_ 1016 EC_BU_ECUCfg1_Stat "Backup for ECU Configuration messages status 1";
BA_ "FlexKomIsMotorola" SG_ 1016 EC_BU_ECUCfg1_Stat 1;
BA_ "GenSigSNA" SG_ 1016 EC_BU_ECUCfg1_Stat "3h";
BA_ "GenSigSendType" SG_ 1016 EC_BU_CBC1A 1;
BA_ "FlexKomSigStartValue" SG_ 1016 EC_BU_CBC1A "00000000h";
BA_ "FlexKomSID" SG_ 1016 EC_BU_CBC1A 907;
BA_ "FlexKomSigStartPos" SG_ 1016 EC_BU_CBC1A 7;
BA_ "FlexKomSigLaenge" SG_ 1016 EC_BU_CBC1A 32;
BA_ "FlexKomSigName" SG_ 1016 EC_BU_CBC1A "EC_BU_CBC1";
BA_ "FlexKomComment" SG_ 1016 EC_BU_CBC1A "Backup for CBC ecu configuration 1";
BA_ "FlexKomIsMotorola" SG_ 1016 EC_BU_CBC1A 1;
BA_ "GenSigSNA" SG_ 1016 EC_BU_CBC1A "0h";
BA_ "GenSigSendType" SG_ 1016 EC_BU_CBC1B 1;
BA_ "FlexKomSigStartValue" SG_ 1016 EC_BU_CBC1B "00000000h";
BA_ "FlexKomSID" SG_ 1016 EC_BU_CBC1B 907;
BA_ "FlexKomSigStartPos" SG_ 1016 EC_BU_CBC1B 7;
BA_ "FlexKomSigLaenge" SG_ 1016 EC_BU_CBC1B 32;
BA_ "FlexKomSigName" SG_ 1016 EC_BU_CBC1B "EC_BU_CBC1";
BA_ "FlexKomComment" SG_ 1016 EC_BU_CBC1B "Backup for CBC ecu configuration 1";
BA_ "FlexKomIsMotorola" SG_ 1016 EC_BU_CBC1B 1;
BA_ "GenSigSNA" SG_ 1016 EC_BU_CBC1B "0h";
BA_ "GenSigSendType" SG_ 1016 EC_BU_CBC2 1;
BA_ "FlexKomSigStartValue" SG_ 1016 EC_BU_CBC2 "00000000h";
BA_ "FlexKomSID" SG_ 1016 EC_BU_CBC2 908;
BA_ "FlexKomSigStartPos" SG_ 1016 EC_BU_CBC2 39;
BA_ "FlexKomSigLaenge" SG_ 1016 EC_BU_CBC2 32;
BA_ "FlexKomSigName" SG_ 1016 EC_BU_CBC2 "EC_BU_CBC2";
BA_ "FlexKomComment" SG_ 1016 EC_BU_CBC2 "Backup for CBC ecu configuration 2";
BA_ "FlexKomIsMotorola" SG_ 1016 EC_BU_CBC2 1;
BA_ "GenSigSNA" SG_ 1016 EC_BU_CBC2 "0h";
BA_ "GenSigSendType" SG_ 1017 EC_BU_ECUCfg2_Stat 1;
BA_ "FlexKomSigStartValue" SG_ 1017 EC_BU_ECUCfg2_Stat "03h";
BA_ "GenSigStartValue" SG_ 1017 EC_BU_ECUCfg2_Stat 3;
BA_ "FlexKomSID" SG_ 1017 EC_BU_ECUCfg2_Stat 1065;
BA_ "FlexKomSigStartPos" SG_ 1017 EC_BU_ECUCfg2_Stat 1;
BA_ "FlexKomSigLaenge" SG_ 1017 EC_BU_ECUCfg2_Stat 2;
BA_ "FlexKomSigName" SG_ 1017 EC_BU_ECUCfg2_Stat "EC_BU_ECUCfg2_Stat";
BA_ "FlexKomComment" SG_ 1017 EC_BU_ECUCfg2_Stat "Backup for ECU Configuration messages status 2";
BA_ "FlexKomIsMotorola" SG_ 1017 EC_BU_ECUCfg2_Stat 1;
BA_ "GenSigSNA" SG_ 1017 EC_BU_ECUCfg2_Stat "3h";
BA_ "GenSigSendType" SG_ 1017 EC_BU_CBC3A 1;
BA_ "FlexKomSigStartValue" SG_ 1017 EC_BU_CBC3A "00000000h";
BA_ "FlexKomSID" SG_ 1017 EC_BU_CBC3A 909;
BA_ "FlexKomSigStartPos" SG_ 1017 EC_BU_CBC3A 7;
BA_ "FlexKomSigLaenge" SG_ 1017 EC_BU_CBC3A 32;
BA_ "FlexKomSigName" SG_ 1017 EC_BU_CBC3A "EC_BU_CBC3";
BA_ "FlexKomComment" SG_ 1017 EC_BU_CBC3A "Backup for CBC ecu configuration 3";
BA_ "FlexKomIsMotorola" SG_ 1017 EC_BU_CBC3A 1;
BA_ "GenSigSNA" SG_ 1017 EC_BU_CBC3A "0h";
BA_ "GenSigSendType" SG_ 1017 EC_BU_CBC3B 1;
BA_ "FlexKomSigStartValue" SG_ 1017 EC_BU_CBC3B "00000000h";
BA_ "FlexKomSID" SG_ 1017 EC_BU_CBC3B 909;
BA_ "FlexKomSigStartPos" SG_ 1017 EC_BU_CBC3B 7;
BA_ "FlexKomSigLaenge" SG_ 1017 EC_BU_CBC3B 32;
BA_ "FlexKomSigName" SG_ 1017 EC_BU_CBC3B "EC_BU_CBC3";
BA_ "FlexKomComment" SG_ 1017 EC_BU_CBC3B "Backup for CBC ecu configuration 3";
BA_ "FlexKomIsMotorola" SG_ 1017 EC_BU_CBC3B 1;
BA_ "GenSigSNA" SG_ 1017 EC_BU_CBC3B "0h";
BA_ "GenSigSendType" SG_ 1017 EC_BU_CBC4 1;
BA_ "FlexKomSigStartValue" SG_ 1017 EC_BU_CBC4 "00000000h";
BA_ "FlexKomSID" SG_ 1017 EC_BU_CBC4 910;
BA_ "FlexKomSigStartPos" SG_ 1017 EC_BU_CBC4 39;
BA_ "FlexKomSigLaenge" SG_ 1017 EC_BU_CBC4 32;
BA_ "FlexKomSigName" SG_ 1017 EC_BU_CBC4 "EC_BU_CBC4";
BA_ "FlexKomComment" SG_ 1017 EC_BU_CBC4 "Backup for CBC ecu configuration 4";
BA_ "FlexKomIsMotorola" SG_ 1017 EC_BU_CBC4 1;
BA_ "GenSigSNA" SG_ 1017 EC_BU_CBC4 "0h";
BA_ "GenSigSendType" SG_ 1018 EC_BU_ECUCfg3_Stat 1;
BA_ "FlexKomSigStartValue" SG_ 1018 EC_BU_ECUCfg3_Stat "03h";
BA_ "GenSigStartValue" SG_ 1018 EC_BU_ECUCfg3_Stat 3;
BA_ "FlexKomSID" SG_ 1018 EC_BU_ECUCfg3_Stat 1066;
BA_ "FlexKomSigStartPos" SG_ 1018 EC_BU_ECUCfg3_Stat 1;
BA_ "FlexKomSigLaenge" SG_ 1018 EC_BU_ECUCfg3_Stat 2;
BA_ "FlexKomSigName" SG_ 1018 EC_BU_ECUCfg3_Stat "EC_BU_ECUCfg3_Stat";
BA_ "FlexKomComment" SG_ 1018 EC_BU_ECUCfg3_Stat "Backup for ECU Configuration messages status 3";
BA_ "FlexKomIsMotorola" SG_ 1018 EC_BU_ECUCfg3_Stat 1;
BA_ "GenSigSNA" SG_ 1018 EC_BU_ECUCfg3_Stat "3h";
BA_ "GenSigSendType" SG_ 1018 EC_BU_AudTel1A 1;
BA_ "FlexKomSigStartValue" SG_ 1018 EC_BU_AudTel1A "00000000h";
BA_ "FlexKomSID" SG_ 1018 EC_BU_AudTel1A 904;
BA_ "FlexKomSigStartPos" SG_ 1018 EC_BU_AudTel1A 7;
BA_ "FlexKomSigLaenge" SG_ 1018 EC_BU_AudTel1A 32;
BA_ "FlexKomSigName" SG_ 1018 EC_BU_AudTel1A "EC_BU_AudTel1";
BA_ "FlexKomComment" SG_ 1018 EC_BU_AudTel1A "Backup for Audio and telematics ecu configuration ";
BA_ "FlexKomIsMotorola" SG_ 1018 EC_BU_AudTel1A 1;
BA_ "GenSigSNA" SG_ 1018 EC_BU_AudTel1A "0h";
BA_ "GenSigSendType" SG_ 1018 EC_BU_AudTel1B 1;
BA_ "FlexKomSigStartValue" SG_ 1018 EC_BU_AudTel1B "00000000h";
BA_ "FlexKomSID" SG_ 1018 EC_BU_AudTel1B 904;
BA_ "FlexKomSigStartPos" SG_ 1018 EC_BU_AudTel1B 7;
BA_ "FlexKomSigLaenge" SG_ 1018 EC_BU_AudTel1B 32;
BA_ "FlexKomSigName" SG_ 1018 EC_BU_AudTel1B "EC_BU_AudTel1";
BA_ "FlexKomComment" SG_ 1018 EC_BU_AudTel1B "Backup for Audio and telematics ecu configuration ";
BA_ "FlexKomIsMotorola" SG_ 1018 EC_BU_AudTel1B 1;
BA_ "GenSigSNA" SG_ 1018 EC_BU_AudTel1B "0h";
BA_ "GenSigSendType" SG_ 1018 EC_BU_AudTel2 1;
BA_ "FlexKomSigStartValue" SG_ 1018 EC_BU_AudTel2 "00000000h";
BA_ "FlexKomSID" SG_ 1018 EC_BU_AudTel2 905;
BA_ "FlexKomSigStartPos" SG_ 1018 EC_BU_AudTel2 39;
BA_ "FlexKomSigLaenge" SG_ 1018 EC_BU_AudTel2 32;
BA_ "FlexKomSigName" SG_ 1018 EC_BU_AudTel2 "EC_BU_AudTel2";
BA_ "FlexKomComment" SG_ 1018 EC_BU_AudTel2 "Backup for Audio and telematics ecu configuration ";
BA_ "FlexKomIsMotorola" SG_ 1018 EC_BU_AudTel2 1;
BA_ "GenSigSNA" SG_ 1018 EC_BU_AudTel2 "0h";
BA_ "GenSigSendType" SG_ 1019 EC_BU_ECUCfg4_Stat 1;
BA_ "FlexKomSigStartValue" SG_ 1019 EC_BU_ECUCfg4_Stat "03h";
BA_ "GenSigStartValue" SG_ 1019 EC_BU_ECUCfg4_Stat 3;
BA_ "FlexKomSID" SG_ 1019 EC_BU_ECUCfg4_Stat 1067;
BA_ "FlexKomSigStartPos" SG_ 1019 EC_BU_ECUCfg4_Stat 1;
BA_ "FlexKomSigLaenge" SG_ 1019 EC_BU_ECUCfg4_Stat 2;
BA_ "FlexKomSigName" SG_ 1019 EC_BU_ECUCfg4_Stat "EC_BU_ECUCfg4_Stat";
BA_ "FlexKomComment" SG_ 1019 EC_BU_ECUCfg4_Stat "Backup for ECU Configuration messages status 4";
BA_ "FlexKomIsMotorola" SG_ 1019 EC_BU_ECUCfg4_Stat 1;
BA_ "GenSigSNA" SG_ 1019 EC_BU_ECUCfg4_Stat "3h";
BA_ "GenSigSendType" SG_ 1019 EC_BU_Cluster1A 1;
BA_ "FlexKomSigStartValue" SG_ 1019 EC_BU_Cluster1A "00000000h";
BA_ "FlexKomSID" SG_ 1019 EC_BU_Cluster1A 911;
BA_ "FlexKomSigStartPos" SG_ 1019 EC_BU_Cluster1A 7;
BA_ "FlexKomSigLaenge" SG_ 1019 EC_BU_Cluster1A 32;
BA_ "FlexKomSigName" SG_ 1019 EC_BU_Cluster1A "EC_BU_Cluster1";
BA_ "FlexKomComment" SG_ 1019 EC_BU_Cluster1A "Backup for Instrument cluster ecu configuration 1";
BA_ "FlexKomIsMotorola" SG_ 1019 EC_BU_Cluster1A 1;
BA_ "GenSigSNA" SG_ 1019 EC_BU_Cluster1A "0h";
BA_ "GenSigSendType" SG_ 1019 EC_BU_Cluster1B 1;
BA_ "FlexKomSigStartValue" SG_ 1019 EC_BU_Cluster1B "00000000h";
BA_ "FlexKomSID" SG_ 1019 EC_BU_Cluster1B 911;
BA_ "FlexKomSigStartPos" SG_ 1019 EC_BU_Cluster1B 7;
BA_ "FlexKomSigLaenge" SG_ 1019 EC_BU_Cluster1B 32;
BA_ "FlexKomSigName" SG_ 1019 EC_BU_Cluster1B "EC_BU_Cluster1";
BA_ "FlexKomComment" SG_ 1019 EC_BU_Cluster1B "Backup for Instrument cluster ecu configuration 1";
BA_ "FlexKomIsMotorola" SG_ 1019 EC_BU_Cluster1B 1;
BA_ "GenSigSNA" SG_ 1019 EC_BU_Cluster1B "0h";
BA_ "GenSigSendType" SG_ 1019 EC_BU_Cluster2 1;
BA_ "FlexKomSigStartValue" SG_ 1019 EC_BU_Cluster2 "00000000h";
BA_ "FlexKomSID" SG_ 1019 EC_BU_Cluster2 912;
BA_ "FlexKomSigStartPos" SG_ 1019 EC_BU_Cluster2 39;
BA_ "FlexKomSigLaenge" SG_ 1019 EC_BU_Cluster2 32;
BA_ "FlexKomSigName" SG_ 1019 EC_BU_Cluster2 "EC_BU_Cluster2";
BA_ "FlexKomComment" SG_ 1019 EC_BU_Cluster2 "Backup for Instrument cluster ecu configuration 2";
BA_ "FlexKomIsMotorola" SG_ 1019 EC_BU_Cluster2 1;
BA_ "GenSigSNA" SG_ 1019 EC_BU_Cluster2 "0h";
BA_ "GenSigSendType" SG_ 1020 EC_BU_ECUCfg5_Stat 1;
BA_ "FlexKomSigStartValue" SG_ 1020 EC_BU_ECUCfg5_Stat "03h";
BA_ "GenSigStartValue" SG_ 1020 EC_BU_ECUCfg5_Stat 3;
BA_ "FlexKomSID" SG_ 1020 EC_BU_ECUCfg5_Stat 1068;
BA_ "FlexKomSigStartPos" SG_ 1020 EC_BU_ECUCfg5_Stat 1;
BA_ "FlexKomSigLaenge" SG_ 1020 EC_BU_ECUCfg5_Stat 2;
BA_ "FlexKomSigName" SG_ 1020 EC_BU_ECUCfg5_Stat "EC_BU_ECUCfg5_Stat";
BA_ "FlexKomComment" SG_ 1020 EC_BU_ECUCfg5_Stat "Backup for ECU Configuration messages status 5";
BA_ "FlexKomIsMotorola" SG_ 1020 EC_BU_ECUCfg5_Stat 1;
BA_ "GenSigSNA" SG_ 1020 EC_BU_ECUCfg5_Stat "3h";
BA_ "GenSigSendType" SG_ 1020 EC_BU_WirelessA 1;
BA_ "FlexKomSigStartValue" SG_ 1020 EC_BU_WirelessA "000000h";
BA_ "FlexKomSID" SG_ 1020 EC_BU_WirelessA 915;
BA_ "FlexKomSigStartPos" SG_ 1020 EC_BU_WirelessA 7;
BA_ "FlexKomSigLaenge" SG_ 1020 EC_BU_WirelessA 24;
BA_ "FlexKomSigName" SG_ 1020 EC_BU_WirelessA "EC_BU_Wireless";
BA_ "FlexKomComment" SG_ 1020 EC_BU_WirelessA "Backup for Wireless ecu configuration";
BA_ "FlexKomIsMotorola" SG_ 1020 EC_BU_WirelessA 1;
BA_ "GenSigSNA" SG_ 1020 EC_BU_WirelessA "0h";
BA_ "GenSigSendType" SG_ 1020 EC_BU_WirelessB 1;
BA_ "FlexKomSigStartValue" SG_ 1020 EC_BU_WirelessB "000000h";
BA_ "FlexKomSID" SG_ 1020 EC_BU_WirelessB 915;
BA_ "FlexKomSigStartPos" SG_ 1020 EC_BU_WirelessB 7;
BA_ "FlexKomSigLaenge" SG_ 1020 EC_BU_WirelessB 24;
BA_ "FlexKomSigName" SG_ 1020 EC_BU_WirelessB "EC_BU_Wireless";
BA_ "FlexKomComment" SG_ 1020 EC_BU_WirelessB "Backup for Wireless ecu configuration";
BA_ "FlexKomIsMotorola" SG_ 1020 EC_BU_WirelessB 1;
BA_ "GenSigSNA" SG_ 1020 EC_BU_WirelessB "0h";
BA_ "GenSigSendType" SG_ 1020 EC_BU_Doors 1;
BA_ "FlexKomSigStartValue" SG_ 1020 EC_BU_Doors "000000h";
BA_ "FlexKomSID" SG_ 1020 EC_BU_Doors 913;
BA_ "FlexKomSigStartPos" SG_ 1020 EC_BU_Doors 31;
BA_ "FlexKomSigLaenge" SG_ 1020 EC_BU_Doors 24;
BA_ "FlexKomSigName" SG_ 1020 EC_BU_Doors "EC_BU_Doors";
BA_ "FlexKomComment" SG_ 1020 EC_BU_Doors "Backup for Doors ecu configuration";
BA_ "FlexKomIsMotorola" SG_ 1020 EC_BU_Doors 1;
BA_ "GenSigSNA" SG_ 1020 EC_BU_Doors "0h";
BA_ "GenSigSendType" SG_ 1020 EC_BU_Memory 1;
BA_ "FlexKomSigStartValue" SG_ 1020 EC_BU_Memory "0000h";
BA_ "FlexKomSID" SG_ 1020 EC_BU_Memory 916;
BA_ "FlexKomSigStartPos" SG_ 1020 EC_BU_Memory 55;
BA_ "FlexKomSigLaenge" SG_ 1020 EC_BU_Memory 16;
BA_ "FlexKomSigName" SG_ 1020 EC_BU_Memory "EC_BU_Memory";
BA_ "FlexKomComment" SG_ 1020 EC_BU_Memory "Backup for Memory ecu configuration";
BA_ "FlexKomIsMotorola" SG_ 1020 EC_BU_Memory 1;
BA_ "GenSigSNA" SG_ 1020 EC_BU_Memory "0h";
BA_ "GenSigSendType" SG_ 1021 EC_BU_ECUCfg6_Stat 1;
BA_ "FlexKomSigStartValue" SG_ 1021 EC_BU_ECUCfg6_Stat "03h";
BA_ "GenSigStartValue" SG_ 1021 EC_BU_ECUCfg6_Stat 3;
BA_ "FlexKomSID" SG_ 1021 EC_BU_ECUCfg6_Stat 1069;
BA_ "FlexKomSigStartPos" SG_ 1021 EC_BU_ECUCfg6_Stat 1;
BA_ "FlexKomSigLaenge" SG_ 1021 EC_BU_ECUCfg6_Stat 2;
BA_ "FlexKomSigName" SG_ 1021 EC_BU_ECUCfg6_Stat "EC_BU_ECUCfg6_Stat";
BA_ "FlexKomComment" SG_ 1021 EC_BU_ECUCfg6_Stat "Backup for ECU Configuration messages status 6";
BA_ "FlexKomIsMotorola" SG_ 1021 EC_BU_ECUCfg6_Stat 1;
BA_ "GenSigSNA" SG_ 1021 EC_BU_ECUCfg6_Stat "3h";
BA_ "GenSigSendType" SG_ 1021 EC_BU_BrakesA 1;
BA_ "FlexKomSigStartValue" SG_ 1021 EC_BU_BrakesA "0000h";
BA_ "FlexKomSID" SG_ 1021 EC_BU_BrakesA 906;
BA_ "FlexKomSigStartPos" SG_ 1021 EC_BU_BrakesA 7;
BA_ "FlexKomSigLaenge" SG_ 1021 EC_BU_BrakesA 16;
BA_ "FlexKomSigName" SG_ 1021 EC_BU_BrakesA "EC_BU_Brakes";
BA_ "FlexKomComment" SG_ 1021 EC_BU_BrakesA "Backup for Brake system ecu configuration";
BA_ "FlexKomIsMotorola" SG_ 1021 EC_BU_BrakesA 1;
BA_ "GenSigSNA" SG_ 1021 EC_BU_BrakesA "0h";
BA_ "GenSigSendType" SG_ 1021 EC_BU_BrakesB 1;
BA_ "FlexKomSigStartValue" SG_ 1021 EC_BU_BrakesB "0000h";
BA_ "FlexKomSID" SG_ 1021 EC_BU_BrakesB 906;
BA_ "FlexKomSigStartPos" SG_ 1021 EC_BU_BrakesB 7;
BA_ "FlexKomSigLaenge" SG_ 1021 EC_BU_BrakesB 16;
BA_ "FlexKomSigName" SG_ 1021 EC_BU_BrakesB "EC_BU_Brakes";
BA_ "FlexKomComment" SG_ 1021 EC_BU_BrakesB "Backup for Brake system ecu configuration";
BA_ "FlexKomIsMotorola" SG_ 1021 EC_BU_BrakesB 1;
BA_ "GenSigSNA" SG_ 1021 EC_BU_BrakesB "0h";
BA_ "GenSigSendType" SG_ 1021 EC_BU_Steering 1;
BA_ "FlexKomSigStartValue" SG_ 1021 EC_BU_Steering "0000h";
BA_ "FlexKomSID" SG_ 1021 EC_BU_Steering 1981;
BA_ "FlexKomSigStartPos" SG_ 1021 EC_BU_Steering 23;
BA_ "FlexKomSigLaenge" SG_ 1021 EC_BU_Steering 16;
BA_ "FlexKomSigName" SG_ 1021 EC_BU_Steering "EC_BU_Steering";
BA_ "FlexKomComment" SG_ 1021 EC_BU_Steering "Backup for steering ecu configuration";
BA_ "FlexKomIsMotorola" SG_ 1021 EC_BU_Steering 1;
BA_ "GenSigSNA" SG_ 1021 EC_BU_Steering "0h";
BA_ "GenSigSendType" SG_ 1021 EC_BU_Powertrain 1;
BA_ "FlexKomSigStartValue" SG_ 1021 EC_BU_Powertrain "0000h";
BA_ "FlexKomSID" SG_ 1021 EC_BU_Powertrain 917;
BA_ "FlexKomSigStartPos" SG_ 1021 EC_BU_Powertrain 39;
BA_ "FlexKomSigLaenge" SG_ 1021 EC_BU_Powertrain 16;
BA_ "FlexKomSigName" SG_ 1021 EC_BU_Powertrain "EC_BU_Powertrain";
BA_ "FlexKomComment" SG_ 1021 EC_BU_Powertrain "Backup for Powertrain ecu configuration";
BA_ "FlexKomIsMotorola" SG_ 1021 EC_BU_Powertrain 1;
BA_ "GenSigSNA" SG_ 1021 EC_BU_Powertrain "0h";
BA_ "GenSigSendType" SG_ 1021 EC_BU_Safety 1;
BA_ "FlexKomSigStartValue" SG_ 1021 EC_BU_Safety "0000h";
BA_ "FlexKomSID" SG_ 1021 EC_BU_Safety 918;
BA_ "FlexKomSigStartPos" SG_ 1021 EC_BU_Safety 55;
BA_ "FlexKomSigLaenge" SG_ 1021 EC_BU_Safety 16;
BA_ "FlexKomSigName" SG_ 1021 EC_BU_Safety "EC_BU_Safety";
BA_ "FlexKomComment" SG_ 1021 EC_BU_Safety "Backup for Safety ecu configuration";
BA_ "FlexKomIsMotorola" SG_ 1021 EC_BU_Safety 1;
BA_ "GenSigSNA" SG_ 1021 EC_BU_Safety "0h";
BA_ "GenSigSendType" SG_ 1022 EC_BU_ECUCfg7_Stat 1;
BA_ "FlexKomSigStartValue" SG_ 1022 EC_BU_ECUCfg7_Stat "03h";
BA_ "GenSigStartValue" SG_ 1022 EC_BU_ECUCfg7_Stat 3;
BA_ "FlexKomSID" SG_ 1022 EC_BU_ECUCfg7_Stat 1097;
BA_ "FlexKomSigStartPos" SG_ 1022 EC_BU_ECUCfg7_Stat 1;
BA_ "FlexKomSigLaenge" SG_ 1022 EC_BU_ECUCfg7_Stat 2;
BA_ "FlexKomSigName" SG_ 1022 EC_BU_ECUCfg7_Stat "EC_BU_ECUCfg7_Stat";
BA_ "FlexKomComment" SG_ 1022 EC_BU_ECUCfg7_Stat "Backup for ECU Configuration messages status 7";
BA_ "FlexKomIsMotorola" SG_ 1022 EC_BU_ECUCfg7_Stat 1;
BA_ "GenSigSNA" SG_ 1022 EC_BU_ECUCfg7_Stat "3h";
BA_ "GenSigSendType" SG_ 1022 EC_BU_CBC5A 1;
BA_ "FlexKomSigStartValue" SG_ 1022 EC_BU_CBC5A "00000000h";
BA_ "FlexKomSID" SG_ 1022 EC_BU_CBC5A 1099;
BA_ "FlexKomSigStartPos" SG_ 1022 EC_BU_CBC5A 7;
BA_ "FlexKomSigLaenge" SG_ 1022 EC_BU_CBC5A 32;
BA_ "FlexKomSigName" SG_ 1022 EC_BU_CBC5A "EC_BU_CBC5";
BA_ "FlexKomComment" SG_ 1022 EC_BU_CBC5A "Backup for CBC ecu configuration 5";
BA_ "FlexKomIsMotorola" SG_ 1022 EC_BU_CBC5A 1;
BA_ "GenSigSNA" SG_ 1022 EC_BU_CBC5A "0h";
BA_ "GenSigSendType" SG_ 1022 EC_BU_CBC5B 1;
BA_ "FlexKomSigStartValue" SG_ 1022 EC_BU_CBC5B "00000000h";
BA_ "FlexKomSID" SG_ 1022 EC_BU_CBC5B 1099;
BA_ "FlexKomSigStartPos" SG_ 1022 EC_BU_CBC5B 7;
BA_ "FlexKomSigLaenge" SG_ 1022 EC_BU_CBC5B 32;
BA_ "FlexKomSigName" SG_ 1022 EC_BU_CBC5B "EC_BU_CBC5";
BA_ "FlexKomComment" SG_ 1022 EC_BU_CBC5B "Backup for CBC ecu configuration 5";
BA_ "FlexKomIsMotorola" SG_ 1022 EC_BU_CBC5B 1;
BA_ "GenSigSNA" SG_ 1022 EC_BU_CBC5B "0h";
BA_ "GenSigSendType" SG_ 1022 EC_BU_CBC6 1;
BA_ "FlexKomSigStartValue" SG_ 1022 EC_BU_CBC6 "00000000h";
BA_ "FlexKomSID" SG_ 1022 EC_BU_CBC6 1096;
BA_ "FlexKomSigStartPos" SG_ 1022 EC_BU_CBC6 39;
BA_ "FlexKomSigLaenge" SG_ 1022 EC_BU_CBC6 32;
BA_ "FlexKomSigName" SG_ 1022 EC_BU_CBC6 "EC_BU_CBC6";
BA_ "FlexKomComment" SG_ 1022 EC_BU_CBC6 "Backup for CBC ecu configuration 6";
BA_ "FlexKomIsMotorola" SG_ 1022 EC_BU_CBC6 1;
BA_ "GenSigSNA" SG_ 1022 EC_BU_CBC6 "0h";
BA_ "GenSigSendType" SG_ 1023 EC_BU_ECUCfg8_Stat 1;
BA_ "FlexKomSigStartValue" SG_ 1023 EC_BU_ECUCfg8_Stat "03h";
BA_ "GenSigStartValue" SG_ 1023 EC_BU_ECUCfg8_Stat 3;
BA_ "FlexKomSID" SG_ 1023 EC_BU_ECUCfg8_Stat 1098;
BA_ "FlexKomSigStartPos" SG_ 1023 EC_BU_ECUCfg8_Stat 1;
BA_ "FlexKomSigLaenge" SG_ 1023 EC_BU_ECUCfg8_Stat 2;
BA_ "FlexKomSigName" SG_ 1023 EC_BU_ECUCfg8_Stat "EC_BU_ECUCfg8_Stat";
BA_ "FlexKomComment" SG_ 1023 EC_BU_ECUCfg8_Stat "Backup for ECU Configuration messages status 8";
BA_ "FlexKomIsMotorola" SG_ 1023 EC_BU_ECUCfg8_Stat 1;
BA_ "GenSigSNA" SG_ 1023 EC_BU_ECUCfg8_Stat "3h";
BA_ "GenSigSendType" SG_ 1023 EC_BU_CBC7A 1;
BA_ "FlexKomSigStartValue" SG_ 1023 EC_BU_CBC7A "00000000h";
BA_ "FlexKomSID" SG_ 1023 EC_BU_CBC7A 1100;
BA_ "FlexKomSigStartPos" SG_ 1023 EC_BU_CBC7A 7;
BA_ "FlexKomSigLaenge" SG_ 1023 EC_BU_CBC7A 32;
BA_ "FlexKomSigName" SG_ 1023 EC_BU_CBC7A "EC_BU_CBC7";
BA_ "FlexKomComment" SG_ 1023 EC_BU_CBC7A "Backup for CBC ecu configuration 7";
BA_ "FlexKomIsMotorola" SG_ 1023 EC_BU_CBC7A 1;
BA_ "GenSigSNA" SG_ 1023 EC_BU_CBC7A "0h";
BA_ "GenSigSendType" SG_ 1023 EC_BU_CBC7B 1;
BA_ "FlexKomSigStartValue" SG_ 1023 EC_BU_CBC7B "00000000h";
BA_ "FlexKomSID" SG_ 1023 EC_BU_CBC7B 1100;
BA_ "FlexKomSigStartPos" SG_ 1023 EC_BU_CBC7B 7;
BA_ "FlexKomSigLaenge" SG_ 1023 EC_BU_CBC7B 32;
BA_ "FlexKomSigName" SG_ 1023 EC_BU_CBC7B "EC_BU_CBC7";
BA_ "FlexKomComment" SG_ 1023 EC_BU_CBC7B "Backup for CBC ecu configuration 7";
BA_ "FlexKomIsMotorola" SG_ 1023 EC_BU_CBC7B 1;
BA_ "GenSigSNA" SG_ 1023 EC_BU_CBC7B "0h";
BA_ "GenSigSendType" SG_ 1023 EC_BU_CBC8 1;
BA_ "FlexKomSigStartValue" SG_ 1023 EC_BU_CBC8 "00000000h";
BA_ "FlexKomSID" SG_ 1023 EC_BU_CBC8 1095;
BA_ "FlexKomSigStartPos" SG_ 1023 EC_BU_CBC8 39;
BA_ "FlexKomSigLaenge" SG_ 1023 EC_BU_CBC8 32;
BA_ "FlexKomSigName" SG_ 1023 EC_BU_CBC8 "EC_BU_CBC8";
BA_ "FlexKomComment" SG_ 1023 EC_BU_CBC8 "Backup for CBC ecu configuration 8";
BA_ "FlexKomIsMotorola" SG_ 1023 EC_BU_CBC8 1;
BA_ "GenSigSNA" SG_ 1023 EC_BU_CBC8 "0h";
BA_ "FlexKomSigStartValue" SG_ 1024 NM_Mode "FFFFFFFFh";
BA_ "GenSigStartValue" SG_ 1024 NM_Mode 255;
BA_ "FlexKomSID" SG_ 1024 NM_Mode 472;
BA_ "FlexKomSigStartPos" SG_ 1024 NM_Mode 7;
BA_ "FlexKomSigLaenge" SG_ 1024 NM_Mode 32;
BA_ "FlexKomSigName" SG_ 1024 NM_Mode "NM";
BA_ "FlexKomComment" SG_ 1024 NM_Mode "Network management state";
BA_ "FlexKomIsMotorola" SG_ 1024 NM_Mode 1;
BA_ "GenSigSNA" SG_ 1024 NM_Mode "FFh";
BA_ "FlexKomSigStartValue" SG_ 1024 NM_Successor "FFFFFFFFh";
BA_ "GenSigStartValue" SG_ 1024 NM_Successor 255;
BA_ "FlexKomSID" SG_ 1024 NM_Successor 472;
BA_ "FlexKomSigStartPos" SG_ 1024 NM_Successor 7;
BA_ "FlexKomSigLaenge" SG_ 1024 NM_Successor 32;
BA_ "FlexKomSigName" SG_ 1024 NM_Successor "NM";
BA_ "FlexKomComment" SG_ 1024 NM_Successor "Network management state";
BA_ "FlexKomIsMotorola" SG_ 1024 NM_Successor 1;
BA_ "GenSigSNA" SG_ 1024 NM_Successor "FFh";
BA_ "FlexKomSigStartValue" SG_ 1024 NM_Ud_Launch "FFFFFFFFh";
BA_ "GenSigStartValue" SG_ 1024 NM_Ud_Launch 63;
BA_ "FlexKomSID" SG_ 1024 NM_Ud_Launch 472;
BA_ "FlexKomSigStartPos" SG_ 1024 NM_Ud_Launch 7;
BA_ "FlexKomSigLaenge" SG_ 1024 NM_Ud_Launch 32;
BA_ "FlexKomSigName" SG_ 1024 NM_Ud_Launch "NM";
BA_ "FlexKomComment" SG_ 1024 NM_Ud_Launch "Network management state";
BA_ "FlexKomIsMotorola" SG_ 1024 NM_Ud_Launch 1;
BA_ "GenSigSNA" SG_ 1024 NM_Ud_Launch "3Fh";
BA_ "FlexKomSigStartValue" SG_ 1024 NM_Sleep_Ack "FFFFFFFFh";
BA_ "GenSigStartValue" SG_ 1024 NM_Sleep_Ack 1;
BA_ "FlexKomSID" SG_ 1024 NM_Sleep_Ack 472;
BA_ "FlexKomSigStartPos" SG_ 1024 NM_Sleep_Ack 7;
BA_ "FlexKomSigLaenge" SG_ 1024 NM_Sleep_Ack 32;
BA_ "FlexKomSigName" SG_ 1024 NM_Sleep_Ack "NM";
BA_ "FlexKomComment" SG_ 1024 NM_Sleep_Ack "Network management state";
BA_ "FlexKomIsMotorola" SG_ 1024 NM_Sleep_Ack 1;
BA_ "GenSigSNA" SG_ 1024 NM_Sleep_Ack "1h";
BA_ "FlexKomSigStartValue" SG_ 1024 NM_Sleep_Ind "FFFFFFFFh";
BA_ "GenSigStartValue" SG_ 1024 NM_Sleep_Ind 1;
BA_ "FlexKomSID" SG_ 1024 NM_Sleep_Ind 472;
BA_ "FlexKomSigStartPos" SG_ 1024 NM_Sleep_Ind 7;
BA_ "FlexKomSigLaenge" SG_ 1024 NM_Sleep_Ind 32;
BA_ "FlexKomSigName" SG_ 1024 NM_Sleep_Ind "NM";
BA_ "FlexKomComment" SG_ 1024 NM_Sleep_Ind "Network management state";
BA_ "FlexKomIsMotorola" SG_ 1024 NM_Sleep_Ind 1;
BA_ "GenSigSNA" SG_ 1024 NM_Sleep_Ind "1h";
BA_ "FlexKomSigStartValue" SG_ 1024 NM_Ud_Srv "FFFFFFFFh";
BA_ "GenSigStartValue" SG_ 1024 NM_Ud_Srv 255;
BA_ "FlexKomSID" SG_ 1024 NM_Ud_Srv 472;
BA_ "FlexKomSigStartPos" SG_ 1024 NM_Ud_Srv 7;
BA_ "FlexKomSigLaenge" SG_ 1024 NM_Ud_Srv 32;
BA_ "FlexKomSigName" SG_ 1024 NM_Ud_Srv "NM";
BA_ "FlexKomComment" SG_ 1024 NM_Ud_Srv "Network management state";
BA_ "FlexKomIsMotorola" SG_ 1024 NM_Ud_Srv 1;
BA_ "GenSigSNA" SG_ 1024 NM_Ud_Srv "FFh";
BA_ "FlexKomSigStartValue" SG_ 1024 Awake_NwSt "000000h";
BA_ "FlexKomSID" SG_ 1024 Awake_NwSt 619;
BA_ "FlexKomSigStartPos" SG_ 1024 Awake_NwSt 39;
BA_ "FlexKomSigLaenge" SG_ 1024 Awake_NwSt 24;
BA_ "FlexKomSigName" SG_ 1024 Awake_NwSt "Awake_RF_HUB";
BA_ "FlexKomComment" SG_ 1024 Awake_NwSt "Mode 15 of NM_Ud_Srv";
BA_ "FlexKomIsMotorola" SG_ 1024 Awake_NwSt 1;
BA_ "GenSigSNA" SG_ 1024 Awake_NwSt "0h";
BA_ "FlexKomSigStartValue" SG_ 1024 WakeupRsn_RF_HUB "FFFF00h";
BA_ "GenSigStartValue" SG_ 1024 WakeupRsn_RF_HUB 255;
BA_ "FlexKomSID" SG_ 1024 WakeupRsn_RF_HUB 620;
BA_ "FlexKomSigStartPos" SG_ 1024 WakeupRsn_RF_HUB 39;
BA_ "FlexKomSigLaenge" SG_ 1024 WakeupRsn_RF_HUB 24;
BA_ "FlexKomSigName" SG_ 1024 WakeupRsn_RF_HUB "Wakeup_RF_HUB";
BA_ "FlexKomComment" SG_ 1024 WakeupRsn_RF_HUB "Mode 2 of NM_Ud_Srv";
BA_ "FlexKomIsMotorola" SG_ 1024 WakeupRsn_RF_HUB 1;
BA_ "GenSigSNA" SG_ 1024 WakeupRsn_RF_HUB "FFh";
BA_ "FlexKomSigStartValue" SG_ 1024 Awake_Diag_Actv "000000h";
BA_ "FlexKomSID" SG_ 1024 Awake_Diag_Actv 619;
BA_ "FlexKomSigStartPos" SG_ 1024 Awake_Diag_Actv 39;
BA_ "FlexKomSigLaenge" SG_ 1024 Awake_Diag_Actv 24;
BA_ "FlexKomSigName" SG_ 1024 Awake_Diag_Actv "Awake_RF_HUB";
BA_ "FlexKomComment" SG_ 1024 Awake_Diag_Actv "Mode 15 of NM_Ud_Srv";
BA_ "FlexKomIsMotorola" SG_ 1024 Awake_Diag_Actv 1;
BA_ "GenSigSNA" SG_ 1024 Awake_Diag_Actv "0h";
BA_ "FlexKomSigStartValue" SG_ 1024 WakeupCnt "FFFF00h";
BA_ "GenSigStartValue" SG_ 1024 WakeupCnt 255;
BA_ "FlexKomSID" SG_ 1024 WakeupCnt 620;
BA_ "FlexKomSigStartPos" SG_ 1024 WakeupCnt 39;
BA_ "FlexKomSigLaenge" SG_ 1024 WakeupCnt 24;
BA_ "FlexKomSigName" SG_ 1024 WakeupCnt "Wakeup_RF_HUB";
BA_ "FlexKomComment" SG_ 1024 WakeupCnt "Mode 2 of NM_Ud_Srv";
BA_ "FlexKomIsMotorola" SG_ 1024 WakeupCnt 1;
BA_ "GenSigSNA" SG_ 1024 WakeupCnt "FFh";
BA_ "FlexKomSigStartValue" SG_ 1024 Nw_Id "FFh";
BA_ "GenSigStartValue" SG_ 1024 Nw_Id 255;
BA_ "FlexKomSID" SG_ 1024 Nw_Id 535;
BA_ "FlexKomSigStartPos" SG_ 1024 Nw_Id 63;
BA_ "FlexKomSigLaenge" SG_ 1024 Nw_Id 8;
BA_ "FlexKomSigName" SG_ 1024 Nw_Id "Nw_Id";
BA_ "FlexKomComment" SG_ 1024 Nw_Id "Network identification no.";
BA_ "FlexKomIsMotorola" SG_ 1024 Nw_Id 1;
BA_ "GenSigSNA" SG_ 1024 Nw_Id "FFh";
BA_ "FlexKomSigStartValue" SG_ 1025 NM_Mode "FFFFFFFFh";
BA_ "GenSigStartValue" SG_ 1025 NM_Mode 255;
BA_ "FlexKomSID" SG_ 1025 NM_Mode 472;
BA_ "FlexKomSigStartPos" SG_ 1025 NM_Mode 7;
BA_ "FlexKomSigLaenge" SG_ 1025 NM_Mode 32;
BA_ "FlexKomSigName" SG_ 1025 NM_Mode "NM";
BA_ "FlexKomComment" SG_ 1025 NM_Mode "Network management state";
BA_ "FlexKomIsMotorola" SG_ 1025 NM_Mode 1;
BA_ "GenSigSNA" SG_ 1025 NM_Mode "FFh";
BA_ "FlexKomSigStartValue" SG_ 1025 NM_Successor "FFFFFFFFh";
BA_ "GenSigStartValue" SG_ 1025 NM_Successor 255;
BA_ "FlexKomSID" SG_ 1025 NM_Successor 472;
BA_ "FlexKomSigStartPos" SG_ 1025 NM_Successor 7;
BA_ "FlexKomSigLaenge" SG_ 1025 NM_Successor 32;
BA_ "FlexKomSigName" SG_ 1025 NM_Successor "NM";
BA_ "FlexKomComment" SG_ 1025 NM_Successor "Network management state";
BA_ "FlexKomIsMotorola" SG_ 1025 NM_Successor 1;
BA_ "GenSigSNA" SG_ 1025 NM_Successor "FFh";
BA_ "FlexKomSigStartValue" SG_ 1025 NM_Ud_Launch "FFFFFFFFh";
BA_ "GenSigStartValue" SG_ 1025 NM_Ud_Launch 63;
BA_ "FlexKomSID" SG_ 1025 NM_Ud_Launch 472;
BA_ "FlexKomSigStartPos" SG_ 1025 NM_Ud_Launch 7;
BA_ "FlexKomSigLaenge" SG_ 1025 NM_Ud_Launch 32;
BA_ "FlexKomSigName" SG_ 1025 NM_Ud_Launch "NM";
BA_ "FlexKomComment" SG_ 1025 NM_Ud_Launch "Network management state";
BA_ "FlexKomIsMotorola" SG_ 1025 NM_Ud_Launch 1;
BA_ "GenSigSNA" SG_ 1025 NM_Ud_Launch "3Fh";
BA_ "FlexKomSigStartValue" SG_ 1025 NM_Sleep_Ack "FFFFFFFFh";
BA_ "GenSigStartValue" SG_ 1025 NM_Sleep_Ack 1;
BA_ "FlexKomSID" SG_ 1025 NM_Sleep_Ack 472;
BA_ "FlexKomSigStartPos" SG_ 1025 NM_Sleep_Ack 7;
BA_ "FlexKomSigLaenge" SG_ 1025 NM_Sleep_Ack 32;
BA_ "FlexKomSigName" SG_ 1025 NM_Sleep_Ack "NM";
BA_ "FlexKomComment" SG_ 1025 NM_Sleep_Ack "Network management state";
BA_ "FlexKomIsMotorola" SG_ 1025 NM_Sleep_Ack 1;
BA_ "GenSigSNA" SG_ 1025 NM_Sleep_Ack "1h";
BA_ "FlexKomSigStartValue" SG_ 1025 NM_Sleep_Ind "FFFFFFFFh";
BA_ "GenSigStartValue" SG_ 1025 NM_Sleep_Ind 1;
BA_ "FlexKomSID" SG_ 1025 NM_Sleep_Ind 472;
BA_ "FlexKomSigStartPos" SG_ 1025 NM_Sleep_Ind 7;
BA_ "FlexKomSigLaenge" SG_ 1025 NM_Sleep_Ind 32;
BA_ "FlexKomSigName" SG_ 1025 NM_Sleep_Ind "NM";
BA_ "FlexKomComment" SG_ 1025 NM_Sleep_Ind "Network management state";
BA_ "FlexKomIsMotorola" SG_ 1025 NM_Sleep_Ind 1;
BA_ "GenSigSNA" SG_ 1025 NM_Sleep_Ind "1h";
BA_ "FlexKomSigStartValue" SG_ 1025 NM_Ud_Srv "FFFFFFFFh";
BA_ "GenSigStartValue" SG_ 1025 NM_Ud_Srv 255;
BA_ "FlexKomSID" SG_ 1025 NM_Ud_Srv 472;
BA_ "FlexKomSigStartPos" SG_ 1025 NM_Ud_Srv 7;
BA_ "FlexKomSigLaenge" SG_ 1025 NM_Ud_Srv 32;
BA_ "FlexKomSigName" SG_ 1025 NM_Ud_Srv "NM";
BA_ "FlexKomComment" SG_ 1025 NM_Ud_Srv "Network management state";
BA_ "FlexKomIsMotorola" SG_ 1025 NM_Ud_Srv 1;
BA_ "GenSigSNA" SG_ 1025 NM_Ud_Srv "FFh";
BA_ "FlexKomSigStartValue" SG_ 1025 Awake_NwSt "000000h";
BA_ "FlexKomSID" SG_ 1025 Awake_NwSt 504;
BA_ "FlexKomSigStartPos" SG_ 1025 Awake_NwSt 39;
BA_ "FlexKomSigLaenge" SG_ 1025 Awake_NwSt 24;
BA_ "FlexKomSigName" SG_ 1025 Awake_NwSt "Awake_CBC";
BA_ "FlexKomComment" SG_ 1025 Awake_NwSt "Mode 15 of NM_Ud_Srv";
BA_ "FlexKomIsMotorola" SG_ 1025 Awake_NwSt 1;
BA_ "GenSigSNA" SG_ 1025 Awake_NwSt "0h";
BA_ "FlexKomSigStartValue" SG_ 1025 WakeupRsn_CBC "FFFF00h";
BA_ "GenSigStartValue" SG_ 1025 WakeupRsn_CBC 255;
BA_ "FlexKomSID" SG_ 1025 WakeupRsn_CBC 474;
BA_ "FlexKomSigStartPos" SG_ 1025 WakeupRsn_CBC 39;
BA_ "FlexKomSigLaenge" SG_ 1025 WakeupRsn_CBC 24;
BA_ "FlexKomSigName" SG_ 1025 WakeupRsn_CBC "Wakeup_CBC";
BA_ "FlexKomComment" SG_ 1025 WakeupRsn_CBC "Mode 2 of NM_Ud_Srv";
BA_ "FlexKomIsMotorola" SG_ 1025 WakeupRsn_CBC 1;
BA_ "GenSigSNA" SG_ 1025 WakeupRsn_CBC "FFh";
BA_ "FlexKomSigStartValue" SG_ 1025 Awake_Diag_Actv "000000h";
BA_ "FlexKomSID" SG_ 1025 Awake_Diag_Actv 504;
BA_ "FlexKomSigStartPos" SG_ 1025 Awake_Diag_Actv 39;
BA_ "FlexKomSigLaenge" SG_ 1025 Awake_Diag_Actv 24;
BA_ "FlexKomSigName" SG_ 1025 Awake_Diag_Actv "Awake_CBC";
BA_ "FlexKomComment" SG_ 1025 Awake_Diag_Actv "Mode 15 of NM_Ud_Srv";
BA_ "FlexKomIsMotorola" SG_ 1025 Awake_Diag_Actv 1;
BA_ "GenSigSNA" SG_ 1025 Awake_Diag_Actv "0h";
BA_ "FlexKomSigStartValue" SG_ 1025 WakeupCnt "FFFF00h";
BA_ "GenSigStartValue" SG_ 1025 WakeupCnt 255;
BA_ "FlexKomSID" SG_ 1025 WakeupCnt 474;
BA_ "FlexKomSigStartPos" SG_ 1025 WakeupCnt 39;
BA_ "FlexKomSigLaenge" SG_ 1025 WakeupCnt 24;
BA_ "FlexKomSigName" SG_ 1025 WakeupCnt "Wakeup_CBC";
BA_ "FlexKomComment" SG_ 1025 WakeupCnt "Mode 2 of NM_Ud_Srv";
BA_ "FlexKomIsMotorola" SG_ 1025 WakeupCnt 1;
BA_ "GenSigSNA" SG_ 1025 WakeupCnt "FFh";
BA_ "FlexKomSigStartValue" SG_ 1025 Nw_Id "FFh";
BA_ "GenSigStartValue" SG_ 1025 Nw_Id 255;
BA_ "FlexKomSID" SG_ 1025 Nw_Id 535;
BA_ "FlexKomSigStartPos" SG_ 1025 Nw_Id 63;
BA_ "FlexKomSigLaenge" SG_ 1025 Nw_Id 8;
BA_ "FlexKomSigName" SG_ 1025 Nw_Id "Nw_Id";
BA_ "FlexKomComment" SG_ 1025 Nw_Id "Network identification no.";
BA_ "FlexKomIsMotorola" SG_ 1025 Nw_Id 1;
BA_ "GenSigSNA" SG_ 1025 Nw_Id "FFh";
BA_ "FlexKomSigStartValue" SG_ 1026 NM_Mode "FFFFFFFFh";
BA_ "GenSigStartValue" SG_ 1026 NM_Mode 255;
BA_ "FlexKomSID" SG_ 1026 NM_Mode 472;
BA_ "FlexKomSigStartPos" SG_ 1026 NM_Mode 7;
BA_ "FlexKomSigLaenge" SG_ 1026 NM_Mode 32;
BA_ "FlexKomSigName" SG_ 1026 NM_Mode "NM";
BA_ "FlexKomComment" SG_ 1026 NM_Mode "Network management state";
BA_ "FlexKomIsMotorola" SG_ 1026 NM_Mode 1;
BA_ "GenSigSNA" SG_ 1026 NM_Mode "FFh";
BA_ "FlexKomSigStartValue" SG_ 1026 NM_Successor "FFFFFFFFh";
BA_ "GenSigStartValue" SG_ 1026 NM_Successor 255;
BA_ "FlexKomSID" SG_ 1026 NM_Successor 472;
BA_ "FlexKomSigStartPos" SG_ 1026 NM_Successor 7;
BA_ "FlexKomSigLaenge" SG_ 1026 NM_Successor 32;
BA_ "FlexKomSigName" SG_ 1026 NM_Successor "NM";
BA_ "FlexKomComment" SG_ 1026 NM_Successor "Network management state";
BA_ "FlexKomIsMotorola" SG_ 1026 NM_Successor 1;
BA_ "GenSigSNA" SG_ 1026 NM_Successor "FFh";
BA_ "FlexKomSigStartValue" SG_ 1026 NM_Ud_Launch "FFFFFFFFh";
BA_ "GenSigStartValue" SG_ 1026 NM_Ud_Launch 63;
BA_ "FlexKomSID" SG_ 1026 NM_Ud_Launch 472;
BA_ "FlexKomSigStartPos" SG_ 1026 NM_Ud_Launch 7;
BA_ "FlexKomSigLaenge" SG_ 1026 NM_Ud_Launch 32;
BA_ "FlexKomSigName" SG_ 1026 NM_Ud_Launch "NM";
BA_ "FlexKomComment" SG_ 1026 NM_Ud_Launch "Network management state";
BA_ "FlexKomIsMotorola" SG_ 1026 NM_Ud_Launch 1;
BA_ "GenSigSNA" SG_ 1026 NM_Ud_Launch "3Fh";
BA_ "FlexKomSigStartValue" SG_ 1026 NM_Sleep_Ack "FFFFFFFFh";
BA_ "GenSigStartValue" SG_ 1026 NM_Sleep_Ack 1;
BA_ "FlexKomSID" SG_ 1026 NM_Sleep_Ack 472;
BA_ "FlexKomSigStartPos" SG_ 1026 NM_Sleep_Ack 7;
BA_ "FlexKomSigLaenge" SG_ 1026 NM_Sleep_Ack 32;
BA_ "FlexKomSigName" SG_ 1026 NM_Sleep_Ack "NM";
BA_ "FlexKomComment" SG_ 1026 NM_Sleep_Ack "Network management state";
BA_ "FlexKomIsMotorola" SG_ 1026 NM_Sleep_Ack 1;
BA_ "GenSigSNA" SG_ 1026 NM_Sleep_Ack "1h";
BA_ "FlexKomSigStartValue" SG_ 1026 NM_Sleep_Ind "FFFFFFFFh";
BA_ "GenSigStartValue" SG_ 1026 NM_Sleep_Ind 1;
BA_ "FlexKomSID" SG_ 1026 NM_Sleep_Ind 472;
BA_ "FlexKomSigStartPos" SG_ 1026 NM_Sleep_Ind 7;
BA_ "FlexKomSigLaenge" SG_ 1026 NM_Sleep_Ind 32;
BA_ "FlexKomSigName" SG_ 1026 NM_Sleep_Ind "NM";
BA_ "FlexKomComment" SG_ 1026 NM_Sleep_Ind "Network management state";
BA_ "FlexKomIsMotorola" SG_ 1026 NM_Sleep_Ind 1;
BA_ "GenSigSNA" SG_ 1026 NM_Sleep_Ind "1h";
BA_ "FlexKomSigStartValue" SG_ 1026 NM_Ud_Srv "FFFFFFFFh";
BA_ "GenSigStartValue" SG_ 1026 NM_Ud_Srv 255;
BA_ "FlexKomSID" SG_ 1026 NM_Ud_Srv 472;
BA_ "FlexKomSigStartPos" SG_ 1026 NM_Ud_Srv 7;
BA_ "FlexKomSigLaenge" SG_ 1026 NM_Ud_Srv 32;
BA_ "FlexKomSigName" SG_ 1026 NM_Ud_Srv "NM";
BA_ "FlexKomComment" SG_ 1026 NM_Ud_Srv "Network management state";
BA_ "FlexKomIsMotorola" SG_ 1026 NM_Ud_Srv 1;
BA_ "GenSigSNA" SG_ 1026 NM_Ud_Srv "FFh";
BA_ "FlexKomSigStartValue" SG_ 1026 Awake_NwSt "000000h";
BA_ "FlexKomSID" SG_ 1026 Awake_NwSt 512;
BA_ "FlexKomSigStartPos" SG_ 1026 Awake_NwSt 39;
BA_ "FlexKomSigLaenge" SG_ 1026 Awake_NwSt 24;
BA_ "FlexKomSigName" SG_ 1026 Awake_NwSt "Awake_IC";
BA_ "FlexKomComment" SG_ 1026 Awake_NwSt "Mode 15 of NM_Ud_Srv";
BA_ "FlexKomIsMotorola" SG_ 1026 Awake_NwSt 1;
BA_ "GenSigSNA" SG_ 1026 Awake_NwSt "0h";
BA_ "FlexKomSigStartValue" SG_ 1026 WakeupRsn_IC "FFFF00h";
BA_ "GenSigStartValue" SG_ 1026 WakeupRsn_IC 255;
BA_ "FlexKomSID" SG_ 1026 WakeupRsn_IC 482;
BA_ "FlexKomSigStartPos" SG_ 1026 WakeupRsn_IC 39;
BA_ "FlexKomSigLaenge" SG_ 1026 WakeupRsn_IC 24;
BA_ "FlexKomSigName" SG_ 1026 WakeupRsn_IC "Wakeup_IC";
BA_ "FlexKomComment" SG_ 1026 WakeupRsn_IC "Mode 2 of NM_Ud_Srv";
BA_ "FlexKomIsMotorola" SG_ 1026 WakeupRsn_IC 1;
BA_ "GenSigSNA" SG_ 1026 WakeupRsn_IC "FFh";
BA_ "FlexKomSigStartValue" SG_ 1026 Awake_Diag_Actv "000000h";
BA_ "FlexKomSID" SG_ 1026 Awake_Diag_Actv 512;
BA_ "FlexKomSigStartPos" SG_ 1026 Awake_Diag_Actv 39;
BA_ "FlexKomSigLaenge" SG_ 1026 Awake_Diag_Actv 24;
BA_ "FlexKomSigName" SG_ 1026 Awake_Diag_Actv "Awake_IC";
BA_ "FlexKomComment" SG_ 1026 Awake_Diag_Actv "Mode 15 of NM_Ud_Srv";
BA_ "FlexKomIsMotorola" SG_ 1026 Awake_Diag_Actv 1;
BA_ "GenSigSNA" SG_ 1026 Awake_Diag_Actv "0h";
BA_ "FlexKomSigStartValue" SG_ 1026 WakeupCnt "FFFF00h";
BA_ "GenSigStartValue" SG_ 1026 WakeupCnt 255;
BA_ "FlexKomSID" SG_ 1026 WakeupCnt 482;
BA_ "FlexKomSigStartPos" SG_ 1026 WakeupCnt 39;
BA_ "FlexKomSigLaenge" SG_ 1026 WakeupCnt 24;
BA_ "FlexKomSigName" SG_ 1026 WakeupCnt "Wakeup_IC";
BA_ "FlexKomComment" SG_ 1026 WakeupCnt "Mode 2 of NM_Ud_Srv";
BA_ "FlexKomIsMotorola" SG_ 1026 WakeupCnt 1;
BA_ "GenSigSNA" SG_ 1026 WakeupCnt "FFh";
BA_ "FlexKomSigStartValue" SG_ 1026 Nw_Id "FFh";
BA_ "GenSigStartValue" SG_ 1026 Nw_Id 255;
BA_ "FlexKomSID" SG_ 1026 Nw_Id 535;
BA_ "FlexKomSigStartPos" SG_ 1026 Nw_Id 63;
BA_ "FlexKomSigLaenge" SG_ 1026 Nw_Id 8;
BA_ "FlexKomSigName" SG_ 1026 Nw_Id "Nw_Id";
BA_ "FlexKomComment" SG_ 1026 Nw_Id "Network identification no.";
BA_ "FlexKomIsMotorola" SG_ 1026 Nw_Id 1;
BA_ "GenSigSNA" SG_ 1026 Nw_Id "FFh";
BA_ "FlexKomSigStartValue" SG_ 1027 NM_Mode "FFFFFFFFh";
BA_ "GenSigStartValue" SG_ 1027 NM_Mode 255;
BA_ "FlexKomSID" SG_ 1027 NM_Mode 472;
BA_ "FlexKomSigStartPos" SG_ 1027 NM_Mode 7;
BA_ "FlexKomSigLaenge" SG_ 1027 NM_Mode 32;
BA_ "FlexKomSigName" SG_ 1027 NM_Mode "NM";
BA_ "FlexKomComment" SG_ 1027 NM_Mode "Network management state";
BA_ "FlexKomIsMotorola" SG_ 1027 NM_Mode 1;
BA_ "GenSigSNA" SG_ 1027 NM_Mode "FFh";
BA_ "FlexKomSigStartValue" SG_ 1027 NM_Successor "FFFFFFFFh";
BA_ "GenSigStartValue" SG_ 1027 NM_Successor 255;
BA_ "FlexKomSID" SG_ 1027 NM_Successor 472;
BA_ "FlexKomSigStartPos" SG_ 1027 NM_Successor 7;
BA_ "FlexKomSigLaenge" SG_ 1027 NM_Successor 32;
BA_ "FlexKomSigName" SG_ 1027 NM_Successor "NM";
BA_ "FlexKomComment" SG_ 1027 NM_Successor "Network management state";
BA_ "FlexKomIsMotorola" SG_ 1027 NM_Successor 1;
BA_ "GenSigSNA" SG_ 1027 NM_Successor "FFh";
BA_ "FlexKomSigStartValue" SG_ 1027 NM_Ud_Launch "FFFFFFFFh";
BA_ "GenSigStartValue" SG_ 1027 NM_Ud_Launch 63;
BA_ "FlexKomSID" SG_ 1027 NM_Ud_Launch 472;
BA_ "FlexKomSigStartPos" SG_ 1027 NM_Ud_Launch 7;
BA_ "FlexKomSigLaenge" SG_ 1027 NM_Ud_Launch 32;
BA_ "FlexKomSigName" SG_ 1027 NM_Ud_Launch "NM";
BA_ "FlexKomComment" SG_ 1027 NM_Ud_Launch "Network management state";
BA_ "FlexKomIsMotorola" SG_ 1027 NM_Ud_Launch 1;
BA_ "GenSigSNA" SG_ 1027 NM_Ud_Launch "3Fh";
BA_ "FlexKomSigStartValue" SG_ 1027 NM_Sleep_Ack "FFFFFFFFh";
BA_ "GenSigStartValue" SG_ 1027 NM_Sleep_Ack 1;
BA_ "FlexKomSID" SG_ 1027 NM_Sleep_Ack 472;
BA_ "FlexKomSigStartPos" SG_ 1027 NM_Sleep_Ack 7;
BA_ "FlexKomSigLaenge" SG_ 1027 NM_Sleep_Ack 32;
BA_ "FlexKomSigName" SG_ 1027 NM_Sleep_Ack "NM";
BA_ "FlexKomComment" SG_ 1027 NM_Sleep_Ack "Network management state";
BA_ "FlexKomIsMotorola" SG_ 1027 NM_Sleep_Ack 1;
BA_ "GenSigSNA" SG_ 1027 NM_Sleep_Ack "1h";
BA_ "FlexKomSigStartValue" SG_ 1027 NM_Sleep_Ind "FFFFFFFFh";
BA_ "GenSigStartValue" SG_ 1027 NM_Sleep_Ind 1;
BA_ "FlexKomSID" SG_ 1027 NM_Sleep_Ind 472;
BA_ "FlexKomSigStartPos" SG_ 1027 NM_Sleep_Ind 7;
BA_ "FlexKomSigLaenge" SG_ 1027 NM_Sleep_Ind 32;
BA_ "FlexKomSigName" SG_ 1027 NM_Sleep_Ind "NM";
BA_ "FlexKomComment" SG_ 1027 NM_Sleep_Ind "Network management state";
BA_ "FlexKomIsMotorola" SG_ 1027 NM_Sleep_Ind 1;
BA_ "GenSigSNA" SG_ 1027 NM_Sleep_Ind "1h";
BA_ "FlexKomSigStartValue" SG_ 1027 NM_Ud_Srv "FFFFFFFFh";
BA_ "GenSigStartValue" SG_ 1027 NM_Ud_Srv 255;
BA_ "FlexKomSID" SG_ 1027 NM_Ud_Srv 472;
BA_ "FlexKomSigStartPos" SG_ 1027 NM_Ud_Srv 7;
BA_ "FlexKomSigLaenge" SG_ 1027 NM_Ud_Srv 32;
BA_ "FlexKomSigName" SG_ 1027 NM_Ud_Srv "NM";
BA_ "FlexKomComment" SG_ 1027 NM_Ud_Srv "Network management state";
BA_ "FlexKomIsMotorola" SG_ 1027 NM_Ud_Srv 1;
BA_ "GenSigSNA" SG_ 1027 NM_Ud_Srv "FFh";
BA_ "FlexKomSigStartValue" SG_ 1027 Awake_NwSt "000000h";
BA_ "FlexKomSID" SG_ 1027 Awake_NwSt 529;
BA_ "FlexKomSigStartPos" SG_ 1027 Awake_NwSt 39;
BA_ "FlexKomSigLaenge" SG_ 1027 Awake_NwSt 24;
BA_ "FlexKomSigName" SG_ 1027 Awake_NwSt "Awake_TPM";
BA_ "FlexKomComment" SG_ 1027 Awake_NwSt "Mode 15 of NM_Ud_Srv";
BA_ "FlexKomIsMotorola" SG_ 1027 Awake_NwSt 1;
BA_ "GenSigSNA" SG_ 1027 Awake_NwSt "0h";
BA_ "FlexKomSigStartValue" SG_ 1027 WakeupRsn_TPM "FFFF00h";
BA_ "GenSigStartValue" SG_ 1027 WakeupRsn_TPM 255;
BA_ "FlexKomSID" SG_ 1027 WakeupRsn_TPM 499;
BA_ "FlexKomSigStartPos" SG_ 1027 WakeupRsn_TPM 39;
BA_ "FlexKomSigLaenge" SG_ 1027 WakeupRsn_TPM 24;
BA_ "FlexKomSigName" SG_ 1027 WakeupRsn_TPM "Wakeup_TPM";
BA_ "FlexKomComment" SG_ 1027 WakeupRsn_TPM "Mode 2 of NM_Ud_Srv";
BA_ "FlexKomIsMotorola" SG_ 1027 WakeupRsn_TPM 1;
BA_ "GenSigSNA" SG_ 1027 WakeupRsn_TPM "FFh";
BA_ "FlexKomSigStartValue" SG_ 1027 Awake_Diag_Actv "000000h";
BA_ "FlexKomSID" SG_ 1027 Awake_Diag_Actv 529;
BA_ "FlexKomSigStartPos" SG_ 1027 Awake_Diag_Actv 39;
BA_ "FlexKomSigLaenge" SG_ 1027 Awake_Diag_Actv 24;
BA_ "FlexKomSigName" SG_ 1027 Awake_Diag_Actv "Awake_TPM";
BA_ "FlexKomComment" SG_ 1027 Awake_Diag_Actv "Mode 15 of NM_Ud_Srv";
BA_ "FlexKomIsMotorola" SG_ 1027 Awake_Diag_Actv 1;
BA_ "GenSigSNA" SG_ 1027 Awake_Diag_Actv "0h";
BA_ "FlexKomSigStartValue" SG_ 1027 WakeupCnt "FFFF00h";
BA_ "GenSigStartValue" SG_ 1027 WakeupCnt 255;
BA_ "FlexKomSID" SG_ 1027 WakeupCnt 499;
BA_ "FlexKomSigStartPos" SG_ 1027 WakeupCnt 39;
BA_ "FlexKomSigLaenge" SG_ 1027 WakeupCnt 24;
BA_ "FlexKomSigName" SG_ 1027 WakeupCnt "Wakeup_TPM";
BA_ "FlexKomComment" SG_ 1027 WakeupCnt "Mode 2 of NM_Ud_Srv";
BA_ "FlexKomIsMotorola" SG_ 1027 WakeupCnt 1;
BA_ "GenSigSNA" SG_ 1027 WakeupCnt "FFh";
BA_ "FlexKomSigStartValue" SG_ 1027 Nw_Id "FFh";
BA_ "GenSigStartValue" SG_ 1027 Nw_Id 255;
BA_ "FlexKomSID" SG_ 1027 Nw_Id 535;
BA_ "FlexKomSigStartPos" SG_ 1027 Nw_Id 63;
BA_ "FlexKomSigLaenge" SG_ 1027 Nw_Id 8;
BA_ "FlexKomSigName" SG_ 1027 Nw_Id "Nw_Id";
BA_ "FlexKomComment" SG_ 1027 Nw_Id "Network identification no.";
BA_ "FlexKomIsMotorola" SG_ 1027 Nw_Id 1;
BA_ "GenSigSNA" SG_ 1027 Nw_Id "FFh";
BA_ "FlexKomSigStartValue" SG_ 1029 NM_Mode "FFFFFFFFh";
BA_ "GenSigStartValue" SG_ 1029 NM_Mode 255;
BA_ "FlexKomSID" SG_ 1029 NM_Mode 472;
BA_ "FlexKomSigStartPos" SG_ 1029 NM_Mode 7;
BA_ "FlexKomSigLaenge" SG_ 1029 NM_Mode 32;
BA_ "FlexKomSigName" SG_ 1029 NM_Mode "NM";
BA_ "FlexKomComment" SG_ 1029 NM_Mode "Network management state";
BA_ "FlexKomIsMotorola" SG_ 1029 NM_Mode 1;
BA_ "GenSigSNA" SG_ 1029 NM_Mode "FFh";
BA_ "FlexKomSigStartValue" SG_ 1029 NM_Successor "FFFFFFFFh";
BA_ "GenSigStartValue" SG_ 1029 NM_Successor 255;
BA_ "FlexKomSID" SG_ 1029 NM_Successor 472;
BA_ "FlexKomSigStartPos" SG_ 1029 NM_Successor 7;
BA_ "FlexKomSigLaenge" SG_ 1029 NM_Successor 32;
BA_ "FlexKomSigName" SG_ 1029 NM_Successor "NM";
BA_ "FlexKomComment" SG_ 1029 NM_Successor "Network management state";
BA_ "FlexKomIsMotorola" SG_ 1029 NM_Successor 1;
BA_ "GenSigSNA" SG_ 1029 NM_Successor "FFh";
BA_ "FlexKomSigStartValue" SG_ 1029 NM_Ud_Launch "FFFFFFFFh";
BA_ "GenSigStartValue" SG_ 1029 NM_Ud_Launch 63;
BA_ "FlexKomSID" SG_ 1029 NM_Ud_Launch 472;
BA_ "FlexKomSigStartPos" SG_ 1029 NM_Ud_Launch 7;
BA_ "FlexKomSigLaenge" SG_ 1029 NM_Ud_Launch 32;
BA_ "FlexKomSigName" SG_ 1029 NM_Ud_Launch "NM";
BA_ "FlexKomComment" SG_ 1029 NM_Ud_Launch "Network management state";
BA_ "FlexKomIsMotorola" SG_ 1029 NM_Ud_Launch 1;
BA_ "GenSigSNA" SG_ 1029 NM_Ud_Launch "3Fh";
BA_ "FlexKomSigStartValue" SG_ 1029 NM_Sleep_Ack "FFFFFFFFh";
BA_ "GenSigStartValue" SG_ 1029 NM_Sleep_Ack 1;
BA_ "FlexKomSID" SG_ 1029 NM_Sleep_Ack 472;
BA_ "FlexKomSigStartPos" SG_ 1029 NM_Sleep_Ack 7;
BA_ "FlexKomSigLaenge" SG_ 1029 NM_Sleep_Ack 32;
BA_ "FlexKomSigName" SG_ 1029 NM_Sleep_Ack "NM";
BA_ "FlexKomComment" SG_ 1029 NM_Sleep_Ack "Network management state";
BA_ "FlexKomIsMotorola" SG_ 1029 NM_Sleep_Ack 1;
BA_ "GenSigSNA" SG_ 1029 NM_Sleep_Ack "1h";
BA_ "FlexKomSigStartValue" SG_ 1029 NM_Sleep_Ind "FFFFFFFFh";
BA_ "GenSigStartValue" SG_ 1029 NM_Sleep_Ind 1;
BA_ "FlexKomSID" SG_ 1029 NM_Sleep_Ind 472;
BA_ "FlexKomSigStartPos" SG_ 1029 NM_Sleep_Ind 7;
BA_ "FlexKomSigLaenge" SG_ 1029 NM_Sleep_Ind 32;
BA_ "FlexKomSigName" SG_ 1029 NM_Sleep_Ind "NM";
BA_ "FlexKomComment" SG_ 1029 NM_Sleep_Ind "Network management state";
BA_ "FlexKomIsMotorola" SG_ 1029 NM_Sleep_Ind 1;
BA_ "GenSigSNA" SG_ 1029 NM_Sleep_Ind "1h";
BA_ "FlexKomSigStartValue" SG_ 1029 NM_Ud_Srv "FFFFFFFFh";
BA_ "GenSigStartValue" SG_ 1029 NM_Ud_Srv 255;
BA_ "FlexKomSID" SG_ 1029 NM_Ud_Srv 472;
BA_ "FlexKomSigStartPos" SG_ 1029 NM_Ud_Srv 7;
BA_ "FlexKomSigLaenge" SG_ 1029 NM_Ud_Srv 32;
BA_ "FlexKomSigName" SG_ 1029 NM_Ud_Srv "NM";
BA_ "FlexKomComment" SG_ 1029 NM_Ud_Srv "Network management state";
BA_ "FlexKomIsMotorola" SG_ 1029 NM_Ud_Srv 1;
BA_ "GenSigSNA" SG_ 1029 NM_Ud_Srv "FFh";
BA_ "FlexKomSigStartValue" SG_ 1029 Awake_NwSt "000000h";
BA_ "FlexKomSID" SG_ 1029 Awake_NwSt 1054;
BA_ "FlexKomSigStartPos" SG_ 1029 Awake_NwSt 39;
BA_ "FlexKomSigLaenge" SG_ 1029 Awake_NwSt 24;
BA_ "FlexKomSigName" SG_ 1029 Awake_NwSt "Awake_RBT_DR";
BA_ "FlexKomComment" SG_ 1029 Awake_NwSt "Mode 15 of NM_Ud_Srv";
BA_ "FlexKomIsMotorola" SG_ 1029 Awake_NwSt 1;
BA_ "GenSigSNA" SG_ 1029 Awake_NwSt "0h";
BA_ "FlexKomSigStartValue" SG_ 1029 WakeupRsn_RBT_DR "FFFF00h";
BA_ "GenSigStartValue" SG_ 1029 WakeupRsn_RBT_DR 255;
BA_ "FlexKomSID" SG_ 1029 WakeupRsn_RBT_DR 1056;
BA_ "FlexKomSigStartPos" SG_ 1029 WakeupRsn_RBT_DR 39;
BA_ "FlexKomSigLaenge" SG_ 1029 WakeupRsn_RBT_DR 24;
BA_ "FlexKomSigName" SG_ 1029 WakeupRsn_RBT_DR "Wakeup_RBT_DR";
BA_ "FlexKomComment" SG_ 1029 WakeupRsn_RBT_DR "Mode 2 of NM_Ud_Srv";
BA_ "FlexKomIsMotorola" SG_ 1029 WakeupRsn_RBT_DR 1;
BA_ "GenSigSNA" SG_ 1029 WakeupRsn_RBT_DR "FFh";
BA_ "FlexKomSigStartValue" SG_ 1029 Awake_Diag_Actv "000000h";
BA_ "FlexKomSID" SG_ 1029 Awake_Diag_Actv 1054;
BA_ "FlexKomSigStartPos" SG_ 1029 Awake_Diag_Actv 39;
BA_ "FlexKomSigLaenge" SG_ 1029 Awake_Diag_Actv 24;
BA_ "FlexKomSigName" SG_ 1029 Awake_Diag_Actv "Awake_RBT_DR";
BA_ "FlexKomComment" SG_ 1029 Awake_Diag_Actv "Mode 15 of NM_Ud_Srv";
BA_ "FlexKomIsMotorola" SG_ 1029 Awake_Diag_Actv 1;
BA_ "GenSigSNA" SG_ 1029 Awake_Diag_Actv "0h";
BA_ "FlexKomSigStartValue" SG_ 1029 WakeupCnt "FFFF00h";
BA_ "GenSigStartValue" SG_ 1029 WakeupCnt 255;
BA_ "FlexKomSID" SG_ 1029 WakeupCnt 1056;
BA_ "FlexKomSigStartPos" SG_ 1029 WakeupCnt 39;
BA_ "FlexKomSigLaenge" SG_ 1029 WakeupCnt 24;
BA_ "FlexKomSigName" SG_ 1029 WakeupCnt "Wakeup_RBT_DR";
BA_ "FlexKomComment" SG_ 1029 WakeupCnt "Mode 2 of NM_Ud_Srv";
BA_ "FlexKomIsMotorola" SG_ 1029 WakeupCnt 1;
BA_ "GenSigSNA" SG_ 1029 WakeupCnt "FFh";
BA_ "FlexKomSigStartValue" SG_ 1029 Nw_Id "FFh";
BA_ "GenSigStartValue" SG_ 1029 Nw_Id 255;
BA_ "FlexKomSID" SG_ 1029 Nw_Id 535;
BA_ "FlexKomSigStartPos" SG_ 1029 Nw_Id 63;
BA_ "FlexKomSigLaenge" SG_ 1029 Nw_Id 8;
BA_ "FlexKomSigName" SG_ 1029 Nw_Id "Nw_Id";
BA_ "FlexKomComment" SG_ 1029 Nw_Id "Network identification no.";
BA_ "FlexKomIsMotorola" SG_ 1029 Nw_Id 1;
BA_ "GenSigSNA" SG_ 1029 Nw_Id "FFh";
BA_ "FlexKomSigStartValue" SG_ 1030 NM_Mode "FFFFFFFFh";
BA_ "GenSigStartValue" SG_ 1030 NM_Mode 255;
BA_ "FlexKomSID" SG_ 1030 NM_Mode 472;
BA_ "FlexKomSigStartPos" SG_ 1030 NM_Mode 7;
BA_ "FlexKomSigLaenge" SG_ 1030 NM_Mode 32;
BA_ "FlexKomSigName" SG_ 1030 NM_Mode "NM";
BA_ "FlexKomComment" SG_ 1030 NM_Mode "Network management state";
BA_ "FlexKomIsMotorola" SG_ 1030 NM_Mode 1;
BA_ "GenSigSNA" SG_ 1030 NM_Mode "FFh";
BA_ "FlexKomSigStartValue" SG_ 1030 NM_Successor "FFFFFFFFh";
BA_ "GenSigStartValue" SG_ 1030 NM_Successor 255;
BA_ "FlexKomSID" SG_ 1030 NM_Successor 472;
BA_ "FlexKomSigStartPos" SG_ 1030 NM_Successor 7;
BA_ "FlexKomSigLaenge" SG_ 1030 NM_Successor 32;
BA_ "FlexKomSigName" SG_ 1030 NM_Successor "NM";
BA_ "FlexKomComment" SG_ 1030 NM_Successor "Network management state";
BA_ "FlexKomIsMotorola" SG_ 1030 NM_Successor 1;
BA_ "GenSigSNA" SG_ 1030 NM_Successor "FFh";
BA_ "FlexKomSigStartValue" SG_ 1030 NM_Ud_Launch "FFFFFFFFh";
BA_ "GenSigStartValue" SG_ 1030 NM_Ud_Launch 63;
BA_ "FlexKomSID" SG_ 1030 NM_Ud_Launch 472;
BA_ "FlexKomSigStartPos" SG_ 1030 NM_Ud_Launch 7;
BA_ "FlexKomSigLaenge" SG_ 1030 NM_Ud_Launch 32;
BA_ "FlexKomSigName" SG_ 1030 NM_Ud_Launch "NM";
BA_ "FlexKomComment" SG_ 1030 NM_Ud_Launch "Network management state";
BA_ "FlexKomIsMotorola" SG_ 1030 NM_Ud_Launch 1;
BA_ "GenSigSNA" SG_ 1030 NM_Ud_Launch "3Fh";
BA_ "FlexKomSigStartValue" SG_ 1030 NM_Sleep_Ack "FFFFFFFFh";
BA_ "GenSigStartValue" SG_ 1030 NM_Sleep_Ack 1;
BA_ "FlexKomSID" SG_ 1030 NM_Sleep_Ack 472;
BA_ "FlexKomSigStartPos" SG_ 1030 NM_Sleep_Ack 7;
BA_ "FlexKomSigLaenge" SG_ 1030 NM_Sleep_Ack 32;
BA_ "FlexKomSigName" SG_ 1030 NM_Sleep_Ack "NM";
BA_ "FlexKomComment" SG_ 1030 NM_Sleep_Ack "Network management state";
BA_ "FlexKomIsMotorola" SG_ 1030 NM_Sleep_Ack 1;
BA_ "GenSigSNA" SG_ 1030 NM_Sleep_Ack "1h";
BA_ "FlexKomSigStartValue" SG_ 1030 NM_Sleep_Ind "FFFFFFFFh";
BA_ "GenSigStartValue" SG_ 1030 NM_Sleep_Ind 1;
BA_ "FlexKomSID" SG_ 1030 NM_Sleep_Ind 472;
BA_ "FlexKomSigStartPos" SG_ 1030 NM_Sleep_Ind 7;
BA_ "FlexKomSigLaenge" SG_ 1030 NM_Sleep_Ind 32;
BA_ "FlexKomSigName" SG_ 1030 NM_Sleep_Ind "NM";
BA_ "FlexKomComment" SG_ 1030 NM_Sleep_Ind "Network management state";
BA_ "FlexKomIsMotorola" SG_ 1030 NM_Sleep_Ind 1;
BA_ "GenSigSNA" SG_ 1030 NM_Sleep_Ind "1h";
BA_ "FlexKomSigStartValue" SG_ 1030 NM_Ud_Srv "FFFFFFFFh";
BA_ "GenSigStartValue" SG_ 1030 NM_Ud_Srv 255;
BA_ "FlexKomSID" SG_ 1030 NM_Ud_Srv 472;
BA_ "FlexKomSigStartPos" SG_ 1030 NM_Ud_Srv 7;
BA_ "FlexKomSigLaenge" SG_ 1030 NM_Ud_Srv 32;
BA_ "FlexKomSigName" SG_ 1030 NM_Ud_Srv "NM";
BA_ "FlexKomComment" SG_ 1030 NM_Ud_Srv "Network management state";
BA_ "FlexKomIsMotorola" SG_ 1030 NM_Ud_Srv 1;
BA_ "GenSigSNA" SG_ 1030 NM_Ud_Srv "FFh";
BA_ "FlexKomSigStartValue" SG_ 1030 Awake_NwSt "000000h";
BA_ "FlexKomSID" SG_ 1030 Awake_NwSt 1055;
BA_ "FlexKomSigStartPos" SG_ 1030 Awake_NwSt 39;
BA_ "FlexKomSigLaenge" SG_ 1030 Awake_NwSt 24;
BA_ "FlexKomSigName" SG_ 1030 Awake_NwSt "Awake_RBT_PASS";
BA_ "FlexKomComment" SG_ 1030 Awake_NwSt "Mode 15 of NM_Ud_Srv";
BA_ "FlexKomIsMotorola" SG_ 1030 Awake_NwSt 1;
BA_ "GenSigSNA" SG_ 1030 Awake_NwSt "0h";
BA_ "FlexKomSigStartValue" SG_ 1030 WakeupRsn_RBT_PASS "FFFF00h";
BA_ "GenSigStartValue" SG_ 1030 WakeupRsn_RBT_PASS 255;
BA_ "FlexKomSID" SG_ 1030 WakeupRsn_RBT_PASS 1057;
BA_ "FlexKomSigStartPos" SG_ 1030 WakeupRsn_RBT_PASS 39;
BA_ "FlexKomSigLaenge" SG_ 1030 WakeupRsn_RBT_PASS 24;
BA_ "FlexKomSigName" SG_ 1030 WakeupRsn_RBT_PASS "Wakeup_RBT_PASS";
BA_ "FlexKomComment" SG_ 1030 WakeupRsn_RBT_PASS "Mode 2 of NM_Ud_Srv";
BA_ "FlexKomIsMotorola" SG_ 1030 WakeupRsn_RBT_PASS 1;
BA_ "GenSigSNA" SG_ 1030 WakeupRsn_RBT_PASS "FFh";
BA_ "FlexKomSigStartValue" SG_ 1030 Awake_Diag_Actv "000000h";
BA_ "FlexKomSID" SG_ 1030 Awake_Diag_Actv 1055;
BA_ "FlexKomSigStartPos" SG_ 1030 Awake_Diag_Actv 39;
BA_ "FlexKomSigLaenge" SG_ 1030 Awake_Diag_Actv 24;
BA_ "FlexKomSigName" SG_ 1030 Awake_Diag_Actv "Awake_RBT_PASS";
BA_ "FlexKomComment" SG_ 1030 Awake_Diag_Actv "Mode 15 of NM_Ud_Srv";
BA_ "FlexKomIsMotorola" SG_ 1030 Awake_Diag_Actv 1;
BA_ "GenSigSNA" SG_ 1030 Awake_Diag_Actv "0h";
BA_ "FlexKomSigStartValue" SG_ 1030 WakeupCnt "FFFF00h";
BA_ "GenSigStartValue" SG_ 1030 WakeupCnt 255;
BA_ "FlexKomSID" SG_ 1030 WakeupCnt 1057;
BA_ "FlexKomSigStartPos" SG_ 1030 WakeupCnt 39;
BA_ "FlexKomSigLaenge" SG_ 1030 WakeupCnt 24;
BA_ "FlexKomSigName" SG_ 1030 WakeupCnt "Wakeup_RBT_PASS";
BA_ "FlexKomComment" SG_ 1030 WakeupCnt "Mode 2 of NM_Ud_Srv";
BA_ "FlexKomIsMotorola" SG_ 1030 WakeupCnt 1;
BA_ "GenSigSNA" SG_ 1030 WakeupCnt "FFh";
BA_ "FlexKomSigStartValue" SG_ 1030 Nw_Id "FFh";
BA_ "GenSigStartValue" SG_ 1030 Nw_Id 255;
BA_ "FlexKomSID" SG_ 1030 Nw_Id 535;
BA_ "FlexKomSigStartPos" SG_ 1030 Nw_Id 63;
BA_ "FlexKomSigLaenge" SG_ 1030 Nw_Id 8;
BA_ "FlexKomSigName" SG_ 1030 Nw_Id "Nw_Id";
BA_ "FlexKomComment" SG_ 1030 Nw_Id "Network identification no.";
BA_ "FlexKomIsMotorola" SG_ 1030 Nw_Id 1;
BA_ "GenSigSNA" SG_ 1030 Nw_Id "FFh";
BA_ "FlexKomSigStartValue" SG_ 1031 NM_Mode "FFFFFFFFh";
BA_ "GenSigStartValue" SG_ 1031 NM_Mode 255;
BA_ "FlexKomSID" SG_ 1031 NM_Mode 472;
BA_ "FlexKomSigStartPos" SG_ 1031 NM_Mode 7;
BA_ "FlexKomSigLaenge" SG_ 1031 NM_Mode 32;
BA_ "FlexKomSigName" SG_ 1031 NM_Mode "NM";
BA_ "FlexKomComment" SG_ 1031 NM_Mode "Network management state";
BA_ "FlexKomIsMotorola" SG_ 1031 NM_Mode 1;
BA_ "GenSigSNA" SG_ 1031 NM_Mode "FFh";
BA_ "FlexKomSigStartValue" SG_ 1031 NM_Successor "FFFFFFFFh";
BA_ "GenSigStartValue" SG_ 1031 NM_Successor 255;
BA_ "FlexKomSID" SG_ 1031 NM_Successor 472;
BA_ "FlexKomSigStartPos" SG_ 1031 NM_Successor 7;
BA_ "FlexKomSigLaenge" SG_ 1031 NM_Successor 32;
BA_ "FlexKomSigName" SG_ 1031 NM_Successor "NM";
BA_ "FlexKomComment" SG_ 1031 NM_Successor "Network management state";
BA_ "FlexKomIsMotorola" SG_ 1031 NM_Successor 1;
BA_ "GenSigSNA" SG_ 1031 NM_Successor "FFh";
BA_ "FlexKomSigStartValue" SG_ 1031 NM_Ud_Launch "FFFFFFFFh";
BA_ "GenSigStartValue" SG_ 1031 NM_Ud_Launch 63;
BA_ "FlexKomSID" SG_ 1031 NM_Ud_Launch 472;
BA_ "FlexKomSigStartPos" SG_ 1031 NM_Ud_Launch 7;
BA_ "FlexKomSigLaenge" SG_ 1031 NM_Ud_Launch 32;
BA_ "FlexKomSigName" SG_ 1031 NM_Ud_Launch "NM";
BA_ "FlexKomComment" SG_ 1031 NM_Ud_Launch "Network management state";
BA_ "FlexKomIsMotorola" SG_ 1031 NM_Ud_Launch 1;
BA_ "GenSigSNA" SG_ 1031 NM_Ud_Launch "3Fh";
BA_ "FlexKomSigStartValue" SG_ 1031 NM_Sleep_Ack "FFFFFFFFh";
BA_ "GenSigStartValue" SG_ 1031 NM_Sleep_Ack 1;
BA_ "FlexKomSID" SG_ 1031 NM_Sleep_Ack 472;
BA_ "FlexKomSigStartPos" SG_ 1031 NM_Sleep_Ack 7;
BA_ "FlexKomSigLaenge" SG_ 1031 NM_Sleep_Ack 32;
BA_ "FlexKomSigName" SG_ 1031 NM_Sleep_Ack "NM";
BA_ "FlexKomComment" SG_ 1031 NM_Sleep_Ack "Network management state";
BA_ "FlexKomIsMotorola" SG_ 1031 NM_Sleep_Ack 1;
BA_ "GenSigSNA" SG_ 1031 NM_Sleep_Ack "1h";
BA_ "FlexKomSigStartValue" SG_ 1031 NM_Sleep_Ind "FFFFFFFFh";
BA_ "GenSigStartValue" SG_ 1031 NM_Sleep_Ind 1;
BA_ "FlexKomSID" SG_ 1031 NM_Sleep_Ind 472;
BA_ "FlexKomSigStartPos" SG_ 1031 NM_Sleep_Ind 7;
BA_ "FlexKomSigLaenge" SG_ 1031 NM_Sleep_Ind 32;
BA_ "FlexKomSigName" SG_ 1031 NM_Sleep_Ind "NM";
BA_ "FlexKomComment" SG_ 1031 NM_Sleep_Ind "Network management state";
BA_ "FlexKomIsMotorola" SG_ 1031 NM_Sleep_Ind 1;
BA_ "GenSigSNA" SG_ 1031 NM_Sleep_Ind "1h";
BA_ "FlexKomSigStartValue" SG_ 1031 NM_Ud_Srv "FFFFFFFFh";
BA_ "GenSigStartValue" SG_ 1031 NM_Ud_Srv 255;
BA_ "FlexKomSID" SG_ 1031 NM_Ud_Srv 472;
BA_ "FlexKomSigStartPos" SG_ 1031 NM_Ud_Srv 7;
BA_ "FlexKomSigLaenge" SG_ 1031 NM_Ud_Srv 32;
BA_ "FlexKomSigName" SG_ 1031 NM_Ud_Srv "NM";
BA_ "FlexKomComment" SG_ 1031 NM_Ud_Srv "Network management state";
BA_ "FlexKomIsMotorola" SG_ 1031 NM_Ud_Srv 1;
BA_ "GenSigSNA" SG_ 1031 NM_Ud_Srv "FFh";
BA_ "FlexKomSigStartValue" SG_ 1031 Awake_NwSt "000000h";
BA_ "FlexKomSID" SG_ 1031 Awake_NwSt 961;
BA_ "FlexKomSigStartPos" SG_ 1031 Awake_NwSt 39;
BA_ "FlexKomSigLaenge" SG_ 1031 Awake_NwSt 24;
BA_ "FlexKomSigName" SG_ 1031 Awake_NwSt "Awake_ESC";
BA_ "FlexKomComment" SG_ 1031 Awake_NwSt "Mode 15 of NM_Ud_Srv";
BA_ "FlexKomIsMotorola" SG_ 1031 Awake_NwSt 1;
BA_ "GenSigSNA" SG_ 1031 Awake_NwSt "0h";
BA_ "FlexKomSigStartValue" SG_ 1031 WakeupRsn_ESC "FFFF00h";
BA_ "GenSigStartValue" SG_ 1031 WakeupRsn_ESC 255;
BA_ "FlexKomSID" SG_ 1031 WakeupRsn_ESC 962;
BA_ "FlexKomSigStartPos" SG_ 1031 WakeupRsn_ESC 39;
BA_ "FlexKomSigLaenge" SG_ 1031 WakeupRsn_ESC 24;
BA_ "FlexKomSigName" SG_ 1031 WakeupRsn_ESC "Wakeup_ESC";
BA_ "FlexKomComment" SG_ 1031 WakeupRsn_ESC "Mode 2 of NM_Ud_Srv";
BA_ "FlexKomIsMotorola" SG_ 1031 WakeupRsn_ESC 1;
BA_ "GenSigSNA" SG_ 1031 WakeupRsn_ESC "FFh";
BA_ "FlexKomSigStartValue" SG_ 1031 Awake_Diag_Actv "000000h";
BA_ "FlexKomSID" SG_ 1031 Awake_Diag_Actv 961;
BA_ "FlexKomSigStartPos" SG_ 1031 Awake_Diag_Actv 39;
BA_ "FlexKomSigLaenge" SG_ 1031 Awake_Diag_Actv 24;
BA_ "FlexKomSigName" SG_ 1031 Awake_Diag_Actv "Awake_ESC";
BA_ "FlexKomComment" SG_ 1031 Awake_Diag_Actv "Mode 15 of NM_Ud_Srv";
BA_ "FlexKomIsMotorola" SG_ 1031 Awake_Diag_Actv 1;
BA_ "GenSigSNA" SG_ 1031 Awake_Diag_Actv "0h";
BA_ "FlexKomSigStartValue" SG_ 1031 WakeupCnt "FFFF00h";
BA_ "GenSigStartValue" SG_ 1031 WakeupCnt 255;
BA_ "FlexKomSID" SG_ 1031 WakeupCnt 962;
BA_ "FlexKomSigStartPos" SG_ 1031 WakeupCnt 39;
BA_ "FlexKomSigLaenge" SG_ 1031 WakeupCnt 24;
BA_ "FlexKomSigName" SG_ 1031 WakeupCnt "Wakeup_ESC";
BA_ "FlexKomComment" SG_ 1031 WakeupCnt "Mode 2 of NM_Ud_Srv";
BA_ "FlexKomIsMotorola" SG_ 1031 WakeupCnt 1;
BA_ "GenSigSNA" SG_ 1031 WakeupCnt "FFh";
BA_ "FlexKomSigStartValue" SG_ 1031 Nw_Id "FFh";
BA_ "GenSigStartValue" SG_ 1031 Nw_Id 255;
BA_ "FlexKomSID" SG_ 1031 Nw_Id 535;
BA_ "FlexKomSigStartPos" SG_ 1031 Nw_Id 63;
BA_ "FlexKomSigLaenge" SG_ 1031 Nw_Id 8;
BA_ "FlexKomSigName" SG_ 1031 Nw_Id "Nw_Id";
BA_ "FlexKomComment" SG_ 1031 Nw_Id "Network identification no.";
BA_ "FlexKomIsMotorola" SG_ 1031 Nw_Id 1;
BA_ "GenSigSNA" SG_ 1031 Nw_Id "FFh";
BA_ "FlexKomSigStartValue" SG_ 1033 NM_Mode "FFFFFFFFh";
BA_ "GenSigStartValue" SG_ 1033 NM_Mode 255;
BA_ "FlexKomSID" SG_ 1033 NM_Mode 472;
BA_ "FlexKomSigStartPos" SG_ 1033 NM_Mode 7;
BA_ "FlexKomSigLaenge" SG_ 1033 NM_Mode 32;
BA_ "FlexKomSigName" SG_ 1033 NM_Mode "NM";
BA_ "FlexKomComment" SG_ 1033 NM_Mode "Network management state";
BA_ "FlexKomIsMotorola" SG_ 1033 NM_Mode 1;
BA_ "GenSigSNA" SG_ 1033 NM_Mode "FFh";
BA_ "FlexKomSigStartValue" SG_ 1033 NM_Successor "FFFFFFFFh";
BA_ "GenSigStartValue" SG_ 1033 NM_Successor 255;
BA_ "FlexKomSID" SG_ 1033 NM_Successor 472;
BA_ "FlexKomSigStartPos" SG_ 1033 NM_Successor 7;
BA_ "FlexKomSigLaenge" SG_ 1033 NM_Successor 32;
BA_ "FlexKomSigName" SG_ 1033 NM_Successor "NM";
BA_ "FlexKomComment" SG_ 1033 NM_Successor "Network management state";
BA_ "FlexKomIsMotorola" SG_ 1033 NM_Successor 1;
BA_ "GenSigSNA" SG_ 1033 NM_Successor "FFh";
BA_ "FlexKomSigStartValue" SG_ 1033 NM_Ud_Launch "FFFFFFFFh";
BA_ "GenSigStartValue" SG_ 1033 NM_Ud_Launch 63;
BA_ "FlexKomSID" SG_ 1033 NM_Ud_Launch 472;
BA_ "FlexKomSigStartPos" SG_ 1033 NM_Ud_Launch 7;
BA_ "FlexKomSigLaenge" SG_ 1033 NM_Ud_Launch 32;
BA_ "FlexKomSigName" SG_ 1033 NM_Ud_Launch "NM";
BA_ "FlexKomComment" SG_ 1033 NM_Ud_Launch "Network management state";
BA_ "FlexKomIsMotorola" SG_ 1033 NM_Ud_Launch 1;
BA_ "GenSigSNA" SG_ 1033 NM_Ud_Launch "3Fh";
BA_ "FlexKomSigStartValue" SG_ 1033 NM_Sleep_Ack "FFFFFFFFh";
BA_ "GenSigStartValue" SG_ 1033 NM_Sleep_Ack 1;
BA_ "FlexKomSID" SG_ 1033 NM_Sleep_Ack 472;
BA_ "FlexKomSigStartPos" SG_ 1033 NM_Sleep_Ack 7;
BA_ "FlexKomSigLaenge" SG_ 1033 NM_Sleep_Ack 32;
BA_ "FlexKomSigName" SG_ 1033 NM_Sleep_Ack "NM";
BA_ "FlexKomComment" SG_ 1033 NM_Sleep_Ack "Network management state";
BA_ "FlexKomIsMotorola" SG_ 1033 NM_Sleep_Ack 1;
BA_ "GenSigSNA" SG_ 1033 NM_Sleep_Ack "1h";
BA_ "FlexKomSigStartValue" SG_ 1033 NM_Sleep_Ind "FFFFFFFFh";
BA_ "GenSigStartValue" SG_ 1033 NM_Sleep_Ind 1;
BA_ "FlexKomSID" SG_ 1033 NM_Sleep_Ind 472;
BA_ "FlexKomSigStartPos" SG_ 1033 NM_Sleep_Ind 7;
BA_ "FlexKomSigLaenge" SG_ 1033 NM_Sleep_Ind 32;
BA_ "FlexKomSigName" SG_ 1033 NM_Sleep_Ind "NM";
BA_ "FlexKomComment" SG_ 1033 NM_Sleep_Ind "Network management state";
BA_ "FlexKomIsMotorola" SG_ 1033 NM_Sleep_Ind 1;
BA_ "GenSigSNA" SG_ 1033 NM_Sleep_Ind "1h";
BA_ "FlexKomSigStartValue" SG_ 1033 NM_Ud_Srv "FFFFFFFFh";
BA_ "GenSigStartValue" SG_ 1033 NM_Ud_Srv 255;
BA_ "FlexKomSID" SG_ 1033 NM_Ud_Srv 472;
BA_ "FlexKomSigStartPos" SG_ 1033 NM_Ud_Srv 7;
BA_ "FlexKomSigLaenge" SG_ 1033 NM_Ud_Srv 32;
BA_ "FlexKomSigName" SG_ 1033 NM_Ud_Srv "NM";
BA_ "FlexKomComment" SG_ 1033 NM_Ud_Srv "Network management state";
BA_ "FlexKomIsMotorola" SG_ 1033 NM_Ud_Srv 1;
BA_ "GenSigSNA" SG_ 1033 NM_Ud_Srv "FFh";
BA_ "FlexKomSigStartValue" SG_ 1033 Awake_NwSt "000000h";
BA_ "FlexKomSID" SG_ 1033 Awake_NwSt 1370;
BA_ "FlexKomSigStartPos" SG_ 1033 Awake_NwSt 39;
BA_ "FlexKomSigLaenge" SG_ 1033 Awake_NwSt 24;
BA_ "FlexKomSigName" SG_ 1033 Awake_NwSt "Awake_SBWM";
BA_ "FlexKomComment" SG_ 1033 Awake_NwSt "Mode 15 of NM_Ud_Srv";
BA_ "FlexKomIsMotorola" SG_ 1033 Awake_NwSt 1;
BA_ "GenSigSNA" SG_ 1033 Awake_NwSt "0h";
BA_ "FlexKomSigStartValue" SG_ 1033 WakeupRsn_SBWM "FFFF00h";
BA_ "GenSigStartValue" SG_ 1033 WakeupRsn_SBWM 255;
BA_ "FlexKomSID" SG_ 1033 WakeupRsn_SBWM 1371;
BA_ "FlexKomSigStartPos" SG_ 1033 WakeupRsn_SBWM 39;
BA_ "FlexKomSigLaenge" SG_ 1033 WakeupRsn_SBWM 24;
BA_ "FlexKomSigName" SG_ 1033 WakeupRsn_SBWM "Wakeup_SBWM";
BA_ "FlexKomComment" SG_ 1033 WakeupRsn_SBWM "Mode 2 of NM_Ud_Srv";
BA_ "FlexKomIsMotorola" SG_ 1033 WakeupRsn_SBWM 1;
BA_ "GenSigSNA" SG_ 1033 WakeupRsn_SBWM "FFh";
BA_ "FlexKomSigStartValue" SG_ 1033 Awake_Diag_Actv "000000h";
BA_ "FlexKomSID" SG_ 1033 Awake_Diag_Actv 1370;
BA_ "FlexKomSigStartPos" SG_ 1033 Awake_Diag_Actv 39;
BA_ "FlexKomSigLaenge" SG_ 1033 Awake_Diag_Actv 24;
BA_ "FlexKomSigName" SG_ 1033 Awake_Diag_Actv "Awake_SBWM";
BA_ "FlexKomComment" SG_ 1033 Awake_Diag_Actv "Mode 15 of NM_Ud_Srv";
BA_ "FlexKomIsMotorola" SG_ 1033 Awake_Diag_Actv 1;
BA_ "GenSigSNA" SG_ 1033 Awake_Diag_Actv "0h";
BA_ "FlexKomSigStartValue" SG_ 1033 Awake_Ignition_On "000000h";
BA_ "FlexKomSID" SG_ 1033 Awake_Ignition_On 1370;
BA_ "FlexKomSigStartPos" SG_ 1033 Awake_Ignition_On 39;
BA_ "FlexKomSigLaenge" SG_ 1033 Awake_Ignition_On 24;
BA_ "FlexKomSigName" SG_ 1033 Awake_Ignition_On "Awake_SBWM";
BA_ "FlexKomComment" SG_ 1033 Awake_Ignition_On "Mode 15 of NM_Ud_Srv";
BA_ "FlexKomIsMotorola" SG_ 1033 Awake_Ignition_On 1;
BA_ "GenSigSNA" SG_ 1033 Awake_Ignition_On "0h";
BA_ "FlexKomSigStartValue" SG_ 1033 Awake_EEPROM "000000h";
BA_ "FlexKomSID" SG_ 1033 Awake_EEPROM 1370;
BA_ "FlexKomSigStartPos" SG_ 1033 Awake_EEPROM 39;
BA_ "FlexKomSigLaenge" SG_ 1033 Awake_EEPROM 24;
BA_ "FlexKomSigName" SG_ 1033 Awake_EEPROM "Awake_SBWM";
BA_ "FlexKomComment" SG_ 1033 Awake_EEPROM "Mode 15 of NM_Ud_Srv";
BA_ "FlexKomIsMotorola" SG_ 1033 Awake_EEPROM 1;
BA_ "GenSigSNA" SG_ 1033 Awake_EEPROM "0h";
BA_ "FlexKomSigStartValue" SG_ 1033 Awake_URS "000000h";
BA_ "FlexKomSID" SG_ 1033 Awake_URS 1370;
BA_ "FlexKomSigStartPos" SG_ 1033 Awake_URS 39;
BA_ "FlexKomSigLaenge" SG_ 1033 Awake_URS 24;
BA_ "FlexKomSigName" SG_ 1033 Awake_URS "Awake_SBWM";
BA_ "FlexKomComment" SG_ 1033 Awake_URS "Mode 15 of NM_Ud_Srv";
BA_ "FlexKomIsMotorola" SG_ 1033 Awake_URS 1;
BA_ "GenSigSNA" SG_ 1033 Awake_URS "0h";
BA_ "FlexKomSigStartValue" SG_ 1033 WakeupCnt "FFFF00h";
BA_ "GenSigStartValue" SG_ 1033 WakeupCnt 255;
BA_ "FlexKomSID" SG_ 1033 WakeupCnt 1371;
BA_ "FlexKomSigStartPos" SG_ 1033 WakeupCnt 39;
BA_ "FlexKomSigLaenge" SG_ 1033 WakeupCnt 24;
BA_ "FlexKomSigName" SG_ 1033 WakeupCnt "Wakeup_SBWM";
BA_ "FlexKomComment" SG_ 1033 WakeupCnt "Mode 2 of NM_Ud_Srv";
BA_ "FlexKomIsMotorola" SG_ 1033 WakeupCnt 1;
BA_ "GenSigSNA" SG_ 1033 WakeupCnt "FFh";
BA_ "FlexKomSigStartValue" SG_ 1033 Nw_Id "FFh";
BA_ "GenSigStartValue" SG_ 1033 Nw_Id 255;
BA_ "FlexKomSID" SG_ 1033 Nw_Id 535;
BA_ "FlexKomSigStartPos" SG_ 1033 Nw_Id 63;
BA_ "FlexKomSigLaenge" SG_ 1033 Nw_Id 8;
BA_ "FlexKomSigName" SG_ 1033 Nw_Id "Nw_Id";
BA_ "FlexKomComment" SG_ 1033 Nw_Id "Network identification no.";
BA_ "FlexKomIsMotorola" SG_ 1033 Nw_Id 1;
BA_ "GenSigSNA" SG_ 1033 Nw_Id "FFh";
BA_ "FlexKomSigStartValue" SG_ 1044 NM_Mode "FFFFFFFFh";
BA_ "GenSigStartValue" SG_ 1044 NM_Mode 255;
BA_ "FlexKomSID" SG_ 1044 NM_Mode 472;
BA_ "FlexKomSigStartPos" SG_ 1044 NM_Mode 7;
BA_ "FlexKomSigLaenge" SG_ 1044 NM_Mode 32;
BA_ "FlexKomSigName" SG_ 1044 NM_Mode "NM";
BA_ "FlexKomComment" SG_ 1044 NM_Mode "Network management state";
BA_ "FlexKomIsMotorola" SG_ 1044 NM_Mode 1;
BA_ "GenSigSNA" SG_ 1044 NM_Mode "FFh";
BA_ "FlexKomSigStartValue" SG_ 1044 NM_Successor "FFFFFFFFh";
BA_ "GenSigStartValue" SG_ 1044 NM_Successor 255;
BA_ "FlexKomSID" SG_ 1044 NM_Successor 472;
BA_ "FlexKomSigStartPos" SG_ 1044 NM_Successor 7;
BA_ "FlexKomSigLaenge" SG_ 1044 NM_Successor 32;
BA_ "FlexKomSigName" SG_ 1044 NM_Successor "NM";
BA_ "FlexKomComment" SG_ 1044 NM_Successor "Network management state";
BA_ "FlexKomIsMotorola" SG_ 1044 NM_Successor 1;
BA_ "GenSigSNA" SG_ 1044 NM_Successor "FFh";
BA_ "FlexKomSigStartValue" SG_ 1044 NM_Ud_Launch "FFFFFFFFh";
BA_ "GenSigStartValue" SG_ 1044 NM_Ud_Launch 63;
BA_ "FlexKomSID" SG_ 1044 NM_Ud_Launch 472;
BA_ "FlexKomSigStartPos" SG_ 1044 NM_Ud_Launch 7;
BA_ "FlexKomSigLaenge" SG_ 1044 NM_Ud_Launch 32;
BA_ "FlexKomSigName" SG_ 1044 NM_Ud_Launch "NM";
BA_ "FlexKomComment" SG_ 1044 NM_Ud_Launch "Network management state";
BA_ "FlexKomIsMotorola" SG_ 1044 NM_Ud_Launch 1;
BA_ "GenSigSNA" SG_ 1044 NM_Ud_Launch "3Fh";
BA_ "FlexKomSigStartValue" SG_ 1044 NM_Sleep_Ack "FFFFFFFFh";
BA_ "GenSigStartValue" SG_ 1044 NM_Sleep_Ack 1;
BA_ "FlexKomSID" SG_ 1044 NM_Sleep_Ack 472;
BA_ "FlexKomSigStartPos" SG_ 1044 NM_Sleep_Ack 7;
BA_ "FlexKomSigLaenge" SG_ 1044 NM_Sleep_Ack 32;
BA_ "FlexKomSigName" SG_ 1044 NM_Sleep_Ack "NM";
BA_ "FlexKomComment" SG_ 1044 NM_Sleep_Ack "Network management state";
BA_ "FlexKomIsMotorola" SG_ 1044 NM_Sleep_Ack 1;
BA_ "GenSigSNA" SG_ 1044 NM_Sleep_Ack "1h";
BA_ "FlexKomSigStartValue" SG_ 1044 NM_Sleep_Ind "FFFFFFFFh";
BA_ "GenSigStartValue" SG_ 1044 NM_Sleep_Ind 1;
BA_ "FlexKomSID" SG_ 1044 NM_Sleep_Ind 472;
BA_ "FlexKomSigStartPos" SG_ 1044 NM_Sleep_Ind 7;
BA_ "FlexKomSigLaenge" SG_ 1044 NM_Sleep_Ind 32;
BA_ "FlexKomSigName" SG_ 1044 NM_Sleep_Ind "NM";
BA_ "FlexKomComment" SG_ 1044 NM_Sleep_Ind "Network management state";
BA_ "FlexKomIsMotorola" SG_ 1044 NM_Sleep_Ind 1;
BA_ "GenSigSNA" SG_ 1044 NM_Sleep_Ind "1h";
BA_ "FlexKomSigStartValue" SG_ 1044 NM_Ud_Srv "FFFFFFFFh";
BA_ "GenSigStartValue" SG_ 1044 NM_Ud_Srv 255;
BA_ "FlexKomSID" SG_ 1044 NM_Ud_Srv 472;
BA_ "FlexKomSigStartPos" SG_ 1044 NM_Ud_Srv 7;
BA_ "FlexKomSigLaenge" SG_ 1044 NM_Ud_Srv 32;
BA_ "FlexKomSigName" SG_ 1044 NM_Ud_Srv "NM";
BA_ "FlexKomComment" SG_ 1044 NM_Ud_Srv "Network management state";
BA_ "FlexKomIsMotorola" SG_ 1044 NM_Ud_Srv 1;
BA_ "GenSigSNA" SG_ 1044 NM_Ud_Srv "FFh";
BA_ "FlexKomSigStartValue" SG_ 1044 Awake_NwSt "000000h";
BA_ "FlexKomSID" SG_ 1044 Awake_NwSt 1485;
BA_ "FlexKomSigStartPos" SG_ 1044 Awake_NwSt 39;
BA_ "FlexKomSigLaenge" SG_ 1044 Awake_NwSt 24;
BA_ "FlexKomSigName" SG_ 1044 Awake_NwSt "Awake_ITBM";
BA_ "FlexKomComment" SG_ 1044 Awake_NwSt "Mode 15 of NM_Ud_Srv";
BA_ "FlexKomIsMotorola" SG_ 1044 Awake_NwSt 1;
BA_ "GenSigSNA" SG_ 1044 Awake_NwSt "0h";
BA_ "FlexKomSigStartValue" SG_ 1044 WakeupRsn_ITBM "FFFF00h";
BA_ "GenSigStartValue" SG_ 1044 WakeupRsn_ITBM 255;
BA_ "FlexKomSID" SG_ 1044 WakeupRsn_ITBM 1486;
BA_ "FlexKomSigStartPos" SG_ 1044 WakeupRsn_ITBM 39;
BA_ "FlexKomSigLaenge" SG_ 1044 WakeupRsn_ITBM 24;
BA_ "FlexKomSigName" SG_ 1044 WakeupRsn_ITBM "Wakeup_ITBM";
BA_ "FlexKomComment" SG_ 1044 WakeupRsn_ITBM "Mode 2 of NM_Ud_Srv";
BA_ "FlexKomIsMotorola" SG_ 1044 WakeupRsn_ITBM 1;
BA_ "GenSigSNA" SG_ 1044 WakeupRsn_ITBM "FFh";
BA_ "FlexKomSigStartValue" SG_ 1044 Awake_Diag_Actv "000000h";
BA_ "FlexKomSID" SG_ 1044 Awake_Diag_Actv 1485;
BA_ "FlexKomSigStartPos" SG_ 1044 Awake_Diag_Actv 39;
BA_ "FlexKomSigLaenge" SG_ 1044 Awake_Diag_Actv 24;
BA_ "FlexKomSigName" SG_ 1044 Awake_Diag_Actv "Awake_ITBM";
BA_ "FlexKomComment" SG_ 1044 Awake_Diag_Actv "Mode 15 of NM_Ud_Srv";
BA_ "FlexKomIsMotorola" SG_ 1044 Awake_Diag_Actv 1;
BA_ "GenSigSNA" SG_ 1044 Awake_Diag_Actv "0h";
BA_ "FlexKomSigStartValue" SG_ 1044 WakeupCnt "FFFF00h";
BA_ "GenSigStartValue" SG_ 1044 WakeupCnt 255;
BA_ "FlexKomSID" SG_ 1044 WakeupCnt 1486;
BA_ "FlexKomSigStartPos" SG_ 1044 WakeupCnt 39;
BA_ "FlexKomSigLaenge" SG_ 1044 WakeupCnt 24;
BA_ "FlexKomSigName" SG_ 1044 WakeupCnt "Wakeup_ITBM";
BA_ "FlexKomComment" SG_ 1044 WakeupCnt "Mode 2 of NM_Ud_Srv";
BA_ "FlexKomIsMotorola" SG_ 1044 WakeupCnt 1;
BA_ "GenSigSNA" SG_ 1044 WakeupCnt "FFh";
BA_ "FlexKomSigStartValue" SG_ 1044 Nw_Id "FFh";
BA_ "GenSigStartValue" SG_ 1044 Nw_Id 255;
BA_ "FlexKomSID" SG_ 1044 Nw_Id 535;
BA_ "FlexKomSigStartPos" SG_ 1044 Nw_Id 63;
BA_ "FlexKomSigLaenge" SG_ 1044 Nw_Id 8;
BA_ "FlexKomSigName" SG_ 1044 Nw_Id "Nw_Id";
BA_ "FlexKomComment" SG_ 1044 Nw_Id "Network identification no.";
BA_ "FlexKomIsMotorola" SG_ 1044 Nw_Id 1;
BA_ "GenSigSNA" SG_ 1044 Nw_Id "FFh";
BA_ "FlexKomSigStartValue" SG_ 1049 NM_Mode "FFFFFFFFh";
BA_ "GenSigStartValue" SG_ 1049 NM_Mode 255;
BA_ "FlexKomSID" SG_ 1049 NM_Mode 472;
BA_ "FlexKomSigStartPos" SG_ 1049 NM_Mode 7;
BA_ "FlexKomSigLaenge" SG_ 1049 NM_Mode 32;
BA_ "FlexKomSigName" SG_ 1049 NM_Mode "NM";
BA_ "FlexKomComment" SG_ 1049 NM_Mode "Network management state";
BA_ "FlexKomIsMotorola" SG_ 1049 NM_Mode 1;
BA_ "GenSigSNA" SG_ 1049 NM_Mode "FFh";
BA_ "FlexKomSigStartValue" SG_ 1049 NM_Successor "FFFFFFFFh";
BA_ "GenSigStartValue" SG_ 1049 NM_Successor 255;
BA_ "FlexKomSID" SG_ 1049 NM_Successor 472;
BA_ "FlexKomSigStartPos" SG_ 1049 NM_Successor 7;
BA_ "FlexKomSigLaenge" SG_ 1049 NM_Successor 32;
BA_ "FlexKomSigName" SG_ 1049 NM_Successor "NM";
BA_ "FlexKomComment" SG_ 1049 NM_Successor "Network management state";
BA_ "FlexKomIsMotorola" SG_ 1049 NM_Successor 1;
BA_ "GenSigSNA" SG_ 1049 NM_Successor "FFh";
BA_ "FlexKomSigStartValue" SG_ 1049 NM_Ud_Launch "FFFFFFFFh";
BA_ "GenSigStartValue" SG_ 1049 NM_Ud_Launch 63;
BA_ "FlexKomSID" SG_ 1049 NM_Ud_Launch 472;
BA_ "FlexKomSigStartPos" SG_ 1049 NM_Ud_Launch 7;
BA_ "FlexKomSigLaenge" SG_ 1049 NM_Ud_Launch 32;
BA_ "FlexKomSigName" SG_ 1049 NM_Ud_Launch "NM";
BA_ "FlexKomComment" SG_ 1049 NM_Ud_Launch "Network management state";
BA_ "FlexKomIsMotorola" SG_ 1049 NM_Ud_Launch 1;
BA_ "GenSigSNA" SG_ 1049 NM_Ud_Launch "3Fh";
BA_ "FlexKomSigStartValue" SG_ 1049 NM_Sleep_Ack "FFFFFFFFh";
BA_ "GenSigStartValue" SG_ 1049 NM_Sleep_Ack 1;
BA_ "FlexKomSID" SG_ 1049 NM_Sleep_Ack 472;
BA_ "FlexKomSigStartPos" SG_ 1049 NM_Sleep_Ack 7;
BA_ "FlexKomSigLaenge" SG_ 1049 NM_Sleep_Ack 32;
BA_ "FlexKomSigName" SG_ 1049 NM_Sleep_Ack "NM";
BA_ "FlexKomComment" SG_ 1049 NM_Sleep_Ack "Network management state";
BA_ "FlexKomIsMotorola" SG_ 1049 NM_Sleep_Ack 1;
BA_ "GenSigSNA" SG_ 1049 NM_Sleep_Ack "1h";
BA_ "FlexKomSigStartValue" SG_ 1049 NM_Sleep_Ind "FFFFFFFFh";
BA_ "GenSigStartValue" SG_ 1049 NM_Sleep_Ind 1;
BA_ "FlexKomSID" SG_ 1049 NM_Sleep_Ind 472;
BA_ "FlexKomSigStartPos" SG_ 1049 NM_Sleep_Ind 7;
BA_ "FlexKomSigLaenge" SG_ 1049 NM_Sleep_Ind 32;
BA_ "FlexKomSigName" SG_ 1049 NM_Sleep_Ind "NM";
BA_ "FlexKomComment" SG_ 1049 NM_Sleep_Ind "Network management state";
BA_ "FlexKomIsMotorola" SG_ 1049 NM_Sleep_Ind 1;
BA_ "GenSigSNA" SG_ 1049 NM_Sleep_Ind "1h";
BA_ "FlexKomSigStartValue" SG_ 1049 NM_Ud_Srv "FFFFFFFFh";
BA_ "GenSigStartValue" SG_ 1049 NM_Ud_Srv 255;
BA_ "FlexKomSID" SG_ 1049 NM_Ud_Srv 472;
BA_ "FlexKomSigStartPos" SG_ 1049 NM_Ud_Srv 7;
BA_ "FlexKomSigLaenge" SG_ 1049 NM_Ud_Srv 32;
BA_ "FlexKomSigName" SG_ 1049 NM_Ud_Srv "NM";
BA_ "FlexKomComment" SG_ 1049 NM_Ud_Srv "Network management state";
BA_ "FlexKomIsMotorola" SG_ 1049 NM_Ud_Srv 1;
BA_ "GenSigSNA" SG_ 1049 NM_Ud_Srv "FFh";
BA_ "FlexKomSigStartValue" SG_ 1049 Awake_NwSt "000000h";
BA_ "FlexKomSID" SG_ 1049 Awake_NwSt 1478;
BA_ "FlexKomSigStartPos" SG_ 1049 Awake_NwSt 39;
BA_ "FlexKomSigLaenge" SG_ 1049 Awake_NwSt 24;
BA_ "FlexKomSigName" SG_ 1049 Awake_NwSt "Awake_EPB";
BA_ "FlexKomComment" SG_ 1049 Awake_NwSt "Mode 15 of NM_Ud_Srv";
BA_ "FlexKomIsMotorola" SG_ 1049 Awake_NwSt 1;
BA_ "GenSigSNA" SG_ 1049 Awake_NwSt "0h";
BA_ "FlexKomSigStartValue" SG_ 1049 WakeupRsn_EPB "FFFF00h";
BA_ "GenSigStartValue" SG_ 1049 WakeupRsn_EPB 255;
BA_ "FlexKomSID" SG_ 1049 WakeupRsn_EPB 1479;
BA_ "FlexKomSigStartPos" SG_ 1049 WakeupRsn_EPB 39;
BA_ "FlexKomSigLaenge" SG_ 1049 WakeupRsn_EPB 24;
BA_ "FlexKomSigName" SG_ 1049 WakeupRsn_EPB "Wakeup_EPB";
BA_ "FlexKomComment" SG_ 1049 WakeupRsn_EPB "Mode 2 of NM_Ud_Srv";
BA_ "FlexKomIsMotorola" SG_ 1049 WakeupRsn_EPB 1;
BA_ "GenSigSNA" SG_ 1049 WakeupRsn_EPB "FFh";
BA_ "FlexKomSigStartValue" SG_ 1049 Awake_Diag_Actv "000000h";
BA_ "FlexKomSID" SG_ 1049 Awake_Diag_Actv 1478;
BA_ "FlexKomSigStartPos" SG_ 1049 Awake_Diag_Actv 39;
BA_ "FlexKomSigLaenge" SG_ 1049 Awake_Diag_Actv 24;
BA_ "FlexKomSigName" SG_ 1049 Awake_Diag_Actv "Awake_EPB";
BA_ "FlexKomComment" SG_ 1049 Awake_Diag_Actv "Mode 15 of NM_Ud_Srv";
BA_ "FlexKomIsMotorola" SG_ 1049 Awake_Diag_Actv 1;
BA_ "GenSigSNA" SG_ 1049 Awake_Diag_Actv "0h";
BA_ "FlexKomSigStartValue" SG_ 1049 WakeupCnt "FFFF00h";
BA_ "GenSigStartValue" SG_ 1049 WakeupCnt 255;
BA_ "FlexKomSID" SG_ 1049 WakeupCnt 1479;
BA_ "FlexKomSigStartPos" SG_ 1049 WakeupCnt 39;
BA_ "FlexKomSigLaenge" SG_ 1049 WakeupCnt 24;
BA_ "FlexKomSigName" SG_ 1049 WakeupCnt "Wakeup_EPB";
BA_ "FlexKomComment" SG_ 1049 WakeupCnt "Mode 2 of NM_Ud_Srv";
BA_ "FlexKomIsMotorola" SG_ 1049 WakeupCnt 1;
BA_ "GenSigSNA" SG_ 1049 WakeupCnt "FFh";
BA_ "FlexKomSigStartValue" SG_ 1049 Nw_Id "FFh";
BA_ "GenSigStartValue" SG_ 1049 Nw_Id 255;
BA_ "FlexKomSID" SG_ 1049 Nw_Id 535;
BA_ "FlexKomSigStartPos" SG_ 1049 Nw_Id 63;
BA_ "FlexKomSigLaenge" SG_ 1049 Nw_Id 8;
BA_ "FlexKomSigName" SG_ 1049 Nw_Id "Nw_Id";
BA_ "FlexKomComment" SG_ 1049 Nw_Id "Network identification no.";
BA_ "FlexKomIsMotorola" SG_ 1049 Nw_Id 1;
BA_ "GenSigSNA" SG_ 1049 Nw_Id "FFh";
BA_ "FlexKomSigStartValue" SG_ 1050 NM_Mode "FFFFFFFFh";
BA_ "GenSigStartValue" SG_ 1050 NM_Mode 255;
BA_ "FlexKomSID" SG_ 1050 NM_Mode 472;
BA_ "FlexKomSigStartPos" SG_ 1050 NM_Mode 7;
BA_ "FlexKomSigLaenge" SG_ 1050 NM_Mode 32;
BA_ "FlexKomSigName" SG_ 1050 NM_Mode "NM";
BA_ "FlexKomComment" SG_ 1050 NM_Mode "Network management state";
BA_ "FlexKomIsMotorola" SG_ 1050 NM_Mode 1;
BA_ "GenSigSNA" SG_ 1050 NM_Mode "FFh";
BA_ "FlexKomSigStartValue" SG_ 1050 NM_Successor "FFFFFFFFh";
BA_ "GenSigStartValue" SG_ 1050 NM_Successor 255;
BA_ "FlexKomSID" SG_ 1050 NM_Successor 472;
BA_ "FlexKomSigStartPos" SG_ 1050 NM_Successor 7;
BA_ "FlexKomSigLaenge" SG_ 1050 NM_Successor 32;
BA_ "FlexKomSigName" SG_ 1050 NM_Successor "NM";
BA_ "FlexKomComment" SG_ 1050 NM_Successor "Network management state";
BA_ "FlexKomIsMotorola" SG_ 1050 NM_Successor 1;
BA_ "GenSigSNA" SG_ 1050 NM_Successor "FFh";
BA_ "FlexKomSigStartValue" SG_ 1050 NM_Ud_Launch "FFFFFFFFh";
BA_ "GenSigStartValue" SG_ 1050 NM_Ud_Launch 63;
BA_ "FlexKomSID" SG_ 1050 NM_Ud_Launch 472;
BA_ "FlexKomSigStartPos" SG_ 1050 NM_Ud_Launch 7;
BA_ "FlexKomSigLaenge" SG_ 1050 NM_Ud_Launch 32;
BA_ "FlexKomSigName" SG_ 1050 NM_Ud_Launch "NM";
BA_ "FlexKomComment" SG_ 1050 NM_Ud_Launch "Network management state";
BA_ "FlexKomIsMotorola" SG_ 1050 NM_Ud_Launch 1;
BA_ "GenSigSNA" SG_ 1050 NM_Ud_Launch "3Fh";
BA_ "FlexKomSigStartValue" SG_ 1050 NM_Sleep_Ack "FFFFFFFFh";
BA_ "GenSigStartValue" SG_ 1050 NM_Sleep_Ack 1;
BA_ "FlexKomSID" SG_ 1050 NM_Sleep_Ack 472;
BA_ "FlexKomSigStartPos" SG_ 1050 NM_Sleep_Ack 7;
BA_ "FlexKomSigLaenge" SG_ 1050 NM_Sleep_Ack 32;
BA_ "FlexKomSigName" SG_ 1050 NM_Sleep_Ack "NM";
BA_ "FlexKomComment" SG_ 1050 NM_Sleep_Ack "Network management state";
BA_ "FlexKomIsMotorola" SG_ 1050 NM_Sleep_Ack 1;
BA_ "GenSigSNA" SG_ 1050 NM_Sleep_Ack "1h";
BA_ "FlexKomSigStartValue" SG_ 1050 NM_Sleep_Ind "FFFFFFFFh";
BA_ "GenSigStartValue" SG_ 1050 NM_Sleep_Ind 1;
BA_ "FlexKomSID" SG_ 1050 NM_Sleep_Ind 472;
BA_ "FlexKomSigStartPos" SG_ 1050 NM_Sleep_Ind 7;
BA_ "FlexKomSigLaenge" SG_ 1050 NM_Sleep_Ind 32;
BA_ "FlexKomSigName" SG_ 1050 NM_Sleep_Ind "NM";
BA_ "FlexKomComment" SG_ 1050 NM_Sleep_Ind "Network management state";
BA_ "FlexKomIsMotorola" SG_ 1050 NM_Sleep_Ind 1;
BA_ "GenSigSNA" SG_ 1050 NM_Sleep_Ind "1h";
BA_ "FlexKomSigStartValue" SG_ 1050 NM_Ud_Srv "FFFFFFFFh";
BA_ "GenSigStartValue" SG_ 1050 NM_Ud_Srv 255;
BA_ "FlexKomSID" SG_ 1050 NM_Ud_Srv 472;
BA_ "FlexKomSigStartPos" SG_ 1050 NM_Ud_Srv 7;
BA_ "FlexKomSigLaenge" SG_ 1050 NM_Ud_Srv 32;
BA_ "FlexKomSigName" SG_ 1050 NM_Ud_Srv "NM";
BA_ "FlexKomComment" SG_ 1050 NM_Ud_Srv "Network management state";
BA_ "FlexKomIsMotorola" SG_ 1050 NM_Ud_Srv 1;
BA_ "GenSigSNA" SG_ 1050 NM_Ud_Srv "FFh";
BA_ "FlexKomSigStartValue" SG_ 1050 Awake_NwSt "000000h";
BA_ "FlexKomSID" SG_ 1050 Awake_NwSt 1274;
BA_ "FlexKomSigStartPos" SG_ 1050 Awake_NwSt 39;
BA_ "FlexKomSigLaenge" SG_ 1050 Awake_NwSt 24;
BA_ "FlexKomSigName" SG_ 1050 Awake_NwSt "Awake_EPS";
BA_ "FlexKomComment" SG_ 1050 Awake_NwSt "Mode 15 of NM_Ud_Srv";
BA_ "FlexKomIsMotorola" SG_ 1050 Awake_NwSt 1;
BA_ "GenSigSNA" SG_ 1050 Awake_NwSt "0h";
BA_ "FlexKomSigStartValue" SG_ 1050 WakeupRsn_EPS "FFFF00h";
BA_ "GenSigStartValue" SG_ 1050 WakeupRsn_EPS 255;
BA_ "FlexKomSID" SG_ 1050 WakeupRsn_EPS 1273;
BA_ "FlexKomSigStartPos" SG_ 1050 WakeupRsn_EPS 39;
BA_ "FlexKomSigLaenge" SG_ 1050 WakeupRsn_EPS 24;
BA_ "FlexKomSigName" SG_ 1050 WakeupRsn_EPS "Wakeup_EPS";
BA_ "FlexKomComment" SG_ 1050 WakeupRsn_EPS "Mode 2 of NM_Ud_Srv";
BA_ "FlexKomIsMotorola" SG_ 1050 WakeupRsn_EPS 1;
BA_ "GenSigSNA" SG_ 1050 WakeupRsn_EPS "FFh";
BA_ "FlexKomSigStartValue" SG_ 1050 Awake_Diag_Actv "000000h";
BA_ "FlexKomSID" SG_ 1050 Awake_Diag_Actv 1274;
BA_ "FlexKomSigStartPos" SG_ 1050 Awake_Diag_Actv 39;
BA_ "FlexKomSigLaenge" SG_ 1050 Awake_Diag_Actv 24;
BA_ "FlexKomSigName" SG_ 1050 Awake_Diag_Actv "Awake_EPS";
BA_ "FlexKomComment" SG_ 1050 Awake_Diag_Actv "Mode 15 of NM_Ud_Srv";
BA_ "FlexKomIsMotorola" SG_ 1050 Awake_Diag_Actv 1;
BA_ "GenSigSNA" SG_ 1050 Awake_Diag_Actv "0h";
BA_ "FlexKomSigStartValue" SG_ 1050 Awake_Rampout "000000h";
BA_ "FlexKomSID" SG_ 1050 Awake_Rampout 1274;
BA_ "FlexKomSigStartPos" SG_ 1050 Awake_Rampout 39;
BA_ "FlexKomSigLaenge" SG_ 1050 Awake_Rampout 24;
BA_ "FlexKomSigName" SG_ 1050 Awake_Rampout "Awake_EPS";
BA_ "FlexKomComment" SG_ 1050 Awake_Rampout "Mode 15 of NM_Ud_Srv";
BA_ "FlexKomIsMotorola" SG_ 1050 Awake_Rampout 1;
BA_ "GenSigSNA" SG_ 1050 Awake_Rampout "0h";
BA_ "FlexKomSigStartValue" SG_ 1050 Awake_VSS_high "000000h";
BA_ "FlexKomSID" SG_ 1050 Awake_VSS_high 1274;
BA_ "FlexKomSigStartPos" SG_ 1050 Awake_VSS_high 39;
BA_ "FlexKomSigLaenge" SG_ 1050 Awake_VSS_high 24;
BA_ "FlexKomSigName" SG_ 1050 Awake_VSS_high "Awake_EPS";
BA_ "FlexKomComment" SG_ 1050 Awake_VSS_high "Mode 15 of NM_Ud_Srv";
BA_ "FlexKomIsMotorola" SG_ 1050 Awake_VSS_high 1;
BA_ "GenSigSNA" SG_ 1050 Awake_VSS_high "0h";
BA_ "FlexKomSigStartValue" SG_ 1050 Awake_EngRPM_high "000000h";
BA_ "FlexKomSID" SG_ 1050 Awake_EngRPM_high 1274;
BA_ "FlexKomSigStartPos" SG_ 1050 Awake_EngRPM_high 39;
BA_ "FlexKomSigLaenge" SG_ 1050 Awake_EngRPM_high 24;
BA_ "FlexKomSigName" SG_ 1050 Awake_EngRPM_high "Awake_EPS";
BA_ "FlexKomComment" SG_ 1050 Awake_EngRPM_high "Mode 15 of NM_Ud_Srv";
BA_ "FlexKomIsMotorola" SG_ 1050 Awake_EngRPM_high 1;
BA_ "GenSigSNA" SG_ 1050 Awake_EngRPM_high "0h";
BA_ "FlexKomSigStartValue" SG_ 1050 Awake_IgnHigh "000000h";
BA_ "FlexKomSID" SG_ 1050 Awake_IgnHigh 1274;
BA_ "FlexKomSigStartPos" SG_ 1050 Awake_IgnHigh 39;
BA_ "FlexKomSigLaenge" SG_ 1050 Awake_IgnHigh 24;
BA_ "FlexKomSigName" SG_ 1050 Awake_IgnHigh "Awake_EPS";
BA_ "FlexKomComment" SG_ 1050 Awake_IgnHigh "Mode 15 of NM_Ud_Srv";
BA_ "FlexKomIsMotorola" SG_ 1050 Awake_IgnHigh 1;
BA_ "GenSigSNA" SG_ 1050 Awake_IgnHigh "0h";
BA_ "FlexKomSigStartValue" SG_ 1050 WakeupCnt "FFFF00h";
BA_ "GenSigStartValue" SG_ 1050 WakeupCnt 255;
BA_ "FlexKomSID" SG_ 1050 WakeupCnt 1273;
BA_ "FlexKomSigStartPos" SG_ 1050 WakeupCnt 39;
BA_ "FlexKomSigLaenge" SG_ 1050 WakeupCnt 24;
BA_ "FlexKomSigName" SG_ 1050 WakeupCnt "Wakeup_EPS";
BA_ "FlexKomComment" SG_ 1050 WakeupCnt "Mode 2 of NM_Ud_Srv";
BA_ "FlexKomIsMotorola" SG_ 1050 WakeupCnt 1;
BA_ "GenSigSNA" SG_ 1050 WakeupCnt "FFh";
BA_ "FlexKomSigStartValue" SG_ 1050 Nw_Id "FFh";
BA_ "GenSigStartValue" SG_ 1050 Nw_Id 255;
BA_ "FlexKomSID" SG_ 1050 Nw_Id 535;
BA_ "FlexKomSigStartPos" SG_ 1050 Nw_Id 63;
BA_ "FlexKomSigLaenge" SG_ 1050 Nw_Id 8;
BA_ "FlexKomSigName" SG_ 1050 Nw_Id "Nw_Id";
BA_ "FlexKomComment" SG_ 1050 Nw_Id "Network identification no.";
BA_ "FlexKomIsMotorola" SG_ 1050 Nw_Id 1;
BA_ "GenSigSNA" SG_ 1050 Nw_Id "FFh";
BA_ "FlexKomSigStartValue" SG_ 1058 NM_Mode "FFFFFFFFh";
BA_ "GenSigStartValue" SG_ 1058 NM_Mode 255;
BA_ "FlexKomSID" SG_ 1058 NM_Mode 472;
BA_ "FlexKomSigStartPos" SG_ 1058 NM_Mode 7;
BA_ "FlexKomSigLaenge" SG_ 1058 NM_Mode 32;
BA_ "FlexKomSigName" SG_ 1058 NM_Mode "NM";
BA_ "FlexKomComment" SG_ 1058 NM_Mode "Network management state";
BA_ "FlexKomIsMotorola" SG_ 1058 NM_Mode 1;
BA_ "GenSigSNA" SG_ 1058 NM_Mode "FFh";
BA_ "FlexKomSigStartValue" SG_ 1058 NM_Successor "FFFFFFFFh";
BA_ "GenSigStartValue" SG_ 1058 NM_Successor 255;
BA_ "FlexKomSID" SG_ 1058 NM_Successor 472;
BA_ "FlexKomSigStartPos" SG_ 1058 NM_Successor 7;
BA_ "FlexKomSigLaenge" SG_ 1058 NM_Successor 32;
BA_ "FlexKomSigName" SG_ 1058 NM_Successor "NM";
BA_ "FlexKomComment" SG_ 1058 NM_Successor "Network management state";
BA_ "FlexKomIsMotorola" SG_ 1058 NM_Successor 1;
BA_ "GenSigSNA" SG_ 1058 NM_Successor "FFh";
BA_ "FlexKomSigStartValue" SG_ 1058 NM_Ud_Launch "FFFFFFFFh";
BA_ "GenSigStartValue" SG_ 1058 NM_Ud_Launch 63;
BA_ "FlexKomSID" SG_ 1058 NM_Ud_Launch 472;
BA_ "FlexKomSigStartPos" SG_ 1058 NM_Ud_Launch 7;
BA_ "FlexKomSigLaenge" SG_ 1058 NM_Ud_Launch 32;
BA_ "FlexKomSigName" SG_ 1058 NM_Ud_Launch "NM";
BA_ "FlexKomComment" SG_ 1058 NM_Ud_Launch "Network management state";
BA_ "FlexKomIsMotorola" SG_ 1058 NM_Ud_Launch 1;
BA_ "GenSigSNA" SG_ 1058 NM_Ud_Launch "3Fh";
BA_ "FlexKomSigStartValue" SG_ 1058 NM_Sleep_Ack "FFFFFFFFh";
BA_ "GenSigStartValue" SG_ 1058 NM_Sleep_Ack 1;
BA_ "FlexKomSID" SG_ 1058 NM_Sleep_Ack 472;
BA_ "FlexKomSigStartPos" SG_ 1058 NM_Sleep_Ack 7;
BA_ "FlexKomSigLaenge" SG_ 1058 NM_Sleep_Ack 32;
BA_ "FlexKomSigName" SG_ 1058 NM_Sleep_Ack "NM";
BA_ "FlexKomComment" SG_ 1058 NM_Sleep_Ack "Network management state";
BA_ "FlexKomIsMotorola" SG_ 1058 NM_Sleep_Ack 1;
BA_ "GenSigSNA" SG_ 1058 NM_Sleep_Ack "1h";
BA_ "FlexKomSigStartValue" SG_ 1058 NM_Sleep_Ind "FFFFFFFFh";
BA_ "GenSigStartValue" SG_ 1058 NM_Sleep_Ind 1;
BA_ "FlexKomSID" SG_ 1058 NM_Sleep_Ind 472;
BA_ "FlexKomSigStartPos" SG_ 1058 NM_Sleep_Ind 7;
BA_ "FlexKomSigLaenge" SG_ 1058 NM_Sleep_Ind 32;
BA_ "FlexKomSigName" SG_ 1058 NM_Sleep_Ind "NM";
BA_ "FlexKomComment" SG_ 1058 NM_Sleep_Ind "Network management state";
BA_ "FlexKomIsMotorola" SG_ 1058 NM_Sleep_Ind 1;
BA_ "GenSigSNA" SG_ 1058 NM_Sleep_Ind "1h";
BA_ "FlexKomSigStartValue" SG_ 1058 NM_Ud_Srv "FFFFFFFFh";
BA_ "GenSigStartValue" SG_ 1058 NM_Ud_Srv 255;
BA_ "FlexKomSID" SG_ 1058 NM_Ud_Srv 472;
BA_ "FlexKomSigStartPos" SG_ 1058 NM_Ud_Srv 7;
BA_ "FlexKomSigLaenge" SG_ 1058 NM_Ud_Srv 32;
BA_ "FlexKomSigName" SG_ 1058 NM_Ud_Srv "NM";
BA_ "FlexKomComment" SG_ 1058 NM_Ud_Srv "Network management state";
BA_ "FlexKomIsMotorola" SG_ 1058 NM_Ud_Srv 1;
BA_ "GenSigSNA" SG_ 1058 NM_Ud_Srv "FFh";
BA_ "FlexKomSigStartValue" SG_ 1058 Awake_NwSt "000000h";
BA_ "FlexKomSID" SG_ 1058 Awake_NwSt 1270;
BA_ "FlexKomSigStartPos" SG_ 1058 Awake_NwSt 39;
BA_ "FlexKomSigLaenge" SG_ 1058 Awake_NwSt 24;
BA_ "FlexKomSigName" SG_ 1058 Awake_NwSt "Awake_PTS";
BA_ "FlexKomComment" SG_ 1058 Awake_NwSt "Mode 15 of NM_Ud_Srv";
BA_ "FlexKomIsMotorola" SG_ 1058 Awake_NwSt 1;
BA_ "GenSigSNA" SG_ 1058 Awake_NwSt "0h";
BA_ "FlexKomSigStartValue" SG_ 1058 WakeupRsn_PTS "FFFF00h";
BA_ "GenSigStartValue" SG_ 1058 WakeupRsn_PTS 255;
BA_ "FlexKomSID" SG_ 1058 WakeupRsn_PTS 1269;
BA_ "FlexKomSigStartPos" SG_ 1058 WakeupRsn_PTS 39;
BA_ "FlexKomSigLaenge" SG_ 1058 WakeupRsn_PTS 24;
BA_ "FlexKomSigName" SG_ 1058 WakeupRsn_PTS "Wakeup_PTS";
BA_ "FlexKomComment" SG_ 1058 WakeupRsn_PTS "Mode 2 of NM_Ud_Srv";
BA_ "FlexKomIsMotorola" SG_ 1058 WakeupRsn_PTS 1;
BA_ "GenSigSNA" SG_ 1058 WakeupRsn_PTS "FFh";
BA_ "FlexKomSigStartValue" SG_ 1058 Awake_Diag_Actv "000000h";
BA_ "FlexKomSID" SG_ 1058 Awake_Diag_Actv 1270;
BA_ "FlexKomSigStartPos" SG_ 1058 Awake_Diag_Actv 39;
BA_ "FlexKomSigLaenge" SG_ 1058 Awake_Diag_Actv 24;
BA_ "FlexKomSigName" SG_ 1058 Awake_Diag_Actv "Awake_PTS";
BA_ "FlexKomComment" SG_ 1058 Awake_Diag_Actv "Mode 15 of NM_Ud_Srv";
BA_ "FlexKomIsMotorola" SG_ 1058 Awake_Diag_Actv 1;
BA_ "GenSigSNA" SG_ 1058 Awake_Diag_Actv "0h";
BA_ "FlexKomSigStartValue" SG_ 1058 WakeupCnt "FFFF00h";
BA_ "GenSigStartValue" SG_ 1058 WakeupCnt 255;
BA_ "FlexKomSID" SG_ 1058 WakeupCnt 1269;
BA_ "FlexKomSigStartPos" SG_ 1058 WakeupCnt 39;
BA_ "FlexKomSigLaenge" SG_ 1058 WakeupCnt 24;
BA_ "FlexKomSigName" SG_ 1058 WakeupCnt "Wakeup_PTS";
BA_ "FlexKomComment" SG_ 1058 WakeupCnt "Mode 2 of NM_Ud_Srv";
BA_ "FlexKomIsMotorola" SG_ 1058 WakeupCnt 1;
BA_ "GenSigSNA" SG_ 1058 WakeupCnt "FFh";
BA_ "FlexKomSigStartValue" SG_ 1058 Nw_Id "FFh";
BA_ "GenSigStartValue" SG_ 1058 Nw_Id 255;
BA_ "FlexKomSID" SG_ 1058 Nw_Id 535;
BA_ "FlexKomSigStartPos" SG_ 1058 Nw_Id 63;
BA_ "FlexKomSigLaenge" SG_ 1058 Nw_Id 8;
BA_ "FlexKomSigName" SG_ 1058 Nw_Id "Nw_Id";
BA_ "FlexKomComment" SG_ 1058 Nw_Id "Network identification no.";
BA_ "FlexKomIsMotorola" SG_ 1058 Nw_Id 1;
BA_ "GenSigSNA" SG_ 1058 Nw_Id "FFh";
BA_ "FlexKomSigStartValue" SG_ 1059 NM_Mode "FFFFFFFFh";
BA_ "GenSigStartValue" SG_ 1059 NM_Mode 255;
BA_ "FlexKomSID" SG_ 1059 NM_Mode 472;
BA_ "FlexKomSigStartPos" SG_ 1059 NM_Mode 7;
BA_ "FlexKomSigLaenge" SG_ 1059 NM_Mode 32;
BA_ "FlexKomSigName" SG_ 1059 NM_Mode "NM";
BA_ "FlexKomComment" SG_ 1059 NM_Mode "Network management state";
BA_ "FlexKomIsMotorola" SG_ 1059 NM_Mode 1;
BA_ "GenSigSNA" SG_ 1059 NM_Mode "FFh";
BA_ "FlexKomSigStartValue" SG_ 1059 NM_Successor "FFFFFFFFh";
BA_ "GenSigStartValue" SG_ 1059 NM_Successor 255;
BA_ "FlexKomSID" SG_ 1059 NM_Successor 472;
BA_ "FlexKomSigStartPos" SG_ 1059 NM_Successor 7;
BA_ "FlexKomSigLaenge" SG_ 1059 NM_Successor 32;
BA_ "FlexKomSigName" SG_ 1059 NM_Successor "NM";
BA_ "FlexKomComment" SG_ 1059 NM_Successor "Network management state";
BA_ "FlexKomIsMotorola" SG_ 1059 NM_Successor 1;
BA_ "GenSigSNA" SG_ 1059 NM_Successor "FFh";
BA_ "FlexKomSigStartValue" SG_ 1059 NM_Ud_Launch "FFFFFFFFh";
BA_ "GenSigStartValue" SG_ 1059 NM_Ud_Launch 63;
BA_ "FlexKomSID" SG_ 1059 NM_Ud_Launch 472;
BA_ "FlexKomSigStartPos" SG_ 1059 NM_Ud_Launch 7;
BA_ "FlexKomSigLaenge" SG_ 1059 NM_Ud_Launch 32;
BA_ "FlexKomSigName" SG_ 1059 NM_Ud_Launch "NM";
BA_ "FlexKomComment" SG_ 1059 NM_Ud_Launch "Network management state";
BA_ "FlexKomIsMotorola" SG_ 1059 NM_Ud_Launch 1;
BA_ "GenSigSNA" SG_ 1059 NM_Ud_Launch "3Fh";
BA_ "FlexKomSigStartValue" SG_ 1059 NM_Sleep_Ack "FFFFFFFFh";
BA_ "GenSigStartValue" SG_ 1059 NM_Sleep_Ack 1;
BA_ "FlexKomSID" SG_ 1059 NM_Sleep_Ack 472;
BA_ "FlexKomSigStartPos" SG_ 1059 NM_Sleep_Ack 7;
BA_ "FlexKomSigLaenge" SG_ 1059 NM_Sleep_Ack 32;
BA_ "FlexKomSigName" SG_ 1059 NM_Sleep_Ack "NM";
BA_ "FlexKomComment" SG_ 1059 NM_Sleep_Ack "Network management state";
BA_ "FlexKomIsMotorola" SG_ 1059 NM_Sleep_Ack 1;
BA_ "GenSigSNA" SG_ 1059 NM_Sleep_Ack "1h";
BA_ "FlexKomSigStartValue" SG_ 1059 NM_Sleep_Ind "FFFFFFFFh";
BA_ "GenSigStartValue" SG_ 1059 NM_Sleep_Ind 1;
BA_ "FlexKomSID" SG_ 1059 NM_Sleep_Ind 472;
BA_ "FlexKomSigStartPos" SG_ 1059 NM_Sleep_Ind 7;
BA_ "FlexKomSigLaenge" SG_ 1059 NM_Sleep_Ind 32;
BA_ "FlexKomSigName" SG_ 1059 NM_Sleep_Ind "NM";
BA_ "FlexKomComment" SG_ 1059 NM_Sleep_Ind "Network management state";
BA_ "FlexKomIsMotorola" SG_ 1059 NM_Sleep_Ind 1;
BA_ "GenSigSNA" SG_ 1059 NM_Sleep_Ind "1h";
BA_ "FlexKomSigStartValue" SG_ 1059 NM_Ud_Srv "FFFFFFFFh";
BA_ "GenSigStartValue" SG_ 1059 NM_Ud_Srv 255;
BA_ "FlexKomSID" SG_ 1059 NM_Ud_Srv 472;
BA_ "FlexKomSigStartPos" SG_ 1059 NM_Ud_Srv 7;
BA_ "FlexKomSigLaenge" SG_ 1059 NM_Ud_Srv 32;
BA_ "FlexKomSigName" SG_ 1059 NM_Ud_Srv "NM";
BA_ "FlexKomComment" SG_ 1059 NM_Ud_Srv "Network management state";
BA_ "FlexKomIsMotorola" SG_ 1059 NM_Ud_Srv 1;
BA_ "GenSigSNA" SG_ 1059 NM_Ud_Srv "FFh";
BA_ "FlexKomSigStartValue" SG_ 1059 Awake_NwSt "000000h";
BA_ "FlexKomSID" SG_ 1059 Awake_NwSt 524;
BA_ "FlexKomSigStartPos" SG_ 1059 Awake_NwSt 39;
BA_ "FlexKomSigLaenge" SG_ 1059 Awake_NwSt 24;
BA_ "FlexKomSigName" SG_ 1059 Awake_NwSt "Awake_SCCM_Pkt";
BA_ "FlexKomComment" SG_ 1059 Awake_NwSt "Mode 15 of NM_Ud_Srv";
BA_ "FlexKomIsMotorola" SG_ 1059 Awake_NwSt 1;
BA_ "GenSigSNA" SG_ 1059 Awake_NwSt "0h";
BA_ "FlexKomSigStartValue" SG_ 1059 WakeupRsn_SCCM "FFFF00h";
BA_ "GenSigStartValue" SG_ 1059 WakeupRsn_SCCM 255;
BA_ "FlexKomSID" SG_ 1059 WakeupRsn_SCCM 494;
BA_ "FlexKomSigStartPos" SG_ 1059 WakeupRsn_SCCM 39;
BA_ "FlexKomSigLaenge" SG_ 1059 WakeupRsn_SCCM 24;
BA_ "FlexKomSigName" SG_ 1059 WakeupRsn_SCCM "Wakeup_SCCM_Pkt";
BA_ "FlexKomComment" SG_ 1059 WakeupRsn_SCCM "Mode 2 of NM_Ud_Srv";
BA_ "FlexKomIsMotorola" SG_ 1059 WakeupRsn_SCCM 1;
BA_ "GenSigSNA" SG_ 1059 WakeupRsn_SCCM "FFh";
BA_ "FlexKomSigStartValue" SG_ 1059 Awake_Diag_Actv "000000h";
BA_ "FlexKomSID" SG_ 1059 Awake_Diag_Actv 524;
BA_ "FlexKomSigStartPos" SG_ 1059 Awake_Diag_Actv 39;
BA_ "FlexKomSigLaenge" SG_ 1059 Awake_Diag_Actv 24;
BA_ "FlexKomSigName" SG_ 1059 Awake_Diag_Actv "Awake_SCCM_Pkt";
BA_ "FlexKomComment" SG_ 1059 Awake_Diag_Actv "Mode 15 of NM_Ud_Srv";
BA_ "FlexKomIsMotorola" SG_ 1059 Awake_Diag_Actv 1;
BA_ "GenSigSNA" SG_ 1059 Awake_Diag_Actv "0h";
BA_ "FlexKomSigStartValue" SG_ 1059 Awake_StwSw_Actv "000000h";
BA_ "FlexKomSID" SG_ 1059 Awake_StwSw_Actv 524;
BA_ "FlexKomSigStartPos" SG_ 1059 Awake_StwSw_Actv 39;
BA_ "FlexKomSigLaenge" SG_ 1059 Awake_StwSw_Actv 24;
BA_ "FlexKomSigName" SG_ 1059 Awake_StwSw_Actv "Awake_SCCM_Pkt";
BA_ "FlexKomComment" SG_ 1059 Awake_StwSw_Actv "Mode 15 of NM_Ud_Srv";
BA_ "FlexKomIsMotorola" SG_ 1059 Awake_StwSw_Actv 1;
BA_ "GenSigSNA" SG_ 1059 Awake_StwSw_Actv "0h";
BA_ "FlexKomSigStartValue" SG_ 1059 Awake_Ignition_On "000000h";
BA_ "FlexKomSID" SG_ 1059 Awake_Ignition_On 524;
BA_ "FlexKomSigStartPos" SG_ 1059 Awake_Ignition_On 39;
BA_ "FlexKomSigLaenge" SG_ 1059 Awake_Ignition_On 24;
BA_ "FlexKomSigName" SG_ 1059 Awake_Ignition_On "Awake_SCCM_Pkt";
BA_ "FlexKomComment" SG_ 1059 Awake_Ignition_On "Mode 15 of NM_Ud_Srv";
BA_ "FlexKomIsMotorola" SG_ 1059 Awake_Ignition_On 1;
BA_ "GenSigSNA" SG_ 1059 Awake_Ignition_On "0h";
BA_ "FlexKomSigStartValue" SG_ 1059 Awake_EEPROM "000000h";
BA_ "FlexKomSID" SG_ 1059 Awake_EEPROM 524;
BA_ "FlexKomSigStartPos" SG_ 1059 Awake_EEPROM 39;
BA_ "FlexKomSigLaenge" SG_ 1059 Awake_EEPROM 24;
BA_ "FlexKomSigName" SG_ 1059 Awake_EEPROM "Awake_SCCM_Pkt";
BA_ "FlexKomComment" SG_ 1059 Awake_EEPROM "Mode 15 of NM_Ud_Srv";
BA_ "FlexKomIsMotorola" SG_ 1059 Awake_EEPROM 1;
BA_ "GenSigSNA" SG_ 1059 Awake_EEPROM "0h";
BA_ "FlexKomSigStartValue" SG_ 1059 Awake_tilt_tel_Psd "000000h";
BA_ "FlexKomSID" SG_ 1059 Awake_tilt_tel_Psd 524;
BA_ "FlexKomSigStartPos" SG_ 1059 Awake_tilt_tel_Psd 39;
BA_ "FlexKomSigLaenge" SG_ 1059 Awake_tilt_tel_Psd 24;
BA_ "FlexKomSigName" SG_ 1059 Awake_tilt_tel_Psd "Awake_SCCM_Pkt";
BA_ "FlexKomComment" SG_ 1059 Awake_tilt_tel_Psd "Mode 15 of NM_Ud_Srv";
BA_ "FlexKomIsMotorola" SG_ 1059 Awake_tilt_tel_Psd 1;
BA_ "GenSigSNA" SG_ 1059 Awake_tilt_tel_Psd "0h";
BA_ "FlexKomSigStartValue" SG_ 1059 Awake_FTP_Psd "000000h";
BA_ "FlexKomSID" SG_ 1059 Awake_FTP_Psd 524;
BA_ "FlexKomSigStartPos" SG_ 1059 Awake_FTP_Psd 39;
BA_ "FlexKomSigLaenge" SG_ 1059 Awake_FTP_Psd 24;
BA_ "FlexKomSigName" SG_ 1059 Awake_FTP_Psd "Awake_SCCM_Pkt";
BA_ "FlexKomComment" SG_ 1059 Awake_FTP_Psd "Mode 15 of NM_Ud_Srv";
BA_ "FlexKomIsMotorola" SG_ 1059 Awake_FTP_Psd 1;
BA_ "GenSigSNA" SG_ 1059 Awake_FTP_Psd "0h";
BA_ "FlexKomSigStartValue" SG_ 1059 Awake_HrnSwt_Actv "000000h";
BA_ "FlexKomSID" SG_ 1059 Awake_HrnSwt_Actv 524;
BA_ "FlexKomSigStartPos" SG_ 1059 Awake_HrnSwt_Actv 39;
BA_ "FlexKomSigLaenge" SG_ 1059 Awake_HrnSwt_Actv 24;
BA_ "FlexKomSigName" SG_ 1059 Awake_HrnSwt_Actv "Awake_SCCM_Pkt";
BA_ "FlexKomComment" SG_ 1059 Awake_HrnSwt_Actv "Mode 15 of NM_Ud_Srv";
BA_ "FlexKomIsMotorola" SG_ 1059 Awake_HrnSwt_Actv 1;
BA_ "GenSigSNA" SG_ 1059 Awake_HrnSwt_Actv "0h";
BA_ "FlexKomSigStartValue" SG_ 1059 WakeupCnt "FFFF00h";
BA_ "GenSigStartValue" SG_ 1059 WakeupCnt 255;
BA_ "FlexKomSID" SG_ 1059 WakeupCnt 494;
BA_ "FlexKomSigStartPos" SG_ 1059 WakeupCnt 39;
BA_ "FlexKomSigLaenge" SG_ 1059 WakeupCnt 24;
BA_ "FlexKomSigName" SG_ 1059 WakeupCnt "Wakeup_SCCM_Pkt";
BA_ "FlexKomComment" SG_ 1059 WakeupCnt "Mode 2 of NM_Ud_Srv";
BA_ "FlexKomIsMotorola" SG_ 1059 WakeupCnt 1;
BA_ "GenSigSNA" SG_ 1059 WakeupCnt "FFh";
BA_ "FlexKomSigStartValue" SG_ 1059 Nw_Id "FFh";
BA_ "GenSigStartValue" SG_ 1059 Nw_Id 255;
BA_ "FlexKomSID" SG_ 1059 Nw_Id 535;
BA_ "FlexKomSigStartPos" SG_ 1059 Nw_Id 63;
BA_ "FlexKomSigLaenge" SG_ 1059 Nw_Id 8;
BA_ "FlexKomSigName" SG_ 1059 Nw_Id "Nw_Id";
BA_ "FlexKomComment" SG_ 1059 Nw_Id "Network identification no.";
BA_ "FlexKomIsMotorola" SG_ 1059 Nw_Id 1;
BA_ "GenSigSNA" SG_ 1059 Nw_Id "FFh";
BA_ "FlexKomSigStartValue" SG_ 1061 NM_Mode "FFFFFFFFh";
BA_ "GenSigStartValue" SG_ 1061 NM_Mode 255;
BA_ "FlexKomSID" SG_ 1061 NM_Mode 472;
BA_ "FlexKomSigStartPos" SG_ 1061 NM_Mode 7;
BA_ "FlexKomSigLaenge" SG_ 1061 NM_Mode 32;
BA_ "FlexKomSigName" SG_ 1061 NM_Mode "NM";
BA_ "FlexKomComment" SG_ 1061 NM_Mode "Network management state";
BA_ "FlexKomIsMotorola" SG_ 1061 NM_Mode 1;
BA_ "GenSigSNA" SG_ 1061 NM_Mode "FFh";
BA_ "FlexKomSigStartValue" SG_ 1061 NM_Successor "FFFFFFFFh";
BA_ "GenSigStartValue" SG_ 1061 NM_Successor 255;
BA_ "FlexKomSID" SG_ 1061 NM_Successor 472;
BA_ "FlexKomSigStartPos" SG_ 1061 NM_Successor 7;
BA_ "FlexKomSigLaenge" SG_ 1061 NM_Successor 32;
BA_ "FlexKomSigName" SG_ 1061 NM_Successor "NM";
BA_ "FlexKomComment" SG_ 1061 NM_Successor "Network management state";
BA_ "FlexKomIsMotorola" SG_ 1061 NM_Successor 1;
BA_ "GenSigSNA" SG_ 1061 NM_Successor "FFh";
BA_ "FlexKomSigStartValue" SG_ 1061 NM_Ud_Launch "FFFFFFFFh";
BA_ "GenSigStartValue" SG_ 1061 NM_Ud_Launch 63;
BA_ "FlexKomSID" SG_ 1061 NM_Ud_Launch 472;
BA_ "FlexKomSigStartPos" SG_ 1061 NM_Ud_Launch 7;
BA_ "FlexKomSigLaenge" SG_ 1061 NM_Ud_Launch 32;
BA_ "FlexKomSigName" SG_ 1061 NM_Ud_Launch "NM";
BA_ "FlexKomComment" SG_ 1061 NM_Ud_Launch "Network management state";
BA_ "FlexKomIsMotorola" SG_ 1061 NM_Ud_Launch 1;
BA_ "GenSigSNA" SG_ 1061 NM_Ud_Launch "3Fh";
BA_ "FlexKomSigStartValue" SG_ 1061 NM_Sleep_Ack "FFFFFFFFh";
BA_ "GenSigStartValue" SG_ 1061 NM_Sleep_Ack 1;
BA_ "FlexKomSID" SG_ 1061 NM_Sleep_Ack 472;
BA_ "FlexKomSigStartPos" SG_ 1061 NM_Sleep_Ack 7;
BA_ "FlexKomSigLaenge" SG_ 1061 NM_Sleep_Ack 32;
BA_ "FlexKomSigName" SG_ 1061 NM_Sleep_Ack "NM";
BA_ "FlexKomComment" SG_ 1061 NM_Sleep_Ack "Network management state";
BA_ "FlexKomIsMotorola" SG_ 1061 NM_Sleep_Ack 1;
BA_ "GenSigSNA" SG_ 1061 NM_Sleep_Ack "1h";
BA_ "FlexKomSigStartValue" SG_ 1061 NM_Sleep_Ind "FFFFFFFFh";
BA_ "GenSigStartValue" SG_ 1061 NM_Sleep_Ind 1;
BA_ "FlexKomSID" SG_ 1061 NM_Sleep_Ind 472;
BA_ "FlexKomSigStartPos" SG_ 1061 NM_Sleep_Ind 7;
BA_ "FlexKomSigLaenge" SG_ 1061 NM_Sleep_Ind 32;
BA_ "FlexKomSigName" SG_ 1061 NM_Sleep_Ind "NM";
BA_ "FlexKomComment" SG_ 1061 NM_Sleep_Ind "Network management state";
BA_ "FlexKomIsMotorola" SG_ 1061 NM_Sleep_Ind 1;
BA_ "GenSigSNA" SG_ 1061 NM_Sleep_Ind "1h";
BA_ "FlexKomSigStartValue" SG_ 1061 NM_Ud_Srv "FFFFFFFFh";
BA_ "GenSigStartValue" SG_ 1061 NM_Ud_Srv 255;
BA_ "FlexKomSID" SG_ 1061 NM_Ud_Srv 472;
BA_ "FlexKomSigStartPos" SG_ 1061 NM_Ud_Srv 7;
BA_ "FlexKomSigLaenge" SG_ 1061 NM_Ud_Srv 32;
BA_ "FlexKomSigName" SG_ 1061 NM_Ud_Srv "NM";
BA_ "FlexKomComment" SG_ 1061 NM_Ud_Srv "Network management state";
BA_ "FlexKomIsMotorola" SG_ 1061 NM_Ud_Srv 1;
BA_ "GenSigSNA" SG_ 1061 NM_Ud_Srv "FFh";
BA_ "FlexKomSigStartValue" SG_ 1061 Awake_NwSt "000000h";
BA_ "FlexKomSID" SG_ 1061 Awake_NwSt 1996;
BA_ "FlexKomSigStartPos" SG_ 1061 Awake_NwSt 39;
BA_ "FlexKomSigLaenge" SG_ 1061 Awake_NwSt 24;
BA_ "FlexKomSigName" SG_ 1061 Awake_NwSt "Awake_ANC";
BA_ "FlexKomComment" SG_ 1061 Awake_NwSt "Mode 15 of NM_Ud_Srv";
BA_ "FlexKomIsMotorola" SG_ 1061 Awake_NwSt 1;
BA_ "GenSigSNA" SG_ 1061 Awake_NwSt "0h";
BA_ "FlexKomSigStartValue" SG_ 1061 WakeupRsn_ANC "FFFF00h";
BA_ "GenSigStartValue" SG_ 1061 WakeupRsn_ANC 255;
BA_ "FlexKomSID" SG_ 1061 WakeupRsn_ANC 1995;
BA_ "FlexKomSigStartPos" SG_ 1061 WakeupRsn_ANC 39;
BA_ "FlexKomSigLaenge" SG_ 1061 WakeupRsn_ANC 24;
BA_ "FlexKomSigName" SG_ 1061 WakeupRsn_ANC "Wakeup_ANC";
BA_ "FlexKomComment" SG_ 1061 WakeupRsn_ANC "Mode 2 of NM_Ud_Srv";
BA_ "FlexKomIsMotorola" SG_ 1061 WakeupRsn_ANC 1;
BA_ "GenSigSNA" SG_ 1061 WakeupRsn_ANC "FFh";
BA_ "FlexKomSigStartValue" SG_ 1061 Awake_Diag_Actv "000000h";
BA_ "FlexKomSID" SG_ 1061 Awake_Diag_Actv 1996;
BA_ "FlexKomSigStartPos" SG_ 1061 Awake_Diag_Actv 39;
BA_ "FlexKomSigLaenge" SG_ 1061 Awake_Diag_Actv 24;
BA_ "FlexKomSigName" SG_ 1061 Awake_Diag_Actv "Awake_ANC";
BA_ "FlexKomComment" SG_ 1061 Awake_Diag_Actv "Mode 15 of NM_Ud_Srv";
BA_ "FlexKomIsMotorola" SG_ 1061 Awake_Diag_Actv 1;
BA_ "GenSigSNA" SG_ 1061 Awake_Diag_Actv "0h";
BA_ "FlexKomSigStartValue" SG_ 1061 WakeupCnt "FFFF00h";
BA_ "GenSigStartValue" SG_ 1061 WakeupCnt 255;
BA_ "FlexKomSID" SG_ 1061 WakeupCnt 1995;
BA_ "FlexKomSigStartPos" SG_ 1061 WakeupCnt 39;
BA_ "FlexKomSigLaenge" SG_ 1061 WakeupCnt 24;
BA_ "FlexKomSigName" SG_ 1061 WakeupCnt "Wakeup_ANC";
BA_ "FlexKomComment" SG_ 1061 WakeupCnt "Mode 2 of NM_Ud_Srv";
BA_ "FlexKomIsMotorola" SG_ 1061 WakeupCnt 1;
BA_ "GenSigSNA" SG_ 1061 WakeupCnt "FFh";
BA_ "FlexKomSigStartValue" SG_ 1061 Nw_Id "FFh";
BA_ "GenSigStartValue" SG_ 1061 Nw_Id 255;
BA_ "FlexKomSID" SG_ 1061 Nw_Id 535;
BA_ "FlexKomSigStartPos" SG_ 1061 Nw_Id 63;
BA_ "FlexKomSigLaenge" SG_ 1061 Nw_Id 8;
BA_ "FlexKomSigName" SG_ 1061 Nw_Id "Nw_Id";
BA_ "FlexKomComment" SG_ 1061 Nw_Id "Network identification no.";
BA_ "FlexKomIsMotorola" SG_ 1061 Nw_Id 1;
BA_ "GenSigSNA" SG_ 1061 Nw_Id "FFh";
BA_ "FlexKomSigStartValue" SG_ 1062 NM_Mode "FFFFFFFFh";
BA_ "GenSigStartValue" SG_ 1062 NM_Mode 255;
BA_ "FlexKomSID" SG_ 1062 NM_Mode 472;
BA_ "FlexKomSigStartPos" SG_ 1062 NM_Mode 7;
BA_ "FlexKomSigLaenge" SG_ 1062 NM_Mode 32;
BA_ "FlexKomSigName" SG_ 1062 NM_Mode "NM";
BA_ "FlexKomComment" SG_ 1062 NM_Mode "Network management state";
BA_ "FlexKomIsMotorola" SG_ 1062 NM_Mode 1;
BA_ "GenSigSNA" SG_ 1062 NM_Mode "FFh";
BA_ "FlexKomSigStartValue" SG_ 1062 NM_Successor "FFFFFFFFh";
BA_ "GenSigStartValue" SG_ 1062 NM_Successor 255;
BA_ "FlexKomSID" SG_ 1062 NM_Successor 472;
BA_ "FlexKomSigStartPos" SG_ 1062 NM_Successor 7;
BA_ "FlexKomSigLaenge" SG_ 1062 NM_Successor 32;
BA_ "FlexKomSigName" SG_ 1062 NM_Successor "NM";
BA_ "FlexKomComment" SG_ 1062 NM_Successor "Network management state";
BA_ "FlexKomIsMotorola" SG_ 1062 NM_Successor 1;
BA_ "GenSigSNA" SG_ 1062 NM_Successor "FFh";
BA_ "FlexKomSigStartValue" SG_ 1062 NM_Ud_Launch "FFFFFFFFh";
BA_ "GenSigStartValue" SG_ 1062 NM_Ud_Launch 63;
BA_ "FlexKomSID" SG_ 1062 NM_Ud_Launch 472;
BA_ "FlexKomSigStartPos" SG_ 1062 NM_Ud_Launch 7;
BA_ "FlexKomSigLaenge" SG_ 1062 NM_Ud_Launch 32;
BA_ "FlexKomSigName" SG_ 1062 NM_Ud_Launch "NM";
BA_ "FlexKomComment" SG_ 1062 NM_Ud_Launch "Network management state";
BA_ "FlexKomIsMotorola" SG_ 1062 NM_Ud_Launch 1;
BA_ "GenSigSNA" SG_ 1062 NM_Ud_Launch "3Fh";
BA_ "FlexKomSigStartValue" SG_ 1062 NM_Sleep_Ack "FFFFFFFFh";
BA_ "GenSigStartValue" SG_ 1062 NM_Sleep_Ack 1;
BA_ "FlexKomSID" SG_ 1062 NM_Sleep_Ack 472;
BA_ "FlexKomSigStartPos" SG_ 1062 NM_Sleep_Ack 7;
BA_ "FlexKomSigLaenge" SG_ 1062 NM_Sleep_Ack 32;
BA_ "FlexKomSigName" SG_ 1062 NM_Sleep_Ack "NM";
BA_ "FlexKomComment" SG_ 1062 NM_Sleep_Ack "Network management state";
BA_ "FlexKomIsMotorola" SG_ 1062 NM_Sleep_Ack 1;
BA_ "GenSigSNA" SG_ 1062 NM_Sleep_Ack "1h";
BA_ "FlexKomSigStartValue" SG_ 1062 NM_Sleep_Ind "FFFFFFFFh";
BA_ "GenSigStartValue" SG_ 1062 NM_Sleep_Ind 1;
BA_ "FlexKomSID" SG_ 1062 NM_Sleep_Ind 472;
BA_ "FlexKomSigStartPos" SG_ 1062 NM_Sleep_Ind 7;
BA_ "FlexKomSigLaenge" SG_ 1062 NM_Sleep_Ind 32;
BA_ "FlexKomSigName" SG_ 1062 NM_Sleep_Ind "NM";
BA_ "FlexKomComment" SG_ 1062 NM_Sleep_Ind "Network management state";
BA_ "FlexKomIsMotorola" SG_ 1062 NM_Sleep_Ind 1;
BA_ "GenSigSNA" SG_ 1062 NM_Sleep_Ind "1h";
BA_ "FlexKomSigStartValue" SG_ 1062 NM_Ud_Srv "FFFFFFFFh";
BA_ "GenSigStartValue" SG_ 1062 NM_Ud_Srv 255;
BA_ "FlexKomSID" SG_ 1062 NM_Ud_Srv 472;
BA_ "FlexKomSigStartPos" SG_ 1062 NM_Ud_Srv 7;
BA_ "FlexKomSigLaenge" SG_ 1062 NM_Ud_Srv 32;
BA_ "FlexKomSigName" SG_ 1062 NM_Ud_Srv "NM";
BA_ "FlexKomComment" SG_ 1062 NM_Ud_Srv "Network management state";
BA_ "FlexKomIsMotorola" SG_ 1062 NM_Ud_Srv 1;
BA_ "GenSigSNA" SG_ 1062 NM_Ud_Srv "FFh";
BA_ "FlexKomSigStartValue" SG_ 1062 Awake_NwSt "000000h";
BA_ "FlexKomSID" SG_ 1062 Awake_NwSt 621;
BA_ "FlexKomSigStartPos" SG_ 1062 Awake_NwSt 39;
BA_ "FlexKomSigLaenge" SG_ 1062 Awake_NwSt 24;
BA_ "FlexKomSigName" SG_ 1062 Awake_NwSt "Awake_ASCM";
BA_ "FlexKomComment" SG_ 1062 Awake_NwSt "Mode 15 of NM_Ud_Srv";
BA_ "FlexKomIsMotorola" SG_ 1062 Awake_NwSt 1;
BA_ "GenSigSNA" SG_ 1062 Awake_NwSt "0h";
BA_ "FlexKomSigStartValue" SG_ 1062 WakeupRsn_ASCM "FFFF00h";
BA_ "GenSigStartValue" SG_ 1062 WakeupRsn_ASCM 255;
BA_ "FlexKomSID" SG_ 1062 WakeupRsn_ASCM 622;
BA_ "FlexKomSigStartPos" SG_ 1062 WakeupRsn_ASCM 39;
BA_ "FlexKomSigLaenge" SG_ 1062 WakeupRsn_ASCM 24;
BA_ "FlexKomSigName" SG_ 1062 WakeupRsn_ASCM "Wakeup_ASCM";
BA_ "FlexKomComment" SG_ 1062 WakeupRsn_ASCM "Mode 2 of NM_Ud_Srv";
BA_ "FlexKomIsMotorola" SG_ 1062 WakeupRsn_ASCM 1;
BA_ "GenSigSNA" SG_ 1062 WakeupRsn_ASCM "FFh";
BA_ "FlexKomSigStartValue" SG_ 1062 Awake_Diag_Actv "000000h";
BA_ "FlexKomSID" SG_ 1062 Awake_Diag_Actv 621;
BA_ "FlexKomSigStartPos" SG_ 1062 Awake_Diag_Actv 39;
BA_ "FlexKomSigLaenge" SG_ 1062 Awake_Diag_Actv 24;
BA_ "FlexKomSigName" SG_ 1062 Awake_Diag_Actv "Awake_ASCM";
BA_ "FlexKomComment" SG_ 1062 Awake_Diag_Actv "Mode 15 of NM_Ud_Srv";
BA_ "FlexKomIsMotorola" SG_ 1062 Awake_Diag_Actv 1;
BA_ "GenSigSNA" SG_ 1062 Awake_Diag_Actv "0h";
BA_ "FlexKomSigStartValue" SG_ 1062 WakeupCnt "FFFF00h";
BA_ "GenSigStartValue" SG_ 1062 WakeupCnt 255;
BA_ "FlexKomSID" SG_ 1062 WakeupCnt 622;
BA_ "FlexKomSigStartPos" SG_ 1062 WakeupCnt 39;
BA_ "FlexKomSigLaenge" SG_ 1062 WakeupCnt 24;
BA_ "FlexKomSigName" SG_ 1062 WakeupCnt "Wakeup_ASCM";
BA_ "FlexKomComment" SG_ 1062 WakeupCnt "Mode 2 of NM_Ud_Srv";
BA_ "FlexKomIsMotorola" SG_ 1062 WakeupCnt 1;
BA_ "GenSigSNA" SG_ 1062 WakeupCnt "FFh";
BA_ "FlexKomSigStartValue" SG_ 1062 Nw_Id "FFh";
BA_ "GenSigStartValue" SG_ 1062 Nw_Id 255;
BA_ "FlexKomSID" SG_ 1062 Nw_Id 535;
BA_ "FlexKomSigStartPos" SG_ 1062 Nw_Id 63;
BA_ "FlexKomSigLaenge" SG_ 1062 Nw_Id 8;
BA_ "FlexKomSigName" SG_ 1062 Nw_Id "Nw_Id";
BA_ "FlexKomComment" SG_ 1062 Nw_Id "Network identification no.";
BA_ "FlexKomIsMotorola" SG_ 1062 Nw_Id 1;
BA_ "GenSigSNA" SG_ 1062 Nw_Id "FFh";
BA_ "FlexKomSigStartValue" SG_ 1073 NM_Mode "FFFFFFFFh";
BA_ "GenSigStartValue" SG_ 1073 NM_Mode 255;
BA_ "FlexKomSID" SG_ 1073 NM_Mode 472;
BA_ "FlexKomSigStartPos" SG_ 1073 NM_Mode 7;
BA_ "FlexKomSigLaenge" SG_ 1073 NM_Mode 32;
BA_ "FlexKomSigName" SG_ 1073 NM_Mode "NM";
BA_ "FlexKomComment" SG_ 1073 NM_Mode "Network management state";
BA_ "FlexKomIsMotorola" SG_ 1073 NM_Mode 1;
BA_ "GenSigSNA" SG_ 1073 NM_Mode "FFh";
BA_ "FlexKomSigStartValue" SG_ 1073 NM_Successor "FFFFFFFFh";
BA_ "GenSigStartValue" SG_ 1073 NM_Successor 255;
BA_ "FlexKomSID" SG_ 1073 NM_Successor 472;
BA_ "FlexKomSigStartPos" SG_ 1073 NM_Successor 7;
BA_ "FlexKomSigLaenge" SG_ 1073 NM_Successor 32;
BA_ "FlexKomSigName" SG_ 1073 NM_Successor "NM";
BA_ "FlexKomComment" SG_ 1073 NM_Successor "Network management state";
BA_ "FlexKomIsMotorola" SG_ 1073 NM_Successor 1;
BA_ "GenSigSNA" SG_ 1073 NM_Successor "FFh";
BA_ "FlexKomSigStartValue" SG_ 1073 NM_Ud_Launch "FFFFFFFFh";
BA_ "GenSigStartValue" SG_ 1073 NM_Ud_Launch 63;
BA_ "FlexKomSID" SG_ 1073 NM_Ud_Launch 472;
BA_ "FlexKomSigStartPos" SG_ 1073 NM_Ud_Launch 7;
BA_ "FlexKomSigLaenge" SG_ 1073 NM_Ud_Launch 32;
BA_ "FlexKomSigName" SG_ 1073 NM_Ud_Launch "NM";
BA_ "FlexKomComment" SG_ 1073 NM_Ud_Launch "Network management state";
BA_ "FlexKomIsMotorola" SG_ 1073 NM_Ud_Launch 1;
BA_ "GenSigSNA" SG_ 1073 NM_Ud_Launch "3Fh";
BA_ "FlexKomSigStartValue" SG_ 1073 NM_Sleep_Ack "FFFFFFFFh";
BA_ "GenSigStartValue" SG_ 1073 NM_Sleep_Ack 1;
BA_ "FlexKomSID" SG_ 1073 NM_Sleep_Ack 472;
BA_ "FlexKomSigStartPos" SG_ 1073 NM_Sleep_Ack 7;
BA_ "FlexKomSigLaenge" SG_ 1073 NM_Sleep_Ack 32;
BA_ "FlexKomSigName" SG_ 1073 NM_Sleep_Ack "NM";
BA_ "FlexKomComment" SG_ 1073 NM_Sleep_Ack "Network management state";
BA_ "FlexKomIsMotorola" SG_ 1073 NM_Sleep_Ack 1;
BA_ "GenSigSNA" SG_ 1073 NM_Sleep_Ack "1h";
BA_ "FlexKomSigStartValue" SG_ 1073 NM_Sleep_Ind "FFFFFFFFh";
BA_ "GenSigStartValue" SG_ 1073 NM_Sleep_Ind 1;
BA_ "FlexKomSID" SG_ 1073 NM_Sleep_Ind 472;
BA_ "FlexKomSigStartPos" SG_ 1073 NM_Sleep_Ind 7;
BA_ "FlexKomSigLaenge" SG_ 1073 NM_Sleep_Ind 32;
BA_ "FlexKomSigName" SG_ 1073 NM_Sleep_Ind "NM";
BA_ "FlexKomComment" SG_ 1073 NM_Sleep_Ind "Network management state";
BA_ "FlexKomIsMotorola" SG_ 1073 NM_Sleep_Ind 1;
BA_ "GenSigSNA" SG_ 1073 NM_Sleep_Ind "1h";
BA_ "FlexKomSigStartValue" SG_ 1073 NM_Ud_Srv "FFFFFFFFh";
BA_ "GenSigStartValue" SG_ 1073 NM_Ud_Srv 255;
BA_ "FlexKomSID" SG_ 1073 NM_Ud_Srv 472;
BA_ "FlexKomSigStartPos" SG_ 1073 NM_Ud_Srv 7;
BA_ "FlexKomSigLaenge" SG_ 1073 NM_Ud_Srv 32;
BA_ "FlexKomSigName" SG_ 1073 NM_Ud_Srv "NM";
BA_ "FlexKomComment" SG_ 1073 NM_Ud_Srv "Network management state";
BA_ "FlexKomIsMotorola" SG_ 1073 NM_Ud_Srv 1;
BA_ "GenSigSNA" SG_ 1073 NM_Ud_Srv "FFh";
BA_ "FlexKomSigStartValue" SG_ 1073 Awake_NwSt "000000h";
BA_ "FlexKomSID" SG_ 1073 Awake_NwSt 1797;
BA_ "FlexKomSigStartPos" SG_ 1073 Awake_NwSt 39;
BA_ "FlexKomSigLaenge" SG_ 1073 Awake_NwSt 24;
BA_ "FlexKomSigName" SG_ 1073 Awake_NwSt "Awake_VSIM_C";
BA_ "FlexKomComment" SG_ 1073 Awake_NwSt "Mode 15 of NM_Ud_Srv";
BA_ "FlexKomIsMotorola" SG_ 1073 Awake_NwSt 1;
BA_ "GenSigSNA" SG_ 1073 Awake_NwSt "0h";
BA_ "FlexKomSigStartValue" SG_ 1073 WakeupRsn_VSIM_C "FFFF00h";
BA_ "GenSigStartValue" SG_ 1073 WakeupRsn_VSIM_C 255;
BA_ "FlexKomSID" SG_ 1073 WakeupRsn_VSIM_C 1798;
BA_ "FlexKomSigStartPos" SG_ 1073 WakeupRsn_VSIM_C 39;
BA_ "FlexKomSigLaenge" SG_ 1073 WakeupRsn_VSIM_C 24;
BA_ "FlexKomSigName" SG_ 1073 WakeupRsn_VSIM_C "Wakeup_VSIM_C";
BA_ "FlexKomComment" SG_ 1073 WakeupRsn_VSIM_C "Mode 2 of NM_Ud_Srv";
BA_ "FlexKomIsMotorola" SG_ 1073 WakeupRsn_VSIM_C 1;
BA_ "GenSigSNA" SG_ 1073 WakeupRsn_VSIM_C "FFh";
BA_ "FlexKomSigStartValue" SG_ 1073 Awake_Diag_Actv "000000h";
BA_ "FlexKomSID" SG_ 1073 Awake_Diag_Actv 1797;
BA_ "FlexKomSigStartPos" SG_ 1073 Awake_Diag_Actv 39;
BA_ "FlexKomSigLaenge" SG_ 1073 Awake_Diag_Actv 24;
BA_ "FlexKomSigName" SG_ 1073 Awake_Diag_Actv "Awake_VSIM_C";
BA_ "FlexKomComment" SG_ 1073 Awake_Diag_Actv "Mode 15 of NM_Ud_Srv";
BA_ "FlexKomIsMotorola" SG_ 1073 Awake_Diag_Actv 1;
BA_ "GenSigSNA" SG_ 1073 Awake_Diag_Actv "0h";
BA_ "FlexKomSigStartValue" SG_ 1073 WakeupCnt "FFFF00h";
BA_ "GenSigStartValue" SG_ 1073 WakeupCnt 255;
BA_ "FlexKomSID" SG_ 1073 WakeupCnt 1798;
BA_ "FlexKomSigStartPos" SG_ 1073 WakeupCnt 39;
BA_ "FlexKomSigLaenge" SG_ 1073 WakeupCnt 24;
BA_ "FlexKomSigName" SG_ 1073 WakeupCnt "Wakeup_VSIM_C";
BA_ "FlexKomComment" SG_ 1073 WakeupCnt "Mode 2 of NM_Ud_Srv";
BA_ "FlexKomIsMotorola" SG_ 1073 WakeupCnt 1;
BA_ "GenSigSNA" SG_ 1073 WakeupCnt "FFh";
BA_ "FlexKomSigStartValue" SG_ 1073 Nw_Id "FFh";
BA_ "GenSigStartValue" SG_ 1073 Nw_Id 255;
BA_ "FlexKomSID" SG_ 1073 Nw_Id 535;
BA_ "FlexKomSigStartPos" SG_ 1073 Nw_Id 63;
BA_ "FlexKomSigLaenge" SG_ 1073 Nw_Id 8;
BA_ "FlexKomSigName" SG_ 1073 Nw_Id "Nw_Id";
BA_ "FlexKomComment" SG_ 1073 Nw_Id "Network identification no.";
BA_ "FlexKomIsMotorola" SG_ 1073 Nw_Id 1;
BA_ "GenSigSNA" SG_ 1073 Nw_Id "FFh";
BA_ "FlexKomSigStartValue" SG_ 1089 DG_RQ_GLOBAL_UDS "0000000000000000h";
BA_ "FlexKomSID" SG_ 1089 DG_RQ_GLOBAL_UDS 393;
BA_ "FlexKomSigStartPos" SG_ 1089 DG_RQ_GLOBAL_UDS 7;
BA_ "FlexKomSigLaenge" SG_ 1089 DG_RQ_GLOBAL_UDS 64;
BA_ "FlexKomSigName" SG_ 1089 DG_RQ_GLOBAL_UDS "DG_RQ_GLOBAL_UDS";
BA_ "FlexKomComment" SG_ 1089 DG_RQ_GLOBAL_UDS "Diagnostic-Request";
BA_ "FlexKomIsMotorola" SG_ 1089 DG_RQ_GLOBAL_UDS 1;
BA_ "GenSigSNA" SG_ 1089 DG_RQ_GLOBAL_UDS "0h";
BA_ "GenSigSendType" SG_ 1098 VC_VehCfg5_Stat 5;
BA_ "GenSigCycleTime" SG_ 1098 VC_VehCfg5_Stat 2000;
BA_ "FlexKomSigStartValue" SG_ 1098 VC_VehCfg5_Stat "C3FFFFFFFFFFFF00h";
BA_ "GenSigStartValue" SG_ 1098 VC_VehCfg5_Stat 3;
BA_ "GenSigTimeout_IC" SG_ 1098 VC_VehCfg5_Stat 21000;
BA_ "GenSigTimeout_PTS" SG_ 1098 VC_VehCfg5_Stat 21000;
BA_ "GenSigTimeout_EPS" SG_ 1098 VC_VehCfg5_Stat 21000;
BA_ "GenSigTimeout_ORC" SG_ 1098 VC_VehCfg5_Stat 7000;
BA_ "FlexKomSID" SG_ 1098 VC_VehCfg5_Stat 1198;
BA_ "FlexKomSigStartPos" SG_ 1098 VC_VehCfg5_Stat 7;
BA_ "FlexKomSigLaenge" SG_ 1098 VC_VehCfg5_Stat 64;
BA_ "FlexKomSigName" SG_ 1098 VC_VehCfg5_Stat "VehCfg5_Pkt";
BA_ "FlexKomComment" SG_ 1098 VC_VehCfg5_Stat "Vehicle Configuration 5 Packet";
BA_ "FlexKomIsMotorola" SG_ 1098 VC_VehCfg5_Stat 1;
BA_ "GenSigSNA" SG_ 1098 VC_VehCfg5_Stat "3h";
BA_ "GenSigSendType" SG_ 1098 VC_LUCI_PRSNT 5;
BA_ "GenSigCycleTime" SG_ 1098 VC_LUCI_PRSNT 2000;
BA_ "FlexKomSigStartValue" SG_ 1098 VC_LUCI_PRSNT "C3FFFFFFFFFFFF00h";
BA_ "FlexKomSID" SG_ 1098 VC_LUCI_PRSNT 1198;
BA_ "FlexKomSigStartPos" SG_ 1098 VC_LUCI_PRSNT 7;
BA_ "FlexKomSigLaenge" SG_ 1098 VC_LUCI_PRSNT 64;
BA_ "FlexKomSigName" SG_ 1098 VC_LUCI_PRSNT "VehCfg5_Pkt";
BA_ "FlexKomComment" SG_ 1098 VC_LUCI_PRSNT "Vehicle Configuration 5 Packet";
BA_ "FlexKomIsMotorola" SG_ 1098 VC_LUCI_PRSNT 1;
BA_ "GenSigSNA" SG_ 1098 VC_LUCI_PRSNT "0h";
BA_ "GenSigSendType" SG_ 1098 VC_RR_DuallyPrsnt 5;
BA_ "GenSigCycleTime" SG_ 1098 VC_RR_DuallyPrsnt 2000;
BA_ "FlexKomSigStartValue" SG_ 1098 VC_RR_DuallyPrsnt "C3FFFFFFFFFFFF00h";
BA_ "GenSigTimeout_IC" SG_ 1098 VC_RR_DuallyPrsnt 21000;
BA_ "FlexKomSID" SG_ 1098 VC_RR_DuallyPrsnt 1198;
BA_ "FlexKomSigStartPos" SG_ 1098 VC_RR_DuallyPrsnt 7;
BA_ "FlexKomSigLaenge" SG_ 1098 VC_RR_DuallyPrsnt 64;
BA_ "FlexKomSigName" SG_ 1098 VC_RR_DuallyPrsnt "VehCfg5_Pkt";
BA_ "FlexKomComment" SG_ 1098 VC_RR_DuallyPrsnt "Vehicle Configuration 5 Packet";
BA_ "FlexKomIsMotorola" SG_ 1098 VC_RR_DuallyPrsnt 1;
BA_ "GenSigSNA" SG_ 1098 VC_RR_DuallyPrsnt "0h";
BA_ "GenSigSendType" SG_ 1098 VC_NonReg_TPIS 5;
BA_ "GenSigCycleTime" SG_ 1098 VC_NonReg_TPIS 2000;
BA_ "FlexKomSigStartValue" SG_ 1098 VC_NonReg_TPIS "C3FFFFFFFFFFFF00h";
BA_ "GenSigTimeout_IC" SG_ 1098 VC_NonReg_TPIS 21000;
BA_ "FlexKomSID" SG_ 1098 VC_NonReg_TPIS 1198;
BA_ "FlexKomSigStartPos" SG_ 1098 VC_NonReg_TPIS 7;
BA_ "FlexKomSigLaenge" SG_ 1098 VC_NonReg_TPIS 64;
BA_ "FlexKomSigName" SG_ 1098 VC_NonReg_TPIS "VehCfg5_Pkt";
BA_ "FlexKomComment" SG_ 1098 VC_NonReg_TPIS "Vehicle Configuration 5 Packet";
BA_ "FlexKomIsMotorola" SG_ 1098 VC_NonReg_TPIS 1;
BA_ "GenSigSNA" SG_ 1098 VC_NonReg_TPIS "0h";
BA_ "GenSigSendType" SG_ 1098 VC_WTS_Prsnt 5;
BA_ "GenSigCycleTime" SG_ 1098 VC_WTS_Prsnt 2000;
BA_ "FlexKomSigStartValue" SG_ 1098 VC_WTS_Prsnt "C3FFFFFFFFFFFF00h";
BA_ "FlexKomSID" SG_ 1098 VC_WTS_Prsnt 1198;
BA_ "FlexKomSigStartPos" SG_ 1098 VC_WTS_Prsnt 7;
BA_ "FlexKomSigLaenge" SG_ 1098 VC_WTS_Prsnt 64;
BA_ "FlexKomSigName" SG_ 1098 VC_WTS_Prsnt "VehCfg5_Pkt";
BA_ "FlexKomComment" SG_ 1098 VC_WTS_Prsnt "Vehicle Configuration 5 Packet";
BA_ "FlexKomIsMotorola" SG_ 1098 VC_WTS_Prsnt 1;
BA_ "GenSigSNA" SG_ 1098 VC_WTS_Prsnt "0h";
BA_ "GenSigSendType" SG_ 1098 VC_AmbTempLct 5;
BA_ "GenSigCycleTime" SG_ 1098 VC_AmbTempLct 2000;
BA_ "FlexKomSigStartValue" SG_ 1098 VC_AmbTempLct "C3FFFFFFFFFFFF00h";
BA_ "GenSigStartValue" SG_ 1098 VC_AmbTempLct 3;
BA_ "FlexKomSID" SG_ 1098 VC_AmbTempLct 1198;
BA_ "FlexKomSigStartPos" SG_ 1098 VC_AmbTempLct 7;
BA_ "FlexKomSigLaenge" SG_ 1098 VC_AmbTempLct 64;
BA_ "FlexKomSigName" SG_ 1098 VC_AmbTempLct "VehCfg5_Pkt";
BA_ "FlexKomComment" SG_ 1098 VC_AmbTempLct "Vehicle Configuration 5 Packet";
BA_ "FlexKomIsMotorola" SG_ 1098 VC_AmbTempLct 1;
BA_ "GenSigSNA" SG_ 1098 VC_AmbTempLct "3h";
BA_ "GenSigSendType" SG_ 1098 VC_Strng_Rt_0 5;
BA_ "GenSigCycleTime" SG_ 1098 VC_Strng_Rt_0 2000;
BA_ "FlexKomSigStartValue" SG_ 1098 VC_Strng_Rt_0 "C3FFFFFFFFFFFF00h";
BA_ "GenSigStartValue" SG_ 1098 VC_Strng_Rt_0 255;
BA_ "FlexKomSID" SG_ 1098 VC_Strng_Rt_0 1198;
BA_ "FlexKomSigStartPos" SG_ 1098 VC_Strng_Rt_0 7;
BA_ "FlexKomSigLaenge" SG_ 1098 VC_Strng_Rt_0 64;
BA_ "FlexKomSigName" SG_ 1098 VC_Strng_Rt_0 "VehCfg5_Pkt";
BA_ "FlexKomComment" SG_ 1098 VC_Strng_Rt_0 "Vehicle Configuration 5 Packet";
BA_ "FlexKomIsMotorola" SG_ 1098 VC_Strng_Rt_0 1;
BA_ "GenSigSNA" SG_ 1098 VC_Strng_Rt_0 "FFh";
BA_ "GenSigSendType" SG_ 1098 VC_Strng_Rt_pls1 5;
BA_ "GenSigCycleTime" SG_ 1098 VC_Strng_Rt_pls1 2000;
BA_ "FlexKomSigStartValue" SG_ 1098 VC_Strng_Rt_pls1 "C3FFFFFFFFFFFF00h";
BA_ "GenSigStartValue" SG_ 1098 VC_Strng_Rt_pls1 255;
BA_ "FlexKomSID" SG_ 1098 VC_Strng_Rt_pls1 1198;
BA_ "FlexKomSigStartPos" SG_ 1098 VC_Strng_Rt_pls1 7;
BA_ "FlexKomSigLaenge" SG_ 1098 VC_Strng_Rt_pls1 64;
BA_ "FlexKomSigName" SG_ 1098 VC_Strng_Rt_pls1 "VehCfg5_Pkt";
BA_ "FlexKomComment" SG_ 1098 VC_Strng_Rt_pls1 "Vehicle Configuration 5 Packet";
BA_ "FlexKomIsMotorola" SG_ 1098 VC_Strng_Rt_pls1 1;
BA_ "GenSigSNA" SG_ 1098 VC_Strng_Rt_pls1 "FFh";
BA_ "GenSigSendType" SG_ 1098 VC_Strng_Rt_pls2 5;
BA_ "GenSigCycleTime" SG_ 1098 VC_Strng_Rt_pls2 2000;
BA_ "FlexKomSigStartValue" SG_ 1098 VC_Strng_Rt_pls2 "C3FFFFFFFFFFFF00h";
BA_ "GenSigStartValue" SG_ 1098 VC_Strng_Rt_pls2 255;
BA_ "FlexKomSID" SG_ 1098 VC_Strng_Rt_pls2 1198;
BA_ "FlexKomSigStartPos" SG_ 1098 VC_Strng_Rt_pls2 7;
BA_ "FlexKomSigLaenge" SG_ 1098 VC_Strng_Rt_pls2 64;
BA_ "FlexKomSigName" SG_ 1098 VC_Strng_Rt_pls2 "VehCfg5_Pkt";
BA_ "FlexKomComment" SG_ 1098 VC_Strng_Rt_pls2 "Vehicle Configuration 5 Packet";
BA_ "FlexKomIsMotorola" SG_ 1098 VC_Strng_Rt_pls2 1;
BA_ "GenSigSNA" SG_ 1098 VC_Strng_Rt_pls2 "FFh";
BA_ "GenSigSendType" SG_ 1098 VC_Strng_Rt_pls3 5;
BA_ "GenSigCycleTime" SG_ 1098 VC_Strng_Rt_pls3 2000;
BA_ "FlexKomSigStartValue" SG_ 1098 VC_Strng_Rt_pls3 "C3FFFFFFFFFFFF00h";
BA_ "GenSigStartValue" SG_ 1098 VC_Strng_Rt_pls3 255;
BA_ "FlexKomSID" SG_ 1098 VC_Strng_Rt_pls3 1198;
BA_ "FlexKomSigStartPos" SG_ 1098 VC_Strng_Rt_pls3 7;
BA_ "FlexKomSigLaenge" SG_ 1098 VC_Strng_Rt_pls3 64;
BA_ "FlexKomSigName" SG_ 1098 VC_Strng_Rt_pls3 "VehCfg5_Pkt";
BA_ "FlexKomComment" SG_ 1098 VC_Strng_Rt_pls3 "Vehicle Configuration 5 Packet";
BA_ "FlexKomIsMotorola" SG_ 1098 VC_Strng_Rt_pls3 1;
BA_ "GenSigSNA" SG_ 1098 VC_Strng_Rt_pls3 "FFh";
BA_ "GenSigSendType" SG_ 1098 VC_Strng_Rt_pls4 5;
BA_ "GenSigCycleTime" SG_ 1098 VC_Strng_Rt_pls4 2000;
BA_ "FlexKomSigStartValue" SG_ 1098 VC_Strng_Rt_pls4 "C3FFFFFFFFFFFF00h";
BA_ "GenSigStartValue" SG_ 1098 VC_Strng_Rt_pls4 255;
BA_ "FlexKomSID" SG_ 1098 VC_Strng_Rt_pls4 1198;
BA_ "FlexKomSigStartPos" SG_ 1098 VC_Strng_Rt_pls4 7;
BA_ "FlexKomSigLaenge" SG_ 1098 VC_Strng_Rt_pls4 64;
BA_ "FlexKomSigName" SG_ 1098 VC_Strng_Rt_pls4 "VehCfg5_Pkt";
BA_ "FlexKomComment" SG_ 1098 VC_Strng_Rt_pls4 "Vehicle Configuration 5 Packet";
BA_ "FlexKomIsMotorola" SG_ 1098 VC_Strng_Rt_pls4 1;
BA_ "GenSigSNA" SG_ 1098 VC_Strng_Rt_pls4 "FFh";
BA_ "GenSigSendType" SG_ 1098 VC_Strng_Rt_pls5 5;
BA_ "GenSigCycleTime" SG_ 1098 VC_Strng_Rt_pls5 2000;
BA_ "FlexKomSigStartValue" SG_ 1098 VC_Strng_Rt_pls5 "C3FFFFFFFFFFFF00h";
BA_ "GenSigStartValue" SG_ 1098 VC_Strng_Rt_pls5 255;
BA_ "FlexKomSID" SG_ 1098 VC_Strng_Rt_pls5 1198;
BA_ "FlexKomSigStartPos" SG_ 1098 VC_Strng_Rt_pls5 7;
BA_ "FlexKomSigLaenge" SG_ 1098 VC_Strng_Rt_pls5 64;
BA_ "FlexKomSigName" SG_ 1098 VC_Strng_Rt_pls5 "VehCfg5_Pkt";
BA_ "FlexKomComment" SG_ 1098 VC_Strng_Rt_pls5 "Vehicle Configuration 5 Packet";
BA_ "FlexKomIsMotorola" SG_ 1098 VC_Strng_Rt_pls5 1;
BA_ "GenSigSNA" SG_ 1098 VC_Strng_Rt_pls5 "FFh";
BA_ "GenSigSendType" SG_ 1098 VC_RearDoorLocks2DCM 5;
BA_ "GenSigCycleTime" SG_ 1098 VC_RearDoorLocks2DCM 2000;
BA_ "FlexKomSigStartValue" SG_ 1098 VC_RearDoorLocks2DCM "C3FFFFFFFFFFFF00h";
BA_ "FlexKomSID" SG_ 1098 VC_RearDoorLocks2DCM 1198;
BA_ "FlexKomSigStartPos" SG_ 1098 VC_RearDoorLocks2DCM 7;
BA_ "FlexKomSigLaenge" SG_ 1098 VC_RearDoorLocks2DCM 64;
BA_ "FlexKomSigName" SG_ 1098 VC_RearDoorLocks2DCM "VehCfg5_Pkt";
BA_ "FlexKomComment" SG_ 1098 VC_RearDoorLocks2DCM "Vehicle Configuration 5 Packet";
BA_ "FlexKomIsMotorola" SG_ 1098 VC_RearDoorLocks2DCM 1;
BA_ "GenSigSNA" SG_ 1098 VC_RearDoorLocks2DCM "0h";
BA_ "GenSigSendType" SG_ 1098 VC_SpdLmt_PRSNT 5;
BA_ "GenSigCycleTime" SG_ 1098 VC_SpdLmt_PRSNT 2000;
BA_ "FlexKomSigStartValue" SG_ 1098 VC_SpdLmt_PRSNT "C3FFFFFFFFFFFF00h";
BA_ "GenSigTimeout_IC" SG_ 1098 VC_SpdLmt_PRSNT 21000;
BA_ "FlexKomSID" SG_ 1098 VC_SpdLmt_PRSNT 1198;
BA_ "FlexKomSigStartPos" SG_ 1098 VC_SpdLmt_PRSNT 7;
BA_ "FlexKomSigLaenge" SG_ 1098 VC_SpdLmt_PRSNT 64;
BA_ "FlexKomSigName" SG_ 1098 VC_SpdLmt_PRSNT "VehCfg5_Pkt";
BA_ "FlexKomComment" SG_ 1098 VC_SpdLmt_PRSNT "Vehicle Configuration 5 Packet";
BA_ "FlexKomIsMotorola" SG_ 1098 VC_SpdLmt_PRSNT 1;
BA_ "GenSigSNA" SG_ 1098 VC_SpdLmt_PRSNT "0h";
BA_ "GenSigSendType" SG_ 1098 VC_SBR_Prsnt 5;
BA_ "GenSigCycleTime" SG_ 1098 VC_SBR_Prsnt 2000;
BA_ "FlexKomSigStartValue" SG_ 1098 VC_SBR_Prsnt "C3FFFFFFFFFFFF00h";
BA_ "GenSigTimeout_ORC" SG_ 1098 VC_SBR_Prsnt 7000;
BA_ "FlexKomSID" SG_ 1098 VC_SBR_Prsnt 1198;
BA_ "FlexKomSigStartPos" SG_ 1098 VC_SBR_Prsnt 7;
BA_ "FlexKomSigLaenge" SG_ 1098 VC_SBR_Prsnt 64;
BA_ "FlexKomSigName" SG_ 1098 VC_SBR_Prsnt "VehCfg5_Pkt";
BA_ "FlexKomComment" SG_ 1098 VC_SBR_Prsnt "Vehicle Configuration 5 Packet";
BA_ "FlexKomIsMotorola" SG_ 1098 VC_SBR_Prsnt 1;
BA_ "GenSigSNA" SG_ 1098 VC_SBR_Prsnt "0h";
BA_ "GenSigSendType" SG_ 1098 VC_ChildDisp_Prsnt 5;
BA_ "GenSigCycleTime" SG_ 1098 VC_ChildDisp_Prsnt 2000;
BA_ "FlexKomSigStartValue" SG_ 1098 VC_ChildDisp_Prsnt "C3FFFFFFFFFFFF00h";
BA_ "GenSigTimeout_ORC" SG_ 1098 VC_ChildDisp_Prsnt 7000;
BA_ "FlexKomSID" SG_ 1098 VC_ChildDisp_Prsnt 1198;
BA_ "FlexKomSigStartPos" SG_ 1098 VC_ChildDisp_Prsnt 7;
BA_ "FlexKomSigLaenge" SG_ 1098 VC_ChildDisp_Prsnt 64;
BA_ "FlexKomSigName" SG_ 1098 VC_ChildDisp_Prsnt "VehCfg5_Pkt";
BA_ "FlexKomComment" SG_ 1098 VC_ChildDisp_Prsnt "Vehicle Configuration 5 Packet";
BA_ "FlexKomIsMotorola" SG_ 1098 VC_ChildDisp_Prsnt 1;
BA_ "GenSigSNA" SG_ 1098 VC_ChildDisp_Prsnt "0h";
BA_ "GenSigSendType" SG_ 1098 VC_OffRoadPg 5;
BA_ "GenSigCycleTime" SG_ 1098 VC_OffRoadPg 2000;
BA_ "FlexKomSigStartValue" SG_ 1098 VC_OffRoadPg "C3FFFFFFFFFFFF00h";
BA_ "GenSigTimeout_IC" SG_ 1098 VC_OffRoadPg 21000;
BA_ "FlexKomSID" SG_ 1098 VC_OffRoadPg 1198;
BA_ "FlexKomSigStartPos" SG_ 1098 VC_OffRoadPg 7;
BA_ "FlexKomSigLaenge" SG_ 1098 VC_OffRoadPg 64;
BA_ "FlexKomSigName" SG_ 1098 VC_OffRoadPg "VehCfg5_Pkt";
BA_ "FlexKomComment" SG_ 1098 VC_OffRoadPg "Vehicle Configuration 5 Packet";
BA_ "FlexKomIsMotorola" SG_ 1098 VC_OffRoadPg 1;
BA_ "GenSigSNA" SG_ 1098 VC_OffRoadPg "0h";
BA_ "GenSigSendType" SG_ 1098 VC_AmbLtgPrsnt 5;
BA_ "GenSigCycleTime" SG_ 1098 VC_AmbLtgPrsnt 2000;
BA_ "FlexKomSigStartValue" SG_ 1098 VC_AmbLtgPrsnt "C3FFFFFFFFFFFF00h";
BA_ "GenSigTimeout_IC" SG_ 1098 VC_AmbLtgPrsnt 21000;
BA_ "FlexKomSID" SG_ 1098 VC_AmbLtgPrsnt 1198;
BA_ "FlexKomSigStartPos" SG_ 1098 VC_AmbLtgPrsnt 7;
BA_ "FlexKomSigLaenge" SG_ 1098 VC_AmbLtgPrsnt 64;
BA_ "FlexKomSigName" SG_ 1098 VC_AmbLtgPrsnt "VehCfg5_Pkt";
BA_ "FlexKomComment" SG_ 1098 VC_AmbLtgPrsnt "Vehicle Configuration 5 Packet";
BA_ "FlexKomIsMotorola" SG_ 1098 VC_AmbLtgPrsnt 1;
BA_ "GenSigSNA" SG_ 1098 VC_AmbLtgPrsnt "0h";
BA_ "GenSigSendType" SG_ 1098 VC_PPPA_Prsnt 5;
BA_ "GenSigCycleTime" SG_ 1098 VC_PPPA_Prsnt 2000;
BA_ "FlexKomSigStartValue" SG_ 1098 VC_PPPA_Prsnt "C3FFFFFFFFFFFF00h";
BA_ "GenSigTimeout_IC" SG_ 1098 VC_PPPA_Prsnt 21000;
BA_ "GenSigTimeout_PTS" SG_ 1098 VC_PPPA_Prsnt 21000;
BA_ "GenSigTimeout_EPS" SG_ 1098 VC_PPPA_Prsnt 21000;
BA_ "FlexKomSID" SG_ 1098 VC_PPPA_Prsnt 1198;
BA_ "FlexKomSigStartPos" SG_ 1098 VC_PPPA_Prsnt 7;
BA_ "FlexKomSigLaenge" SG_ 1098 VC_PPPA_Prsnt 64;
BA_ "FlexKomSigName" SG_ 1098 VC_PPPA_Prsnt "VehCfg5_Pkt";
BA_ "FlexKomComment" SG_ 1098 VC_PPPA_Prsnt "Vehicle Configuration 5 Packet";
BA_ "FlexKomIsMotorola" SG_ 1098 VC_PPPA_Prsnt 1;
BA_ "GenSigSNA" SG_ 1098 VC_PPPA_Prsnt "0h";
BA_ "GenSigSendType" SG_ 1098 VC_ParkStopPrsnt 5;
BA_ "GenSigCycleTime" SG_ 1098 VC_ParkStopPrsnt 2000;
BA_ "FlexKomSigStartValue" SG_ 1098 VC_ParkStopPrsnt "C3FFFFFFFFFFFF00h";
BA_ "GenSigTimeout_PTS" SG_ 1098 VC_ParkStopPrsnt 21000;
BA_ "FlexKomSID" SG_ 1098 VC_ParkStopPrsnt 1198;
BA_ "FlexKomSigStartPos" SG_ 1098 VC_ParkStopPrsnt 7;
BA_ "FlexKomSigLaenge" SG_ 1098 VC_ParkStopPrsnt 64;
BA_ "FlexKomSigName" SG_ 1098 VC_ParkStopPrsnt "VehCfg5_Pkt";
BA_ "FlexKomComment" SG_ 1098 VC_ParkStopPrsnt "Vehicle Configuration 5 Packet";
BA_ "FlexKomIsMotorola" SG_ 1098 VC_ParkStopPrsnt 1;
BA_ "GenSigSNA" SG_ 1098 VC_ParkStopPrsnt "0h";
VAL_ 1013 EC_ECUCfg6_Stat 3 "SNA" 2 "REQUEST_DATA" 1 "PROGAMMED" 0 "NA" ;
VAL_ 1014 EC_ECUCfg7_Stat 3 "SNA" 2 "REQUEST_DATA" 1 "PROGAMMED" 0 "NA" ;
VAL_ 1015 EC_ECUCfg8_Stat 3 "SNA" 2 "REQUEST_DATA" 1 "PROGAMMED" 0 "NA" ;
VAL_ 1016 EC_BU_ECUCfg1_Stat 3 "SNA" 2 "NA1" 1 "PROGAMMED" 0 "NA" ;
VAL_ 1017 EC_BU_ECUCfg2_Stat 3 "SNA" 2 "NA1" 1 "PROGAMMED" 0 "NA" ;
VAL_ 1018 EC_BU_ECUCfg3_Stat 3 "SNA" 2 "NA1" 1 "PROGAMMED" 0 "NA" ;
VAL_ 1019 EC_BU_ECUCfg4_Stat 3 "SNA" 2 "NA1" 1 "PROGAMMED" 0 "NA" ;
VAL_ 1020 EC_BU_ECUCfg5_Stat 3 "SNA" 2 "NA1" 1 "PROGAMMED" 0 "NA" ;
VAL_ 1021 EC_BU_ECUCfg6_Stat 3 "SNA" 2 "NA1" 1 "PROGAMMED" 0 "NA" ;
VAL_ 1022 EC_BU_ECUCfg7_Stat 3 "SNA" 2 "NA1" 1 "PROGAMMED" 0 "NA" ;
VAL_ 1023 EC_BU_ECUCfg8_Stat 3 "SNA" 2 "NA1" 1 "PROGAMMED" 0 "NA" ;
VAL_ 1024 NM_Mode 255 "SNA" 254 "ALIVE" 253 "RING" 252 "LHOM" ;
VAL_ 1024 NM_Successor 255 "SNA" ;
VAL_ 1024 NM_Ud_Launch 63 "SNA" 4 "BROADCAST" ;
VAL_ 1024 NM_Ud_Srv 255 "NO_USER_DATA" 15 "AWAKE_BC" 2 "WAKEUP_SA" ;
VAL_ 1024 WakeupRsn_RF_HUB 255 "SNA" 10 "CLUTCH" 9 "TIMER" 8 "RESET" 7 "RF_INPUT" 6 "AP5" 5 "AP4" 4 "AP3" 3 "AP2" 2 "AP1" 1 "SSB" 0 "NETWORK" ;
VAL_ 1024 WakeupCnt 255 "SNA" ;
VAL_ 1024 Nw_Id 255 "SNA" 2 "AUDIO_TELE" 1 "BODY" 0 "POWERTRAIN" ;
VAL_ 1025 NM_Mode 255 "SNA" 254 "ALIVE" 253 "RING" 252 "LHOM" ;
VAL_ 1025 NM_Successor 255 "SNA" ;
VAL_ 1025 NM_Ud_Launch 63 "SNA" 4 "BROADCAST" ;
VAL_ 1025 NM_Ud_Srv 255 "NO_USER_DATA" 15 "AWAKE_BC" 2 "WAKEUP_SA" ;
VAL_ 1025 WakeupRsn_CBC 255 "SNA" 23 "CON_LAMP_LD" 22 "CARGO_SW" 21 "PD_SW" 20 "HL_SW" 19 "BRK_SW" 18 "SS_SW" 17 "HAZARD_SW" 16 "PASS_LK_SW" 15 "DRV_LK_SW" 14 "TK_FG_SW" 13 "HRD_TOP_STEALTH" 12 "HOOD_AJAR" 11 "FG_AJAR" 10 "TLG_AJAR" 9 "R_R_AJAR" 8 "L_R_AJAR" 7 "PSG_AJAR" 6 "DRV_AJAR" 5 "LIN_THREE" 4 "LIN_TWO" 3 "LIN_ONE" 2 "CAN_I" 1 "CAN_C" 0 "NETWORK" ;
VAL_ 1025 WakeupCnt 255 "SNA" ;
VAL_ 1025 Nw_Id 255 "SNA" 2 "AUDIO_TELE" 1 "BODY" 0 "POWERTRAIN" ;
VAL_ 1026 NM_Mode 255 "SNA" 254 "ALIVE" 253 "RING" 252 "LHOM" ;
VAL_ 1026 NM_Successor 255 "SNA" ;
VAL_ 1026 NM_Ud_Launch 63 "SNA" 4 "BROADCAST" ;
VAL_ 1026 NM_Ud_Srv 255 "NO_USER_DATA" 15 "AWAKE_BC" 2 "WAKEUP_SA" ;
VAL_ 1026 WakeupRsn_IC 255 "SNA" 1 "IGN" 0 "NETWORK" ;
VAL_ 1026 WakeupCnt 255 "SNA" ;
VAL_ 1026 Nw_Id 255 "SNA" 2 "AUDIO_TELE" 1 "BODY" 0 "POWERTRAIN" ;
VAL_ 1027 NM_Mode 255 "SNA" 254 "ALIVE" 253 "RING" 252 "LHOM" ;
VAL_ 1027 NM_Successor 255 "SNA" ;
VAL_ 1027 NM_Ud_Launch 63 "SNA" 4 "BROADCAST" ;
VAL_ 1027 NM_Ud_Srv 255 "NO_USER_DATA" 15 "AWAKE_BC" 2 "WAKEUP_SA" ;
VAL_ 1027 WakeupRsn_TPM 255 "SNA" 0 "NETWORK" ;
VAL_ 1027 WakeupCnt 255 "SNA" ;
VAL_ 1027 Nw_Id 255 "SNA" 2 "AUDIO_TELE" 1 "BODY" 0 "POWERTRAIN" ;
VAL_ 1029 NM_Mode 255 "SNA" 254 "ALIVE" 253 "RING" 252 "LHOM" ;
VAL_ 1029 NM_Successor 255 "SNA" ;
VAL_ 1029 NM_Ud_Launch 63 "SNA" 4 "BROADCAST" ;
VAL_ 1029 NM_Ud_Srv 255 "NO_USER_DATA" 15 "AWAKE_BC" 2 "WAKEUP_SA" ;
VAL_ 1029 WakeupRsn_RBT_DR 255 "SNA" 0 "NETWORK" ;
VAL_ 1029 WakeupCnt 255 "SNA" ;
VAL_ 1029 Nw_Id 255 "SNA" 2 "AUDIO_TELE" 1 "BODY" 0 "POWERTRAIN" ;
VAL_ 1030 NM_Mode 255 "SNA" 254 "ALIVE" 253 "RING" 252 "LHOM" ;
VAL_ 1030 NM_Successor 255 "SNA" ;
VAL_ 1030 NM_Ud_Launch 63 "SNA" 4 "BROADCAST" ;
VAL_ 1030 NM_Ud_Srv 255 "NO_USER_DATA" 15 "AWAKE_BC" 2 "WAKEUP_SA" ;
VAL_ 1030 WakeupRsn_RBT_PASS 255 "SNA" 0 "NETWORK" ;
VAL_ 1030 WakeupCnt 255 "SNA" ;
VAL_ 1030 Nw_Id 255 "SNA" 2 "AUDIO_TELE" 1 "BODY" 0 "POWERTRAIN" ;
VAL_ 1031 NM_Mode 255 "SNA" 254 "ALIVE" 253 "RING" 252 "LHOM" ;
VAL_ 1031 NM_Successor 255 "SNA" ;
VAL_ 1031 NM_Ud_Launch 63 "SNA" 4 "BROADCAST" ;
VAL_ 1031 NM_Ud_Srv 255 "NO_USER_DATA" 15 "AWAKE_BC" 2 "WAKEUP_SA" ;
VAL_ 1031 WakeupRsn_ESC 255 "SNA" 0 "NETWORK" ;
VAL_ 1031 WakeupCnt 255 "SNA" ;
VAL_ 1031 Nw_Id 255 "SNA" 2 "AUDIO_TELE" 1 "BODY" 0 "POWERTRAIN" ;
VAL_ 1033 NM_Mode 255 "SNA" 254 "ALIVE" 253 "RING" 252 "LHOM" ;
VAL_ 1033 NM_Successor 255 "SNA" ;
VAL_ 1033 NM_Ud_Launch 63 "SNA" 4 "BROADCAST" ;
VAL_ 1033 NM_Ud_Srv 255 "NO_USER_DATA" 15 "AWAKE_BC" 2 "WAKEUP_SA" ;
VAL_ 1033 WakeupRsn_SBWM 255 "SNA" 1 "UNLK_R_S" 0 "NETWORK" ;
VAL_ 1033 WakeupCnt 255 "SNA" ;
VAL_ 1033 Nw_Id 255 "SNA" 2 "AUDIO_TELE" 1 "BODY" 0 "POWERTRAIN" ;
VAL_ 1044 NM_Mode 255 "SNA" 254 "ALIVE" 253 "RING" 252 "LHOM" ;
VAL_ 1044 NM_Successor 255 "SNA" ;
VAL_ 1044 NM_Ud_Launch 63 "SNA" 4 "BROADCAST" ;
VAL_ 1044 NM_Ud_Srv 255 "NO_USER_DATA" 15 "AWAKE_BC" 2 "WAKEUP_SA" ;
VAL_ 1044 WakeupRsn_ITBM 255 "SNA" 0 "NETWORK" ;
VAL_ 1044 WakeupCnt 255 "SNA" ;
VAL_ 1044 Nw_Id 255 "SNA" 2 "AUDIO_TELE" 1 "BODY" 0 "POWERTRAIN" ;
VAL_ 1049 NM_Mode 255 "SNA" 254 "ALIVE" 253 "RING" 252 "LHOM" ;
VAL_ 1049 NM_Successor 255 "SNA" ;
VAL_ 1049 NM_Ud_Launch 63 "SNA" 4 "BROADCAST" ;
VAL_ 1049 NM_Ud_Srv 255 "NO_USER_DATA" 15 "AWAKE_BC" 2 "WAKEUP_SA" ;
VAL_ 1049 WakeupRsn_EPB 255 "SNA" 0 "NETWORK" ;
VAL_ 1049 WakeupCnt 255 "SNA" ;
VAL_ 1049 Nw_Id 255 "SNA" 2 "AUDIO_TELE" 1 "BODY" 0 "POWERTRAIN" ;
VAL_ 1050 NM_Mode 255 "SNA" 254 "ALIVE" 253 "RING" 252 "LHOM" ;
VAL_ 1050 NM_Successor 255 "SNA" ;
VAL_ 1050 NM_Ud_Launch 63 "SNA" 4 "BROADCAST" ;
VAL_ 1050 NM_Ud_Srv 255 "NO_USER_DATA" 15 "AWAKE_BC" 2 "WAKEUP_SA" ;
VAL_ 1050 WakeupRsn_EPS 255 "SNA" 1 "IGN" 0 "NETWORK" ;
VAL_ 1050 WakeupCnt 255 "SNA" ;
VAL_ 1050 Nw_Id 255 "SNA" 2 "AUDIO_TELE" 1 "BODY" 0 "POWERTRAIN" ;
VAL_ 1058 NM_Mode 255 "SNA" 254 "ALIVE" 253 "RING" 252 "LHOM" ;
VAL_ 1058 NM_Successor 255 "SNA" ;
VAL_ 1058 NM_Ud_Launch 63 "SNA" 4 "BROADCAST" ;
VAL_ 1058 NM_Ud_Srv 255 "NO_USER_DATA" 15 "AWAKE_BC" 2 "WAKEUP_SA" ;
VAL_ 1058 WakeupRsn_PTS 255 "SNA" 0 "NETWORK" ;
VAL_ 1058 WakeupCnt 255 "SNA" ;
VAL_ 1058 Nw_Id 255 "SNA" 2 "AUDIO_TELE" 1 "BODY" 0 "POWERTRAIN" ;
VAL_ 1059 NM_Mode 255 "SNA" 254 "ALIVE" 253 "RING" 252 "LHOM" ;
VAL_ 1059 NM_Successor 255 "SNA" ;
VAL_ 1059 NM_Ud_Launch 63 "SNA" 4 "BROADCAST" ;
VAL_ 1059 NM_Ud_Srv 255 "NO_USER_DATA" 15 "AWAKE_BC" 2 "WAKEUP_SA" ;
VAL_ 1059 WakeupRsn_SCCM 255 "SNA" 76 "STW_SW" 73 "HRN_SW" 72 "FP_LVR" 71 "TILT" 0 "NETWORK" ;
VAL_ 1059 WakeupCnt 255 "SNA" ;
VAL_ 1059 Nw_Id 255 "SNA" 2 "AUDIO_TELE" 1 "BODY" 0 "POWERTRAIN" ;
VAL_ 1061 NM_Mode 255 "SNA" 254 "ALIVE" 253 "RING" 252 "LHOM" ;
VAL_ 1061 NM_Successor 255 "SNA" ;
VAL_ 1061 NM_Ud_Launch 63 "SNA" 4 "BROADCAST" ;
VAL_ 1061 NM_Ud_Srv 255 "NO_USER_DATA" 15 "AWAKE_BC" 2 "WAKEUP_SA" ;
VAL_ 1061 WakeupRsn_ANC 255 "SNA" 0 "NETWORK" ;
VAL_ 1061 WakeupCnt 255 "SNA" ;
VAL_ 1061 Nw_Id 255 "SNA" 2 "AUDIO_TELE" 1 "BODY" 0 "POWERTRAIN" ;
VAL_ 1062 NM_Mode 255 "SNA" 254 "ALIVE" 253 "RING" 252 "LHOM" ;
VAL_ 1062 NM_Successor 255 "SNA" ;
VAL_ 1062 NM_Ud_Launch 63 "SNA" 4 "BROADCAST" ;
VAL_ 1062 NM_Ud_Srv 255 "NO_USER_DATA" 15 "AWAKE_BC" 2 "WAKEUP_SA" ;
VAL_ 1062 WakeupRsn_ASCM 255 "SNA" 0 "NETWORK" ;
VAL_ 1062 WakeupCnt 255 "SNA" ;
VAL_ 1062 Nw_Id 255 "SNA" 2 "AUDIO_TELE" 1 "BODY" 0 "POWERTRAIN" ;
VAL_ 1073 NM_Mode 255 "SNA" 254 "ALIVE" 253 "RING" 252 "LHOM" ;
VAL_ 1073 NM_Successor 255 "SNA" ;
VAL_ 1073 NM_Ud_Launch 63 "SNA" 4 "BROADCAST" ;
VAL_ 1073 NM_Ud_Srv 255 "NO_USER_DATA" 15 "AWAKE_BC" 2 "WAKEUP_SA" ;
VAL_ 1073 WakeupRsn_VSIM_C 255 "SNA" 0 "NETWORK" ;
VAL_ 1073 WakeupCnt 255 "SNA" ;
VAL_ 1073 Nw_Id 255 "SNA" 2 "AUDIO_TELE" 1 "BODY" 0 "POWERTRAIN" ;
VAL_ 1098 VC_VehCfg5_Stat 3 "SNA" 2 "REQUEST_DATA" 1 "PROGAMMED" 0 "NA" ;
VAL_ 1098 VC_AmbTempLct 3 "SNA" 1 "DCM" 0 "CBC" ;
VAL_ 1098 VC_Strng_Rt_0 255 "SNA" ;
VAL_ 1098 VC_Strng_Rt_pls1 255 "SNA" ;
VAL_ 1098 VC_Strng_Rt_pls2 255 "SNA" ;
VAL_ 1098 VC_Strng_Rt_pls3 255 "SNA" ;
VAL_ 1098 VC_Strng_Rt_pls4 255 "SNA" ;
VAL_ 1098 VC_Strng_Rt_pls5 255 "SNA" ;
